VERSION ""

NS_ :

BS_:

BU_: VCU_LE CHUD_LE VKM_LE RCRM_LE VPM_LE EDI_LE V2V_LE TCP_LE CSM_LE UHP_Low_LE TouchPad_LE RSE_LE RSC_LE RSA_LE PDIM_LE OTIM_LE ICS_LE LVMPC_LE LVMNav_LE DVB_T_LE ONSTAR_LE HUD_LE IPC_LE RadioHead_LE CHM_LE Dummy_LE CGM_LE AMP_LE

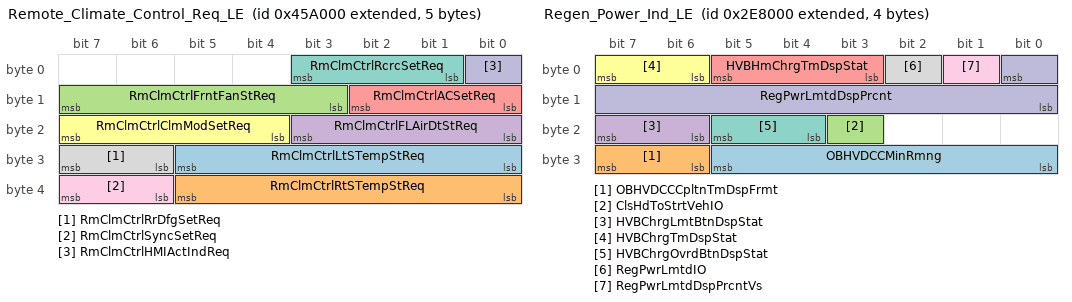
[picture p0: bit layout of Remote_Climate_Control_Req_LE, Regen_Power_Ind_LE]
BO_ 2152046592 Remote_Climate_Control_Req_LE: 5 ONSTAR_LE
 SG_ RmClmCtrlLtSTempStReq : 29|6@0+ (1,0) [0|63] ""  CGM_LE
 SG_ RmClmCtrlRtSTempStReq : 37|6@0+ (1,0) [0|63] ""  CGM_LE
 SG_ RmClmCtrlFrntFanStReq : 15|5@0+ (1,0) [0|31] ""  CGM_LE
 SG_ RmClmCtrlFLAirDtStReq : 19|4@0+ (1,0) [0|15] ""  CGM_LE
 SG_ RmClmCtrlACSetReq : 10|3@0+ (1,0) [0|7] ""  CGM_LE
 SG_ RmClmCtrlClmModSetReq : 23|4@0+ (1,0) [0|15] ""  CGM_LE
 SG_ RmClmCtrlRcrcSetReq : 3|3@0+ (1,0) [0|7] ""  CGM_LE
 SG_ RmClmCtrlRrDfgSetReq : 31|2@0+ (1,0) [0|3] ""  CGM_LE
 SG_ RmClmCtrlSyncSetReq : 39|2@0+ (1,0) [0|3] ""  CGM_LE
 SG_ RmClmCtrlHMIActIndReq : 0|1@0+ (1,0) [0|1] ""  CGM_LE

BO_ 2152030208 Tuner_Frequency_Request_LE: 8 ONSTAR_LE
 SG_ TnrFrqChnlReq : 15|56@0+ (1,0) [0|1] ""  VCU_LE,CSM_LE,RadioHead_LE
 SG_ TnrFrqBndReq : 3|4@0+ (1,0) [0|15] ""  VCU_LE,CSM_LE,RadioHead_LE

BO_ 2150531072 Regen_Power_Ind_LE: 4 CGM_LE
 SG_ OBHVDCCMinRmng : 29|6@0+ (1,0) [0|63] ""  IPC_LE,VCU_LE,RadioHead_LE
 SG_ OBHVDCCCpltnTmDspFrmt : 31|2@0+ (1,0) [0|3] ""  IPC_LE,VCU_LE,RadioHead_LE
 SG_ ClsHdToStrtVehIO : 19|1@0+ (1,0) [0|1] ""  VCU_LE,IPC_LE
 SG_ HVBChrgLmtBtnDspStat : 23|2@0+ (1,0) [0|3] ""  VCU_LE,CSM_LE,RadioHead_LE
 SG_ HVBHmChrgTmDspStat : 5|3@0+ (1,0) [0|7] ""  VCU_LE,CSM_LE,RadioHead_LE
 SG_ HVBChrgTmDspStat : 7|2@0+ (1,0) [0|3] ""  VCU_LE,CSM_LE,RadioHead_LE
 SG_ HVBChrgOvrdBtnDspStat : 21|2@0+ (1,0) [0|3] ""  VCU_LE,CSM_LE,RadioHead_LE
 SG_ RegPwrLmtdIO : 2|1@0+ (1,0) [0|1] ""  VCU_LE,IPC_LE
 SG_ RegPwrLmtdDspPrcntVs : 1|1@0+ (1,0) [0|1] ""  VCU_LE,IPC_LE
 SG_ RegPwrLmtdDspPrcnt : 0|9@0- (0.392157,0) [-100.392192|100.000035] "%"  VCU_LE,IPC_LE

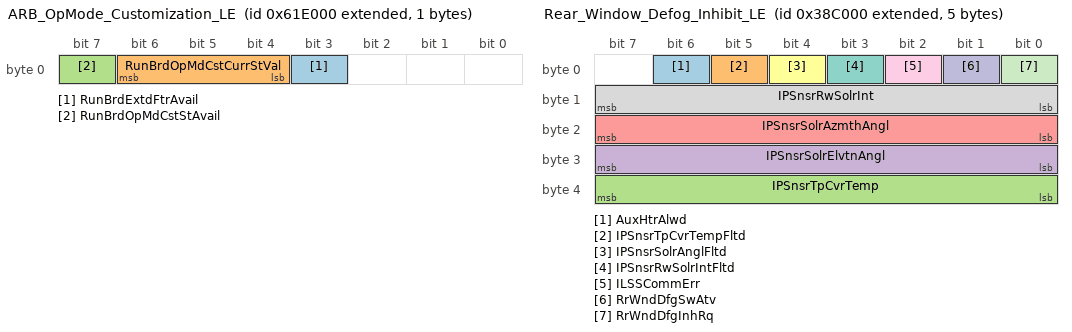
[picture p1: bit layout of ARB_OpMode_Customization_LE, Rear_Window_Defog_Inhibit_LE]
BO_ 2153897984 ARB_OpMode_Customization_LE: 1 CGM_LE
 SG_ RunBrdExtdFtrAvail : 3|1@0+ (1,0) [0|1] ""  VCU_LE,CSM_LE,RadioHead_LE
 SG_ RunBrdOpMdCstCurrStVal : 6|3@0+ (1,0) [0|7] ""  VCU_LE,CSM_LE,RadioHead_LE
 SG_ RunBrdOpMdCstStAvail : 7|1@0+ (1,0) [0|1] ""  VCU_LE,CSM_LE,RadioHead_LE

BO_ 936 Temp_Diag_CAN_Resp_LE_3A8: 8 CGM_LE
 SG_ DgnInf : 7|64@0+ (1,0) [0|1.84467440737096E+019] ""  Dummy_LE

BO_ 856 Temp_Diag_CAN_Resp_LE_358: 8 CGM_LE
 SG_ DgnInf : 7|64@0+ (1,0) [0|1.84467440737096E+019] ""  Dummy_LE

BO_ 872 Temp_Diag_CAN_Resp_LE_368: 8 CGM_LE
 SG_ DgnInf : 7|64@0+ (1,0) [0|1.84467440737096E+019] ""  Dummy_LE

BO_ 864 Temp_Diag_CAN_Resp_LE_360: 8 Dummy_LE
 SG_ DgnInf : 7|64@0+ (1,0) [0|1.84467440737096E+019] ""  CGM_LE

BO_ 921 Temp_Diag_CAN_Resp_LE_399: 8 CGM_LE
 SG_ DgnInf : 7|64@0+ (1,0) [0|1.84467440737096E+019] ""  Dummy_LE

BO_ 2151202816 Rear_Window_Defog_Inhibit_LE: 5 CGM_LE
 SG_ AuxHtrAlwd : 6|1@0+ (1,0) [0|1] ""  Dummy_LE
 SG_ IPSnsrTpCvrTempFltd : 5|1@0+ (1,0) [0|1] ""  Dummy_LE
 SG_ IPSnsrTpCvrTemp : 39|8@0+ (0.5,-40) [-40|87.5] "deg C"  Dummy_LE
 SG_ IPSnsrSolrElvtnAngl : 31|8@0+ (1,0) [0|255] "deg"  Dummy_LE
 SG_ IPSnsrSolrAzmthAngl : 23|8@0+ (2,-180) [-180|330] "deg"  Dummy_LE
 SG_ IPSnsrSolrAnglFltd : 4|1@0+ (1,0) [0|1] ""  Dummy_LE
 SG_ IPSnsrRwSolrIntFltd : 3|1@0+ (1,0) [0|1] ""  Dummy_LE
 SG_ IPSnsrRwSolrInt : 15|8@0+ (3,0) [0|765] "W/m2"  Dummy_LE
 SG_ ILSSCommErr : 2|1@0+ (1,0) [0|1] ""  Dummy_LE
 SG_ RrWndDfgSwAtv : 1|1@0+ (1,0) [0|1] ""  VCU_LE,IPC_LE
 SG_ RrWndDfgInhRq : 0|1@0+ (1,0) [0|1] ""  Dummy_LE

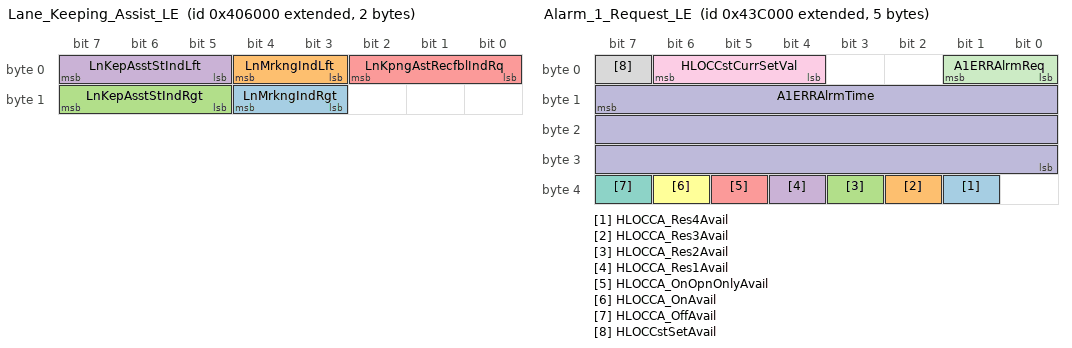
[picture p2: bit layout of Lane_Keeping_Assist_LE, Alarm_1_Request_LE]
BO_ 2151702528 Lane_Keeping_Assist_LE: 2 CGM_LE
 SG_ LnMrkngIndRgt : 12|2@0+ (1,0) [0|3] ""  VCU_LE,IPC_LE
 SG_ LnMrkngIndLft : 4|2@0+ (1,0) [0|3] ""  VCU_LE,IPC_LE
 SG_ LnKepAsstStIndRgt : 15|3@0+ (1,0) [0|7] ""  VCU_LE,IPC_LE
 SG_ LnKepAsstStIndLft : 7|3@0+ (1,0) [0|7] ""  VCU_LE,IPC_LE
 SG_ LnKpngAstRecfblIndRq : 2|3@0+ (1,0) [0|7] ""  VCU_LE,IPC_LE

BO_ 2156978176 PassPhrase_2_AMM_LE: 8 ONSTAR_LE
 SG_ WiFiPssPhrsDgts9to16_Mp : 7|64@0+ (1,0) [0|0] ""  CGM_LE

BO_ 2156969984 PassPhrase_1_AMM_LE: 8 ONSTAR_LE
 SG_ WiFiPssPhrsDgts1to8_Mp : 7|64@0+ (1,0) [0|0] ""  CGM_LE

BO_ 2156961792 SSID_AMM_3_LE: 8 ONSTAR_LE
 SG_ WiFiSSIDDgts17to24_Mp : 7|64@0+ (1,0) [0|0] ""  CGM_LE

BO_ 2151923712 Alarm_1_Request_LE: 5 CGM_LE
 SG_ HLOCCA_Res4Avail : 33|1@0+ (1,0) [0|1] ""  VCU_LE,CSM_LE,RadioHead_LE
 SG_ HLOCCA_Res3Avail : 34|1@0+ (1,0) [0|1] ""  VCU_LE,CSM_LE,RadioHead_LE
 SG_ HLOCCA_Res2Avail : 35|1@0+ (1,0) [0|1] ""  VCU_LE,CSM_LE,RadioHead_LE
 SG_ HLOCCA_Res1Avail : 36|1@0+ (1,0) [0|1] ""  VCU_LE,CSM_LE,RadioHead_LE
 SG_ HLOCCA_OnOpnOnlyAvail : 37|1@0+ (1,0) [0|1] ""  VCU_LE,CSM_LE,RadioHead_LE
 SG_ HLOCCA_OnAvail : 38|1@0+ (1,0) [0|1] ""  VCU_LE,CSM_LE,RadioHead_LE
 SG_ HLOCCA_OffAvail : 39|1@0+ (1,0) [0|1] ""  VCU_LE,CSM_LE,RadioHead_LE
 SG_ HLOCCstSetAvail : 7|1@0+ (1,0) [0|1] ""  VCU_LE,CSM_LE,RadioHead_LE
 SG_ HLOCCstCurrSetVal : 6|3@0+ (1,0) [0|7] ""  VCU_LE,CSM_LE,RadioHead_LE
 SG_ A1ERRAlrmTime : 15|24@0+ (1,0) [0|16777215] "min"  Dummy_LE
 SG_ A1ERRAlrmReq : 1|2@0+ (1,0) [0|3] ""  Dummy_LE

BO_ 2150236160 Unlock_Key_Store_Crypt_2_LE: 8 CGM_LE
 SG_ UlckKyStrCrptoDt2M : 4|1@0+ (1,0) [0|1] ""  CSM_LE
 SG_ UlckKyStrCrptoDt2 : 3|60@0+ (1,0) [0|1.15292150460685E+018] ""  CSM_LE

BO_ 2150170624 Unlock_Key_Store_Crypt_1_LE: 8 CGM_LE
 SG_ UlckKyStrCrptoDt1M : 4|1@0+ (1,0) [0|1] ""  CSM_LE
 SG_ UlckKyStrCrptoDt1 : 3|60@0+ (1,0) [0|1.15292150460685E+018] ""  CSM_LE

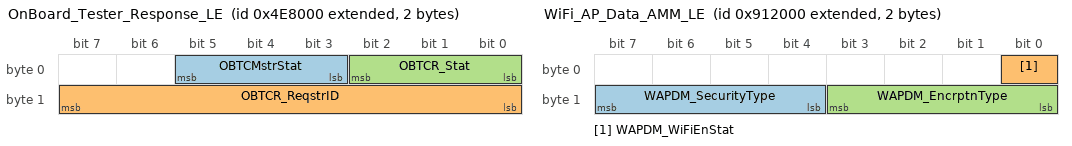
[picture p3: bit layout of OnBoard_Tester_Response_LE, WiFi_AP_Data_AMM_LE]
BO_ 2152628224 OnBoard_Tester_Response_LE: 2 TCP_LE
 SG_ OBTCMstrStat : 5|3@0+ (1,0) [0|7] ""  CSM_LE
 SG_ OBTCR_ReqstrID : 15|8@0+ (1,0) [0|255] ""  CSM_LE
 SG_ OBTCR_Stat : 2|3@0+ (1,0) [0|7] ""  CSM_LE

BO_ 2154725376 Auxiliary_Heater_LE: 1 CGM_LE
 SG_ AuxHtrAtv378 : 6|1@0+ (1,0) [0|1] ""  RSC_LE,Dummy_LE
 SG_ AuxHtrRq : 7|1@0+ (1,0) [0|1] ""  RSC_LE,Dummy_LE

BO_ 2157051904 WiFi_Station_AMM_LE: 5 CGM_LE
 SG_ WSMR_WiFiStnMpMACAddr : 15|32@0+ (1,0) [0|4294967295] ""  CSM_LE,ONSTAR_LE
 SG_ WSMR_WiFiAssnReq : 1|2@0+ (1,0) [0|3] ""  CSM_LE,ONSTAR_LE

BO_ 2156994560 WiFi_AP_Data_AMM_LE: 2 ONSTAR_LE
 SG_ WAPDM_SecurityType : 15|4@0+ (1,0) [0|15] ""  CGM_LE
 SG_ WAPDM_WiFiEnStat : 0|1@0+ (1,0) [0|1] ""  CGM_LE
 SG_ WAPDM_EncrptnType : 11|4@0+ (1,0) [0|15] ""  CGM_LE

BO_ 2156986368 PassPhrase_3_AMM_LE: 8 ONSTAR_LE
 SG_ WiFiPssPhrsDgts17to24_Mp : 7|64@0+ (1,0) [0|0] ""  CGM_LE

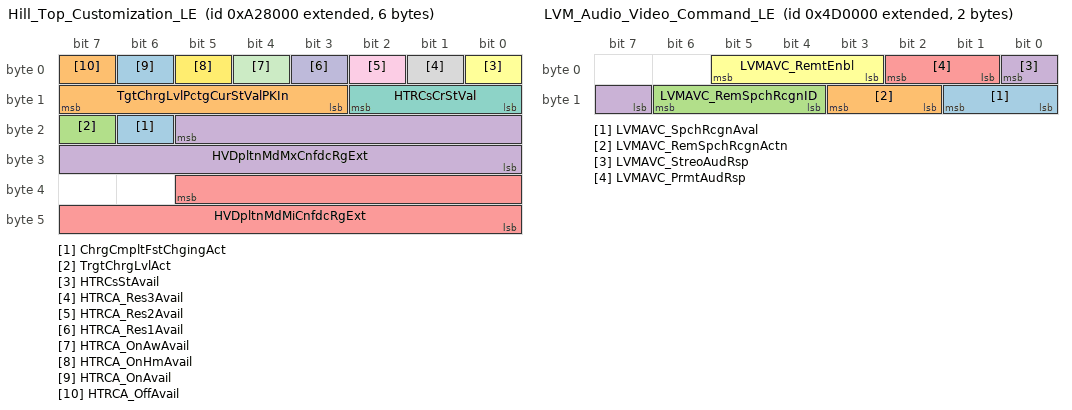
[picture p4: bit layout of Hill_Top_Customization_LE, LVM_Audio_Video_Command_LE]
BO_ 2158133248 Hill_Top_Customization_LE: 6 CGM_LE
 SG_ ChrgCmpltFstChgingAct : 22|1@0+ (1,0) [0|1] ""  CSM_LE,RadioHead_LE,VCU_LE,IPC_LE
 SG_ TgtChrgLvlPctgCurStValPKIn : 15|5@0+ (1,0) [0|20] ""  VCU_LE,IPC_LE
 SG_ TrgtChrgLvlAct : 23|1@0+ (1,0) [0|1] ""  VCU_LE,IPC_LE
 SG_ HVDpltnMdMxCnfdcRgExt : 21|14@0+ (0.1,0) [0|1638.3] "km"  TCP_LE,ONSTAR_LE,VCU_LE,IPC_LE
 SG_ HVDpltnMdMiCnfdcRgExt : 37|14@0+ (0.1,0) [0|1638.3] "km"  TCP_LE,ONSTAR_LE,VCU_LE,IPC_LE
 SG_ HTRCsStAvail : 0|1@0+ (1,0) [0|1] ""  VCU_LE,CSM_LE,RadioHead_LE
 SG_ HTRCsCrStVal : 10|3@0+ (1,0) [0|7] ""  VCU_LE,CSM_LE,RadioHead_LE
 SG_ HTRCA_Res3Avail : 1|1@0+ (1,0) [0|1] ""  VCU_LE,CSM_LE,RadioHead_LE
 SG_ HTRCA_Res2Avail : 2|1@0+ (1,0) [0|1] ""  VCU_LE,CSM_LE,RadioHead_LE
 SG_ HTRCA_Res1Avail : 3|1@0+ (1,0) [0|1] ""  VCU_LE,CSM_LE,RadioHead_LE
 SG_ HTRCA_OnAwAvail : 4|1@0+ (1,0) [0|1] ""  VCU_LE,CSM_LE,RadioHead_LE
 SG_ HTRCA_OnHmAvail : 5|1@0+ (1,0) [0|1] ""  VCU_LE,CSM_LE,RadioHead_LE
 SG_ HTRCA_OnAvail : 6|1@0+ (1,0) [0|1] ""  VCU_LE,CSM_LE,RadioHead_LE
 SG_ HTRCA_OffAvail : 7|1@0+ (1,0) [0|1] ""  VCU_LE,CSM_LE,RadioHead_LE

BO_ 2154651648 Telematics_Audio_Control_LE: 1 CSM_LE
 SG_ TAC_AudConctOutcm : 3|4@0+ (1,0) [0|15] ""  VPM_LE,TCP_LE
 SG_ TAC_AudChConctStat : 7|4@0+ (1,0) [0|15] ""  VPM_LE,TCP_LE

BO_ 2154635264 Telematics_Audio_Request_LE: 1 TCP_LE
 SG_ TAR_AudSrcStat : 3|4@0+ (1,0) [0|15] ""  VCU_LE,VPM_LE,CSM_LE
 SG_ TAR_AudConctReq : 7|4@0+ (1,0) [0|15] ""  VCU_LE,VPM_LE,CSM_LE

BO_ 2152529920 LVM_Audio_Video_Command_LE: 2 CSM_LE
 SG_ LVMAVC_SpchRcgnAval : 9|2@0+ (1,0) [0|3] ""  LVMPC_LE,LVMNav_LE
 SG_ LVMAVC_RemSpchRcgnActn : 11|2@0+ (1,0) [0|3] ""  LVMPC_LE,LVMNav_LE
 SG_ LVMAVC_RemSpchRcgnID : 14|3@0+ (1,0) [0|7] ""  LVMPC_LE,LVMNav_LE
 SG_ LVMAVC_StreoAudRsp : 0|2@0+ (1,0) [0|3] ""  LVMPC_LE,LVMNav_LE
 SG_ LVMAVC_PrmtAudRsp : 2|2@0+ (1,0) [0|3] ""  LVMPC_LE,LVMNav_LE
 SG_ LVMAVC_RemtEnbl : 5|3@0+ (1,0) [0|7] ""  LVMPC_LE,LVMNav_LE

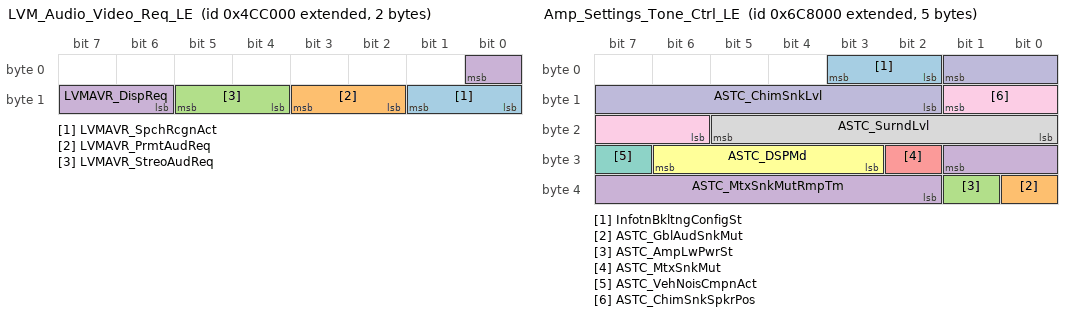
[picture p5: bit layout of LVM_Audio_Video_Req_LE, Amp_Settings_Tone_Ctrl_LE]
BO_ 2152513536 LVM_Audio_Video_Req_LE: 2 LVMNav_LE
 SG_ LVMAVR_SpchRcgnAct : 9|2@0+ (1,0) [0|3] ""  CSM_LE
 SG_ LVMAVR_PrmtAudReq : 11|2@0+ (1,0) [0|3] ""  CSM_LE
 SG_ LVMAVR_StreoAudReq : 13|2@0+ (1,0) [0|3] ""  CSM_LE
 SG_ LVMAVR_DispReq : 0|3@0+ (1,0) [0|7] ""  CSM_LE

BO_ 2154889216 Cluster_HMI_Animation_Req_LE: 1 CSM_LE
 SG_ RSIHMIAnmReq : 4|3@0+ (1,0) [0|7] ""  RSE_LE
 SG_ ClstrHMIAnmReq : 7|3@0+ (1,0) [0|7] ""  VCU_LE,IPC_LE

BO_ 2154872832 Infotainment_Activation_Req_LE: 1 TCP_LE
 SG_ RmRflshUpdtAvail : 6|1@0+ (1,0) [0|1] ""  VCU_LE,CSM_LE
 SG_ InfoActvnReq : 7|1@0+ (1,0) [0|1] ""  VCU_LE,CSM_LE

BO_ 2154569728 Infotainment_System_State_LE: 1 CSM_LE
 SG_ InfotnmntSysSt : 7|5@0+ (1,0) [0|31] ""  CHUD_LE,CGM_LE,VCU_LE,TouchPad_LE,RSE_LE,RSC_LE,ICS_LE,LVMPC_LE,LVMNav_LE,IPC_LE,AMP_LE,TCP_LE

BO_ 2154594304 Amp_Settings_Tone_Ctrl_LE: 5 CSM_LE
 SG_ InfotnBkltngConfigSt : 3|2@0+ (1,0) [0|3] ""  RSE_LE,TouchPad_LE
 SG_ ASTC_GblAudSnkMut : 32|1@0+ (1,0) [0|1] ""  AMP_LE
 SG_ ASTC_AmpLwPwrSt : 33|1@0+ (1,0) [0|1] ""  AMP_LE
 SG_ ASTC_MtxSnkMutRmpTm : 25|8@0+ (5,0) [0|1275] "ms"  AMP_LE
 SG_ ASTC_MtxSnkMut : 26|1@0+ (1,0) [0|1] ""  AMP_LE
 SG_ ASTC_DSPMd : 30|4@0+ (1,0) [0|15] ""  AMP_LE
 SG_ ASTC_VehNoisCmpnAct : 31|1@0+ (1,0) [0|1] ""  AMP_LE
 SG_ ASTC_SurndLvl : 21|6@0- (1,0) [-32|31] ""  AMP_LE
 SG_ ASTC_ChimSnkSpkrPos : 9|4@0+ (1,0) [0|15] ""  AMP_LE
 SG_ ASTC_ChimSnkLvl : 1|8@0+ (0.5,-127.5) [-127.5|0] "dB"  AMP_LE

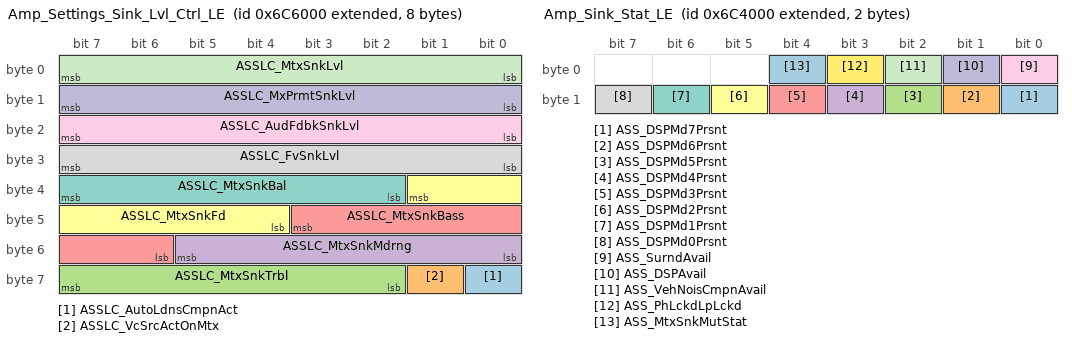
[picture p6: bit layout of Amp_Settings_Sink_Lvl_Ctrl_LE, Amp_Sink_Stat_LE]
BO_ 2154586112 Amp_Settings_Sink_Lvl_Ctrl_LE: 8 CSM_LE
 SG_ ASSLC_AutoLdnsCmpnAct : 56|1@0+ (1,0) [0|1] ""  AMP_LE
 SG_ ASSLC_VcSrcActOnMtx : 57|1@0+ (1,0) [0|1] ""  AMP_LE
 SG_ ASSLC_MtxSnkTrbl : 63|6@0- (1,0) [-32|31] ""  AMP_LE
 SG_ ASSLC_MtxSnkMdrng : 53|6@0- (1,0) [-32|31] ""  AMP_LE
 SG_ ASSLC_MtxSnkBass : 43|6@0- (1,0) [-32|31] ""  AMP_LE
 SG_ ASSLC_MtxSnkFd : 33|6@0- (1,0) [-32|31] ""  AMP_LE
 SG_ ASSLC_MtxSnkBal : 39|6@0- (1,0) [-32|31] ""  AMP_LE
 SG_ ASSLC_FvSnkLvl : 31|8@0+ (0.5,-127.5) [-127.5|0] "dB"  AMP_LE
 SG_ ASSLC_AudFdbkSnkLvl : 23|8@0+ (0.5,-127.5) [-127.5|0] "dB"  AMP_LE
 SG_ ASSLC_MxPrmtSnkLvl : 15|8@0+ (0.5,-127.5) [-127.5|0] "dB"  AMP_LE
 SG_ ASSLC_MtxSnkLvl : 7|8@0+ (0.5,-127.5) [-127.5|0] "dB"  AMP_LE

BO_ 2154577920 Amp_Sink_Stat_LE: 2 AMP_LE
 SG_ ASS_DSPMd7Prsnt : 8|1@0+ (1,0) [0|1] ""  CSM_LE
 SG_ ASS_DSPMd6Prsnt : 9|1@0+ (1,0) [0|1] ""  CSM_LE
 SG_ ASS_DSPMd5Prsnt : 10|1@0+ (1,0) [0|1] ""  CSM_LE
 SG_ ASS_DSPMd4Prsnt : 11|1@0+ (1,0) [0|1] ""  CSM_LE
 SG_ ASS_DSPMd3Prsnt : 12|1@0+ (1,0) [0|1] ""  CSM_LE
 SG_ ASS_DSPMd2Prsnt : 13|1@0+ (1,0) [0|1] ""  CSM_LE
 SG_ ASS_DSPMd1Prsnt : 14|1@0+ (1,0) [0|1] ""  CSM_LE
 SG_ ASS_DSPMd0Prsnt : 15|1@0+ (1,0) [0|1] ""  CSM_LE
 SG_ ASS_SurndAvail : 0|1@0+ (1,0) [0|1] ""  CSM_LE
 SG_ ASS_DSPAvail : 1|1@0+ (1,0) [0|1] ""  CSM_LE
 SG_ ASS_VehNoisCmpnAvail : 2|1@0+ (1,0) [0|1] ""  CSM_LE
 SG_ ASS_PhLckdLpLckd : 3|1@0+ (1,0) [0|1] ""  CSM_LE
 SG_ ASS_MtxSnkMutStat : 4|1@0+ (1,0) [0|1] ""  CSM_LE

BO_ 2151931904 Custom_Launch_Ctrl_LE: 8 CGM_LE
 SG_ FourWhlDrvIdReqExtRng : 59|4@0+ (1,0) [0|15] ""  VCU_LE,IPC_LE
 SG_ LnchCtrlTmrVal : 35|4@0+ (1,0) [0|15] ""  VCU_LE,IPC_LE
 SG_ LnchCtrlBrkPresVal : 47|4@0+ (10,0) [0|150] "%"  VCU_LE,IPC_LE
 SG_ FuelMdTrnstnIndReq : 63|4@0+ (1,0) [0|15] ""  VCU_LE,IPC_LE
 SG_ BiFuelRflGaslinIndReq : 42|3@0+ (1,0) [0|7] ""  VCU_LE,IPC_LE
 SG_ AutoShtdwnTmr : 55|8@0+ (1,0) [0|255] "min"  VCU_LE,IPC_LE
 SG_ AutoShtdwnIO : 43|1@0+ (1,0) [0|1] ""  VCU_LE,IPC_LE
 SG_ TCSTempDsblReqIO : 24|1@0+ (1,0) [0|1] ""  VCU_LE,IPC_LE
 SG_ VehStbCmptvMdCstAvl : 25|1@0+ (1,0) [0|1] ""  VCU_LE,IPC_LE
 SG_ VehStbEnmntCstAvl : 26|1@0+ (1,0) [0|1] ""  VCU_LE,IPC_LE
 SG_ TCSysCstAvl : 27|1@0+ (1,0) [0|1] ""  VCU_LE,IPC_LE
 SG_ VehStbCmptvMdCurSt : 28|1@0+ (1,0) [0|1] ""  VCU_LE,IPC_LE
 SG_ VehStbEnhmntCurSt : 36|1@0+ (1,0) [0|1] ""  VCU_LE,IPC_LE
 SG_ TCSysCurSt : 37|1@0+ (1,0) [0|1] ""  VCU_LE,IPC_LE
 SG_ TracAndStbScrnCnfg : 39|2@0+ (1,0) [0|3] ""  VCU_LE,IPC_LE
 SG_ ElctShfPriLtdPerfMdIO : 29|1@0+ (1,0) [0|1] ""  VCU_LE,IPC_LE
 SG_ LnchCtrlEngRPMStat : 15|6@0+ (1,0) [0|63] ""  VCU_LE,IPC_LE
 SG_ RegVltCtlEngyRcvryAct : 30|1@0+ (1,0) [0|1] ""  VCU_LE,IPC_LE
 SG_ VehSpdCntlSystmType : 20|3@0+ (1,0) [0|7] ""  V2V_LE,VCU_LE,IPC_LE
 SG_ ACCSysSltdMdDispIO : 31|1@0+ (1,0) [0|1] ""  V2V_LE,VCU_LE,IPC_LE
 SG_ ACCSysSltdMd : 17|2@0+ (1,0) [0|3] ""  V2V_LE,VCU_LE,IPC_LE
 SG_ PTExPrtclFltWrng3IO : 8|1@0+ (1,0) [0|1] ""  VCU_LE,IPC_LE
 SG_ PTExPartFltManRegStat : 23|3@0+ (1,0) [0|7] ""  VCU_LE,IPC_LE
 SG_ LnchCtrlWhlSlpStat : 7|5@0+ (1,0) [0|31] ""  VCU_LE,IPC_LE
 SG_ LnchCtrlMdStat : 2|3@0+ (1,0) [0|7] ""  VCU_LE,IPC_LE
 SG_ AWDRecmndIO : 9|1@0+ (1,0) [0|1] ""  VCU_LE,IPC_LE

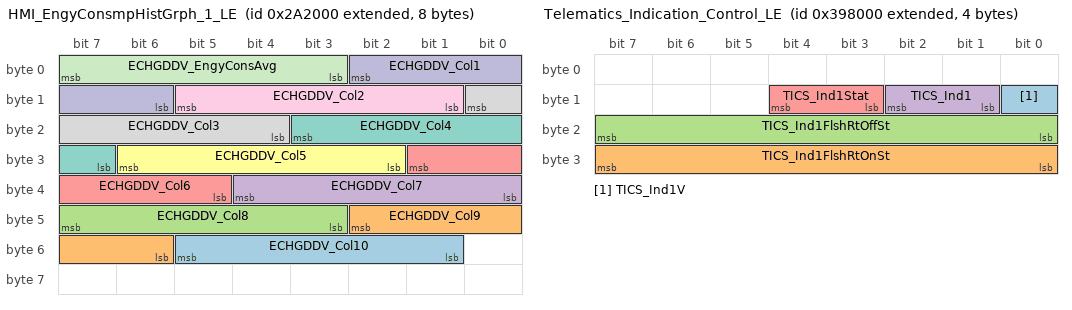
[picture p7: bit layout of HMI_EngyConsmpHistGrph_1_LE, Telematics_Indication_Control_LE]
BO_ 2150244352 HMI_EngyConsmpHistGrph_1_LE: 8 CGM_LE
 SG_ ECHGDDV_Col10 : 53|5@0+ (1,0) [0|31] ""  VCU_LE,CSM_LE,RadioHead_LE
 SG_ ECHGDDV_Col9 : 42|5@0+ (1,0) [0|31] ""  VCU_LE,CSM_LE,RadioHead_LE
 SG_ ECHGDDV_Col8 : 47|5@0+ (1,0) [0|31] ""  VCU_LE,CSM_LE,RadioHead_LE
 SG_ ECHGDDV_Col7 : 36|5@0+ (1,0) [0|31] ""  VCU_LE,CSM_LE,RadioHead_LE
 SG_ ECHGDDV_Col6 : 25|5@0+ (1,0) [0|31] ""  VCU_LE,CSM_LE,RadioHead_LE
 SG_ ECHGDDV_Col5 : 30|5@0+ (1,0) [0|31] ""  VCU_LE,CSM_LE,RadioHead_LE
 SG_ ECHGDDV_Col4 : 19|5@0+ (1,0) [0|31] ""  VCU_LE,CSM_LE,RadioHead_LE
 SG_ ECHGDDV_Col3 : 8|5@0+ (1,0) [0|31] ""  VCU_LE,CSM_LE,RadioHead_LE
 SG_ ECHGDDV_Col2 : 13|5@0+ (1,0) [0|31] ""  VCU_LE,CSM_LE,RadioHead_LE
 SG_ ECHGDDV_Col1 : 2|5@0+ (1,0) [0|31] ""  VCU_LE,CSM_LE,RadioHead_LE
 SG_ ECHGDDV_EngyConsAvg : 7|5@0+ (1,0) [0|31] ""  VCU_LE,CSM_LE,RadioHead_LE

BO_ 2156953600 SSID_AMM_2_LE: 8 ONSTAR_LE
 SG_ WiFiSSIDDgts9to16_Mp : 7|64@0+ (1,0) [0|0] ""  CGM_LE

BO_ 1363 UUDT_Resp_From_TIM_CGM_LE: 8 CGM_LE
 SG_ DgnInf_LS553 : 7|64@0+ (1,0) [0|1.84467440737096E+019] ""  CSM_LE,TCP_LE,ONSTAR_LE

BO_ 1619 USDT_Resp_From_TIM_CGM_LE: 8 CGM_LE
 SG_ DgnInf : 7|64@0+ (1,0) [0|1.84467440737096E+019] ""  CSM_LE,TCP_LE,ONSTAR_LE

BO_ 597 USDT_Req_to_VIS2_LE: 8 ONSTAR_LE
 SG_ DgnInf : 7|64@0+ (1,0) [0|1.84467440737096E+019] ""  TCP_LE,ONSTAR_LE,CGM_LE

BO_ 2020 USDT_Req_to_VICM_LE: 8 ONSTAR_LE
 SG_ DgnInf : 7|64@0+ (1,0) [0|1.84467440737096E+019] ""  TCP_LE,ONSTAR_LE,CGM_LE

BO_ 601 USDT_Req_to_UPA_APA_LE: 8 ONSTAR_LE
 SG_ DgnInf : 7|64@0+ (1,0) [0|1.84467440737096E+019] ""  TCP_LE,ONSTAR_LE,CGM_LE

BO_ 583 USDT_Req_to_SDM_LE: 8 ONSTAR_LE
 SG_ DgnInf : 7|64@0+ (1,0) [0|1.84467440737096E+019] ""  TCP_LE,ONSTAR_LE,CGM_LE

BO_ 604 USDT_Req_to_SCL_LE: 8 ONSTAR_LE
 SG_ DgnInf : 7|64@0+ (1,0) [0|1.84467440737096E+019] ""  TCP_LE,ONSTAR_LE,CGM_LE

BO_ 599 USDT_Req_to_SBZA_R_LE: 8 ONSTAR_LE
 SG_ DgnInf : 7|64@0+ (1,0) [0|1.84467440737096E+019] ""  TCP_LE,ONSTAR_LE,CGM_LE

BO_ 602 USDT_Req_to_SBZA_L_LE: 8 ONSTAR_LE
 SG_ DgnInf : 7|64@0+ (1,0) [0|1.84467440737096E+019] ""  TCP_LE,ONSTAR_LE,CGM_LE

BO_ 591 USDT_Req_to_PTM_STC_LE: 8 ONSTAR_LE
 SG_ DgnInf : 7|64@0+ (1,0) [0|1.84467440737096E+019] ""  TCP_LE,ONSTAR_LE,CGM_LE

BO_ 578 USDT_Req_to_PEPS_PBSM_LE: 8 ONSTAR_LE
 SG_ DgnInf : 7|64@0+ (1,0) [0|1.84467440737096E+019] ""  TCP_LE,ONSTAR_LE,CGM_LE

BO_ 600 USDT_Req_to_HVSM_R_LE: 8 ONSTAR_LE
 SG_ DgnInf : 7|64@0+ (1,0) [0|1.84467440737096E+019] ""  TCP_LE,ONSTAR_LE,CGM_LE

BO_ 607 USDT_Req_to_HBSM_LE: 8 ONSTAR_LE
 SG_ DgnInf : 7|64@0+ (1,0) [0|1.84467440737096E+019] ""  TCP_LE,ONSTAR_LE,RCRM_LE,CGM_LE

BO_ 587 USDT_Req_to_FCM_LE: 8 ONSTAR_LE
 SG_ DgnInf : 7|64@0+ (1,0) [0|1.84467440737096E+019] ""  TCP_LE,ONSTAR_LE,CGM_LE

BO_ 593 USDT_Req_to_ECC_HVAC_LE: 8 ONSTAR_LE
 SG_ DgnInf : 7|64@0+ (1,0) [0|1.84467440737096E+019] ""  TCP_LE,ONSTAR_LE,CGM_LE

BO_ 605 USDT_Req_to_DSM_LE: 8 ONSTAR_LE
 SG_ DgnInf : 7|64@0+ (1,0) [0|1.84467440737096E+019] ""  TCP_LE,ONSTAR_LE,CGM_LE

BO_ 577 USDT_Req_to_BCM_LE: 8 ONSTAR_LE
 SG_ DgnInf : 7|64@0+ (1,0) [0|1.84467440737096E+019] ""  TCP_LE,ONSTAR_LE,CGM_LE

BO_ 603 USDT_Req_to_ARB_LE: 8 ONSTAR_LE
 SG_ DgnInf : 7|64@0+ (1,0) [0|1.84467440737096E+019] ""  TCP_LE,ONSTAR_LE,V2V_LE,CGM_LE

BO_ 581 USDT_Req_to_AOS_LE: 8 ONSTAR_LE
 SG_ DgnInf : 7|64@0+ (1,0) [0|1.84467440737096E+019] ""  TCP_LE,ONSTAR_LE,CGM_LE

BO_ 606 USDT_Req_to_AHS_LE: 8 ONSTAR_LE
 SG_ DgnInf : 7|64@0+ (1,0) [0|1.84467440737096E+019] ""  TCP_LE,ONSTAR_LE,CGM_LE

BO_ 579 USDT_Req_to_AGC_LE: 8 ONSTAR_LE
 SG_ DgnInf : 7|64@0+ (1,0) [0|1.84467440737096E+019] ""  TCP_LE,ONSTAR_LE,CGM_LE

BO_ 1621 USDT_Resp_From_VIS2_LE: 8 CGM_LE
 SG_ DgnInf : 7|64@0+ (1,0) [0|1.84467440737096E+019] ""  CSM_LE,TCP_LE,ONSTAR_LE

BO_ 2028 USDT_Resp_From_VICM_LE: 8 CGM_LE
 SG_ DgnInf : 7|64@0+ (1,0) [0|1.84467440737096E+019] ""  CSM_LE,TCP_LE,ONSTAR_LE

BO_ 1625 USDT_Resp_From_UPA_APA_LE: 8 CGM_LE
 SG_ DgnInf : 7|64@0+ (1,0) [0|1.84467440737096E+019] ""  CSM_LE,TCP_LE,ONSTAR_LE

BO_ 1607 USDT_Resp_From_SDM_LE: 8 CGM_LE
 SG_ DgnInf : 7|64@0+ (1,0) [0|1.84467440737096E+019] ""  CSM_LE,TCP_LE,ONSTAR_LE

BO_ 1628 USDT_Resp_From_SCL_LE: 8 CGM_LE
 SG_ DgnInf : 7|64@0+ (1,0) [0|1.84467440737096E+019] ""  CSM_LE,TCP_LE,ONSTAR_LE

BO_ 1623 USDT_Resp_From_SBZA_R_LE: 8 CGM_LE
 SG_ DgnInf : 7|64@0+ (1,0) [0|1.84467440737096E+019] ""  CSM_LE,TCP_LE,ONSTAR_LE

BO_ 1626 USDT_Resp_From_SBZA_L_LE: 8 CGM_LE
 SG_ DgnInf : 7|64@0+ (1,0) [0|1.84467440737096E+019] ""  CSM_LE,TCP_LE,ONSTAR_LE

BO_ 1615 USDT_Resp_From_PTM_STC_LE: 8 CGM_LE
 SG_ DgnInf : 7|64@0+ (1,0) [0|1.84467440737096E+019] ""  CSM_LE,TCP_LE,ONSTAR_LE

BO_ 1602 USDT_Resp_From_PEPS_PBSM_LE: 8 CGM_LE
 SG_ DgnInf : 7|64@0+ (1,0) [0|1.84467440737096E+019] ""  CSM_LE,TCP_LE,ONSTAR_LE

BO_ 1624 USDT_Resp_From_HVSM_R_LE: 8 CGM_LE
 SG_ DgnInf : 7|64@0+ (1,0) [0|1.84467440737096E+019] ""  CSM_LE,TCP_LE,ONSTAR_LE

BO_ 1631 USDT_Resp_From_HBSM_LE: 8 CGM_LE
 SG_ DgnInf : 7|64@0+ (1,0) [0|1.84467440737096E+019] ""  CGM_LE,CSM_LE,TCP_LE,ONSTAR_LE

BO_ 1611 USDT_Resp_From_FCM_LE: 8 CGM_LE
 SG_ DgnInf : 7|64@0+ (1,0) [0|1.84467440737096E+019] ""  CSM_LE,TCP_LE,ONSTAR_LE

BO_ 1617 USDT_Resp_From_ECC_HVAC_LE: 8 CGM_LE
 SG_ DgnInf : 7|64@0+ (1,0) [0|1.84467440737096E+019] ""  CSM_LE,TCP_LE,ONSTAR_LE

BO_ 1629 USDT_Resp_From_DSM_LE: 8 CGM_LE
 SG_ DgnInf : 7|64@0+ (1,0) [0|1.84467440737096E+019] ""  CSM_LE,TCP_LE,ONSTAR_LE

BO_ 1601 USDT_Resp_From_BCM_LE: 8 CGM_LE
 SG_ DgnInf : 7|64@0+ (1,0) [0|1.84467440737096E+019] ""  CSM_LE,TCP_LE,ONSTAR_LE

BO_ 1627 USDT_Resp_From_ARB_LE: 8 CGM_LE
 SG_ DgnInf : 7|64@0+ (1,0) [0|1.84467440737096E+019] ""  CGM_LE,CSM_LE,TCP_LE,ONSTAR_LE

BO_ 1605 USDT_Resp_From_AOS_LE: 8 CGM_LE
 SG_ DgnInf : 7|64@0+ (1,0) [0|1.84467440737096E+019] ""  CSM_LE,TCP_LE,ONSTAR_LE

BO_ 1630 USDT_Resp_From_AHS_LE: 8 CGM_LE
 SG_ DgnInf : 7|64@0+ (1,0) [0|1.84467440737096E+019] ""  CSM_LE,TCP_LE,ONSTAR_LE

BO_ 1603 USDT_Resp_From_AGC_LE: 8 CGM_LE
 SG_ DgnInf : 7|64@0+ (1,0) [0|1.84467440737096E+019] ""  CSM_LE,TCP_LE,ONSTAR_LE

BO_ 1365 UUDT_Resp_From_VIS2_LE: 8 CGM_LE
 SG_ DgnInf_LS555 : 7|64@0+ (1,0) [0|1.84467440737096E+019] ""  CSM_LE,TCP_LE,ONSTAR_LE

BO_ 1516 UUDT_Resp_From_VICM_LE: 8 CGM_LE
 SG_ DgnInf_LS5EC : 7|64@0+ (1,0) [0|1.84467440737096E+019] ""  CSM_LE,TCP_LE,ONSTAR_LE

BO_ 1369 UUDT_Resp_From_UPA_APA_LE: 8 CGM_LE
 SG_ DgnInf_LS559 : 7|64@0+ (1,0) [0|1.84467440737096E+019] ""  CSM_LE,TCP_LE,ONSTAR_LE

BO_ 1351 UUDT_Resp_From_SDM_LE: 8 CGM_LE
 SG_ DgnInf_LS547 : 7|64@0+ (1,0) [0|1.84467440737096E+019] ""  CSM_LE,TCP_LE,ONSTAR_LE

BO_ 1372 UUDT_Resp_From_SCL_LE: 8 CGM_LE
 SG_ DgnInf_LS55C : 7|64@0+ (1,0) [0|1.84467440737096E+019] ""  CSM_LE,TCP_LE,ONSTAR_LE

BO_ 1367 UUDT_Resp_From_SBZA_R_LE: 8 CGM_LE
 SG_ DgnInf_LS557 : 7|64@0+ (1,0) [0|1.84467440737096E+019] ""  CSM_LE,TCP_LE,ONSTAR_LE

BO_ 1370 UUDT_Resp_From_SBZA_L_LE: 8 CGM_LE
 SG_ DgnInf_LS55A : 7|64@0+ (1,0) [0|1.84467440737096E+019] ""  CSM_LE,TCP_LE,ONSTAR_LE

BO_ 1359 UUDT_Resp_From_PTM_STC_LE: 8 CGM_LE
 SG_ DgnInf_LS54F : 7|64@0+ (1,0) [0|1.84467440737096E+019] ""  CSM_LE,TCP_LE,ONSTAR_LE

BO_ 1346 UUDT_Resp_From_PEPS_PBSM_LE: 8 CGM_LE
 SG_ DgnInf_LS542 : 7|64@0+ (1,0) [0|1.84467440737096E+019] ""  CSM_LE,TCP_LE,ONSTAR_LE

BO_ 1368 UUDT_Resp_From_HVSM_R_LE: 8 CGM_LE
 SG_ DgnInf_LS558 : 7|64@0+ (1,0) [0|1.84467440737096E+019] ""  CSM_LE,TCP_LE,ONSTAR_LE

BO_ 1375 UUDT_Resp_From_HBSM_LE: 8 CGM_LE
 SG_ DgnInf_LS55F : 7|64@0+ (1,0) [0|1.84467440737096E+019] ""  CGM_LE,CSM_LE,TCP_LE,ONSTAR_LE

BO_ 1355 UUDT_Resp_From_FCM_LE: 8 CGM_LE
 SG_ DgnInf_LS54B : 7|64@0+ (1,0) [0|1.84467440737096E+019] ""  CSM_LE,TCP_LE,ONSTAR_LE

BO_ 1361 UUDT_Resp_From_ECC_HVAC_LE: 8 CGM_LE
 SG_ DgnInf_LS551 : 7|64@0+ (1,0) [0|1.84467440737096E+019] ""  CSM_LE,TCP_LE,ONSTAR_LE

BO_ 1373 UUDT_Resp_From_DSM_LE: 8 CGM_LE
 SG_ DgnInf_LS55D : 7|64@0+ (1,0) [0|1.84467440737096E+019] ""  CSM_LE,TCP_LE,ONSTAR_LE

BO_ 1345 UUDT_Resp_From_BCM_LE: 8 CGM_LE
 SG_ DgnInf_LS541 : 7|64@0+ (1,0) [0|1.84467440737096E+019] ""  CSM_LE,TCP_LE,ONSTAR_LE

BO_ 1371 UUDT_Resp_From_ARB_LE: 8 CGM_LE
 SG_ DgnInf_LS55B : 7|64@0+ (1,0) [0|1.84467440737096E+019] ""  CGM_LE,CSM_LE,TCP_LE,ONSTAR_LE

BO_ 1349 UUDT_Resp_From_AOS_LE: 8 CGM_LE
 SG_ DgnInf_LS545 : 7|64@0+ (1,0) [0|1.84467440737096E+019] ""  CSM_LE,TCP_LE,ONSTAR_LE

BO_ 1374 UUDT_Resp_From_AHS_LE: 8 CGM_LE
 SG_ DgnInf_LS55E : 7|64@0+ (1,0) [0|1.84467440737096E+019] ""  CSM_LE,TCP_LE,ONSTAR_LE

BO_ 1347 UUDT_Resp_From_AGC_LE: 8 CGM_LE
 SG_ DgnInf_LS543 : 7|64@0+ (1,0) [0|1.84467440737096E+019] ""  CSM_LE,TCP_LE,ONSTAR_LE

BO_ 1599 VNMF_LE_63F_HBSM: 8 CGM_LE
 SG_ VectraSpcNWMgtD : 7|64@0+ (1,0) [0|1.84467440737096E+019] ""  CGM_LE,V2V_LE,TCP_LE,UHP_Low_LE,LVMNav_LE,ONSTAR_LE,VKM_LE,RSC_LE,RSE_LE,RSA_LE,VCU_LE,CSM_LE,RadioHead_LE,CHM_LE,PDIM_LE,OTIM_LE,CHUD_LE,LVMPC_LE,IPC_LE,ICS_LE,VPM_LE,HUD_LE,TouchPad_LE,DVB_T_LE,AMP_LE

BO_ 1598 VNMF_LE_63E_AHS: 8 CGM_LE
 SG_ VectraSpcNWMgtD : 7|64@0+ (1,0) [0|1.84467440737096E+019] ""  RCRM_LE,V2V_LE,TCP_LE,UHP_Low_LE,LVMNav_LE,ONSTAR_LE,VKM_LE,RSC_LE,RSE_LE,RSA_LE,VCU_LE,CSM_LE,RadioHead_LE,CHM_LE,PDIM_LE,OTIM_LE,CHUD_LE,LVMPC_LE,IPC_LE,ICS_LE,VPM_LE,HUD_LE,TouchPad_LE,DVB_T_LE,AMP_LE

BO_ 1597 VNMF_LE_63D_DSM_HVSM_F: 8 CGM_LE
 SG_ VectraSpcNWMgtD : 7|64@0+ (1,0) [0|1.84467440737096E+019] ""  RCRM_LE,V2V_LE,TCP_LE,UHP_Low_LE,LVMNav_LE,ONSTAR_LE,VKM_LE,RSC_LE,RSE_LE,RSA_LE,VCU_LE,CSM_LE,RadioHead_LE,CHM_LE,PDIM_LE,OTIM_LE,CHUD_LE,LVMPC_LE,IPC_LE,ICS_LE,VPM_LE,HUD_LE,TouchPad_LE,DVB_T_LE,AMP_LE

BO_ 1596 VNMF_LE_63C_SCL: 8 CGM_LE
 SG_ VectraSpcNWMgtD : 7|64@0+ (1,0) [0|1.84467440737096E+019] ""  RCRM_LE,V2V_LE,TCP_LE,UHP_Low_LE,LVMNav_LE,ONSTAR_LE,VKM_LE,RSC_LE,RSE_LE,RSA_LE,VCU_LE,CSM_LE,RadioHead_LE,CHM_LE,PDIM_LE,OTIM_LE,CHUD_LE,LVMPC_LE,IPC_LE,ICS_LE,VPM_LE,HUD_LE,TouchPad_LE,DVB_T_LE,AMP_LE

BO_ 1595 VNMF_LE_ARB: 8 CGM_LE
 SG_ VectraSpcNWMgtD : 7|64@0+ (1,0) [0|1.84467440737096E+019] ""  RCRM_LE,CGM_LE,TCP_LE,UHP_Low_LE,LVMNav_LE,ONSTAR_LE,VKM_LE,RSC_LE,RSE_LE,RSA_LE,VCU_LE,CSM_LE,RadioHead_LE,CHM_LE,PDIM_LE,OTIM_LE,CHUD_LE,LVMPC_LE,IPC_LE,ICS_LE,VPM_LE,HUD_LE,TouchPad_LE,DVB_T_LE,AMP_LE

BO_ 1594 VNMF_LE_63A_SBZA_L: 8 CGM_LE
 SG_ VectraSpcNWMgtD : 7|64@0+ (1,0) [0|1.84467440737096E+019] ""  RCRM_LE,V2V_LE,TCP_LE,UHP_Low_LE,LVMNav_LE,ONSTAR_LE,VKM_LE,RSC_LE,RSE_LE,RSA_LE,VCU_LE,CSM_LE,RadioHead_LE,CHM_LE,PDIM_LE,OTIM_LE,CHUD_LE,LVMPC_LE,IPC_LE,ICS_LE,VPM_LE,HUD_LE,TouchPad_LE,DVB_T_LE,AMP_LE

BO_ 1593 VNMF_LE_639_APA_UPA: 8 CGM_LE
 SG_ VectraSpcNWMgtD : 7|64@0+ (1,0) [0|1.84467440737096E+019] ""  RCRM_LE,V2V_LE,TCP_LE,UHP_Low_LE,LVMNav_LE,ONSTAR_LE,VKM_LE,RSC_LE,RSE_LE,RSA_LE,VCU_LE,CSM_LE,RadioHead_LE,CHM_LE,PDIM_LE,OTIM_LE,CHUD_LE,LVMPC_LE,IPC_LE,ICS_LE,VPM_LE,HUD_LE,TouchPad_LE,DVB_T_LE,AMP_LE

BO_ 1592 VNMF_LE_638_HVSM_R: 8 CGM_LE
 SG_ VectraSpcNWMgtD : 7|64@0+ (1,0) [0|1.84467440737096E+019] ""  RCRM_LE,V2V_LE,TCP_LE,UHP_Low_LE,LVMNav_LE,ONSTAR_LE,VKM_LE,RSC_LE,RSE_LE,RSA_LE,VCU_LE,CSM_LE,RadioHead_LE,CHM_LE,PDIM_LE,OTIM_LE,CHUD_LE,LVMPC_LE,IPC_LE,ICS_LE,VPM_LE,HUD_LE,TouchPad_LE,DVB_T_LE,AMP_LE

BO_ 1591 VNMF_LE_637_SBZA_R: 8 CGM_LE
 SG_ VectraSpcNWMgtD : 7|64@0+ (1,0) [0|1.84467440737096E+019] ""  RCRM_LE,V2V_LE,TCP_LE,UHP_Low_LE,LVMNav_LE,ONSTAR_LE,VKM_LE,RSC_LE,RSE_LE,RSA_LE,VCU_LE,CSM_LE,RadioHead_LE,CHM_LE,PDIM_LE,OTIM_LE,CHUD_LE,LVMPC_LE,IPC_LE,ICS_LE,VPM_LE,HUD_LE,TouchPad_LE,DVB_T_LE,AMP_LE

BO_ 1589 VNMF_LE_635_VIS2: 8 CGM_LE
 SG_ VectraSpcNWMgtD : 7|64@0+ (1,0) [0|1.84467440737096E+019] ""  RCRM_LE,V2V_LE,TCP_LE,UHP_Low_LE,LVMNav_LE,ONSTAR_LE,VKM_LE,RSC_LE,RSE_LE,RSA_LE,VCU_LE,CSM_LE,RadioHead_LE,CHM_LE,PDIM_LE,OTIM_LE,CHUD_LE,LVMPC_LE,IPC_LE,ICS_LE,VPM_LE,HUD_LE,TouchPad_LE,DVB_T_LE,AMP_LE

BO_ 1587 VNMF_LE_633_TIM: 8 CGM_LE
 SG_ VectraSpcNWMgtD : 7|64@0+ (1,0) [0|1.84467440737096E+019] ""  RCRM_LE,V2V_LE,TCP_LE,UHP_Low_LE,LVMNav_LE,ONSTAR_LE,VKM_LE,RSC_LE,RSE_LE,RSA_LE,VCU_LE,CSM_LE,RadioHead_LE,CHM_LE,PDIM_LE,OTIM_LE,CHUD_LE,LVMPC_LE,IPC_LE,ICS_LE,VPM_LE,HUD_LE,TouchPad_LE,DVB_T_LE,AMP_LE

BO_ 1585 VNMF_LE_631_ECC_HVAC: 8 CGM_LE
 SG_ VectraSpcNWMgtD : 7|64@0+ (1,0) [0|1.84467440737096E+019] ""  RCRM_LE,V2V_LE,TCP_LE,UHP_Low_LE,LVMNav_LE,ONSTAR_LE,VKM_LE,RSC_LE,RSE_LE,RSA_LE,VCU_LE,CSM_LE,RadioHead_LE,CHM_LE,PDIM_LE,OTIM_LE,CHUD_LE,LVMPC_LE,IPC_LE,ICS_LE,VPM_LE,HUD_LE,TouchPad_LE,DVB_T_LE,AMP_LE

BO_ 1583 VNMF_LE_62F_PTM_STC: 8 CGM_LE
 SG_ VectraSpcNWMgtD : 7|64@0+ (1,0) [0|1.84467440737096E+019] ""  RCRM_LE,V2V_LE,TCP_LE,UHP_Low_LE,LVMNav_LE,ONSTAR_LE,VKM_LE,RSC_LE,RSE_LE,RSA_LE,VCU_LE,CSM_LE,RadioHead_LE,CHM_LE,PDIM_LE,OTIM_LE,CHUD_LE,LVMPC_LE,IPC_LE,ICS_LE,VPM_LE,HUD_LE,TouchPad_LE,DVB_T_LE,AMP_LE

BO_ 1579 VNMF_LE_62B_FCM: 8 CGM_LE
 SG_ VectraSpcNWMgtD : 7|64@0+ (1,0) [0|1.84467440737096E+019] ""  RCRM_LE,V2V_LE,TCP_LE,UHP_Low_LE,LVMNav_LE,ONSTAR_LE,VKM_LE,RSC_LE,RSE_LE,RSA_LE,VCU_LE,CSM_LE,RadioHead_LE,CHM_LE,PDIM_LE,OTIM_LE,CHUD_LE,LVMPC_LE,IPC_LE,ICS_LE,VPM_LE,HUD_LE,TouchPad_LE,DVB_T_LE,AMP_LE

BO_ 1575 VNMF_LE_627_SDM: 8 CGM_LE
 SG_ VectraSpcNWMgtD : 7|64@0+ (1,0) [0|1.84467440737096E+019] ""  RCRM_LE,V2V_LE,TCP_LE,UHP_Low_LE,LVMNav_LE,ONSTAR_LE,VKM_LE,RSC_LE,RSE_LE,RSA_LE,VCU_LE,CSM_LE,RadioHead_LE,CHM_LE,PDIM_LE,OTIM_LE,CHUD_LE,LVMPC_LE,IPC_LE,ICS_LE,VPM_LE,HUD_LE,TouchPad_LE,DVB_T_LE,AMP_LE

BO_ 1573 VNMF_LE_625_AOS: 8 CGM_LE
 SG_ VectraSpcNWMgtD : 7|64@0+ (1,0) [0|1.84467440737096E+019] ""  RCRM_LE,V2V_LE,TCP_LE,UHP_Low_LE,LVMNav_LE,ONSTAR_LE,VKM_LE,RSC_LE,RSE_LE,RSA_LE,VCU_LE,CSM_LE,RadioHead_LE,CHM_LE,PDIM_LE,OTIM_LE,CHUD_LE,LVMPC_LE,IPC_LE,ICS_LE,VPM_LE,HUD_LE,TouchPad_LE,DVB_T_LE,AMP_LE

BO_ 1571 VNMF_LE_623_AGC: 8 CGM_LE
 SG_ VectraSpcNWMgtD : 7|64@0+ (1,0) [0|1.84467440737096E+019] ""  RCRM_LE,V2V_LE,TCP_LE,UHP_Low_LE,LVMNav_LE,ONSTAR_LE,VKM_LE,RSC_LE,RSE_LE,RSA_LE,VCU_LE,CSM_LE,RadioHead_LE,CHM_LE,PDIM_LE,OTIM_LE,CHUD_LE,LVMPC_LE,IPC_LE,ICS_LE,VPM_LE,HUD_LE,TouchPad_LE,DVB_T_LE,AMP_LE

BO_ 1570 VNMF_LE_622_PEPS_PBSM: 8 CGM_LE
 SG_ VectraSpcNWMgtD : 7|64@0+ (1,0) [0|1.84467440737096E+019] ""  RCRM_LE,V2V_LE,TCP_LE,UHP_Low_LE,LVMNav_LE,ONSTAR_LE,VKM_LE,RSC_LE,RSE_LE,RSA_LE,VCU_LE,CSM_LE,RadioHead_LE,CHM_LE,PDIM_LE,OTIM_LE,CHUD_LE,LVMPC_LE,IPC_LE,ICS_LE,VPM_LE,HUD_LE,TouchPad_LE,DVB_T_LE,AMP_LE

BO_ 1569 VNMF_LE_621_BCM: 8 CGM_LE
 SG_ VectraSpcNWMgtD : 7|64@0+ (1,0) [0|1.84467440737096E+019] ""  RCRM_LE,V2V_LE,TCP_LE,UHP_Low_LE,LVMNav_LE,ONSTAR_LE,VKM_LE,RSC_LE,RSE_LE,RSA_LE,VCU_LE,CSM_LE,RadioHead_LE,CHM_LE,PDIM_LE,OTIM_LE,CHUD_LE,LVMPC_LE,IPC_LE,ICS_LE,VPM_LE,HUD_LE,TouchPad_LE,DVB_T_LE,AMP_LE

BO_ 1568 VNMF_LE_620_VICM: 8 CGM_LE
 SG_ VectraSpcNWMgtD : 7|64@0+ (1,0) [0|1.84467440737096E+019] ""  RCRM_LE,V2V_LE,TCP_LE,UHP_Low_LE,LVMNav_LE,ONSTAR_LE,VKM_LE,RSC_LE,RSE_LE,RSA_LE,VCU_LE,CSM_LE,RadioHead_LE,CHM_LE,PDIM_LE,OTIM_LE,CHUD_LE,LVMPC_LE,IPC_LE,ICS_LE,VPM_LE,HUD_LE,TouchPad_LE,DVB_T_LE,AMP_LE

BO_ 2151251968 Telematics_Indication_Control_LE: 4 CGM_LE
 SG_ TICS_Ind1V : 8|1@0+ (1,0) [0|1] ""  TCP_LE,ONSTAR_LE
 SG_ TICS_Ind1FlshRtOnSt : 31|8@0+ (10,0) [0|2550] "ms"  TCP_LE,ONSTAR_LE
 SG_ TICS_Ind1FlshRtOffSt : 23|8@0+ (10,0) [0|2550] "ms"  TCP_LE,ONSTAR_LE
 SG_ TICS_Ind1 : 10|2@0+ (1,0) [0|3] ""  TCP_LE,ONSTAR_LE
 SG_ TICS_Ind1Stat : 12|2@0+ (1,0) [0|3] ""  TCP_LE,ONSTAR_LE

BO_ 2153857024 Teen_Driver_Event_Report_2_LE: 8 CGM_LE
 SG_ TnDrvTrCtrlEvntsRpt : 49|10@0+ (1,0) [0|1023] "counts"  VCU_LE,CSM_LE,RadioHead_LE
 SG_ TnDrvDrowDrvAlrtsRpt : 43|10@0+ (1,0) [0|1023] "counts"  VCU_LE,CSM_LE,RadioHead_LE
 SG_ TDRCADD_WOTEvnts : 11|1@0+ (1,0) [0|1] ""  VCU_LE,CSM_LE,RadioHead_LE
 SG_ TDRCADD_LDWEvnts : 10|1@0+ (1,0) [0|1] ""  VCU_LE,CSM_LE,RadioHead_LE
 SG_ TDRCADD_FCMBrEvts : 13|1@0+ (1,0) [0|1] ""  VCU_LE,CSM_LE,RadioHead_LE
 SG_ TDRCADD_DrwDrvAlrt : 12|1@0+ (1,0) [0|1] ""  VCU_LE,CSM_LE,RadioHead_LE
 SG_ TDRCADD_RCMBrEvts : 14|1@0+ (1,0) [0|1] ""  VCU_LE,CSM_LE,RadioHead_LE
 SG_ TDRCADD_FCImntAlrts : 15|1@0+ (1,0) [0|1] ""  VCU_LE,CSM_LE,RadioHead_LE
 SG_ TDRCADD_FCHdwyAlrt : 0|1@0+ (1,0) [0|1] ""  VCU_LE,CSM_LE,RadioHead_LE
 SG_ TDRCADD_StCtrlEvnts : 2|1@0+ (1,0) [0|1] ""  VCU_LE,CSM_LE,RadioHead_LE
 SG_ TDRCADD_ABSAtvEvt : 1|1@0+ (1,0) [0|1] ""  VCU_LE,CSM_LE,RadioHead_LE
 SG_ TDRCADD_TrCtrlEvnts : 3|1@0+ (1,0) [0|1] ""  VCU_LE,CSM_LE,RadioHead_LE
 SG_ TDRCADD_OvSpdEvnt : 4|1@0+ (1,0) [0|1] ""  VCU_LE,CSM_LE,RadioHead_LE
 SG_ TDRCADD_DistDrvn : 5|1@0+ (1,0) [0|1] ""  VCU_LE,CSM_LE,RadioHead_LE
 SG_ TDRCADD_MaxSpd : 6|1@0+ (1,0) [0|1] ""  VCU_LE,CSM_LE,RadioHead_LE
 SG_ TnDrvStblCtrlEvntsRpt : 37|10@0+ (1,0) [0|1023] "counts"  VCU_LE,CSM_LE,RadioHead_LE
 SG_ TnDrvABSAtvEvntsRpt : 31|10@0+ (1,0) [0|1023] "counts"  VCU_LE,CSM_LE,RadioHead_LE
 SG_ TeenDrvWOTEvntsRpt : 9|10@0+ (1,0) [0|1023] "counts"  VCU_LE,CSM_LE,RadioHead_LE

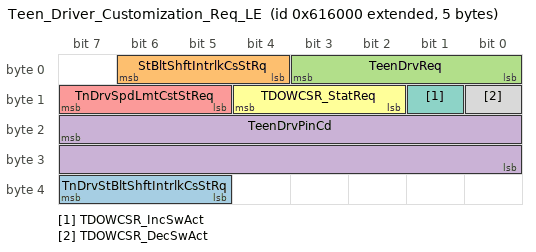
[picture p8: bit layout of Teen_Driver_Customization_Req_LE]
BO_ 2153865216 Teen_Driver_Customization_Req_LE: 5 RadioHead_LE
 SG_ TnDrvStBltShftIntrlkCsStRq : 39|3@0+ (1,0) [0|7] ""  CGM_LE
 SG_ StBltShftIntrlkCsStRq : 6|3@0+ (1,0) [0|7] ""  CGM_LE
 SG_ TeenDrvReq : 3|4@0+ (1,0) [0|15] ""  CGM_LE
 SG_ TeenDrvPinCd : 23|16@0+ (1,0) [0|39321] ""  CGM_LE
 SG_ TnDrvSpdLmtCstStReq : 15|3@0+ (1,0) [0|7] ""  CGM_LE
 SG_ TDOWCSR_StatReq : 12|3@0+ (1,0) [0|7] ""  CGM_LE
 SG_ TDOWCSR_IncSwAct : 9|1@0+ (1,0) [0|1] ""  CGM_LE
 SG_ TDOWCSR_DecSwAct : 8|1@0+ (1,0) [0|1] ""  CGM_LE

BO_TX_BU_ 2152046592 : TCP_LE,ONSTAR_LE;
BO_TX_BU_ 2152030208 : TCP_LE,ONSTAR_LE;
BO_TX_BU_ 2156978176 : CSM_LE,ONSTAR_LE;
BO_TX_BU_ 2156969984 : CSM_LE,ONSTAR_LE;
BO_TX_BU_ 2156961792 : CSM_LE,ONSTAR_LE;
BO_TX_BU_ 2156994560 : CSM_LE,ONSTAR_LE;
BO_TX_BU_ 2156986368 : CSM_LE,ONSTAR_LE;
BO_TX_BU_ 2154651648 : VCU_LE,CSM_LE;
BO_TX_BU_ 2152513536 : LVMPC_LE,LVMNav_LE;
BO_TX_BU_ 2154569728 : VCU_LE,RadioHead_LE,CSM_LE;
BO_TX_BU_ 2156953600 : CSM_LE,ONSTAR_LE;
BO_TX_BU_ 597 : CGM_LE,CSM_LE,TCP_LE,ONSTAR_LE;
BO_TX_BU_ 2020 : CGM_LE,CSM_LE,TCP_LE,ONSTAR_LE;
BO_TX_BU_ 601 : CGM_LE,CSM_LE,TCP_LE,ONSTAR_LE;
BO_TX_BU_ 583 : CGM_LE,CSM_LE,TCP_LE,ONSTAR_LE;
BO_TX_BU_ 604 : CGM_LE,CSM_LE,TCP_LE,ONSTAR_LE;
BO_TX_BU_ 599 : CGM_LE,CSM_LE,TCP_LE,ONSTAR_LE;
BO_TX_BU_ 602 : CGM_LE,CSM_LE,TCP_LE,ONSTAR_LE;
BO_TX_BU_ 591 : CGM_LE,CSM_LE,TCP_LE,ONSTAR_LE;
BO_TX_BU_ 578 : CGM_LE,CSM_LE,TCP_LE,ONSTAR_LE;
BO_TX_BU_ 600 : CGM_LE,CSM_LE,TCP_LE,ONSTAR_LE;
BO_TX_BU_ 607 : CGM_LE,CSM_LE,TCP_LE,ONSTAR_LE;
BO_TX_BU_ 587 : CGM_LE,CSM_LE,TCP_LE,ONSTAR_LE;
BO_TX_BU_ 593 : CGM_LE,CSM_LE,TCP_LE,ONSTAR_LE;
BO_TX_BU_ 605 : CGM_LE,CSM_LE,TCP_LE,ONSTAR_LE;
BO_TX_BU_ 577 : CGM_LE,CSM_LE,TCP_LE,ONSTAR_LE;
BO_TX_BU_ 603 : CGM_LE,CSM_LE,TCP_LE,ONSTAR_LE;
BO_TX_BU_ 581 : CGM_LE,CSM_LE,TCP_LE,ONSTAR_LE;
BO_TX_BU_ 606 : CGM_LE,CSM_LE,TCP_LE,ONSTAR_LE;
BO_TX_BU_ 579 : CGM_LE,CSM_LE,TCP_LE,ONSTAR_LE;
BO_TX_BU_ 1631 : RCRM_LE,CGM_LE;
BO_TX_BU_ 1627 : V2V_LE,CGM_LE;
BO_TX_BU_ 1375 : RCRM_LE,CGM_LE;
BO_TX_BU_ 1371 : V2V_LE,CGM_LE;
BO_TX_BU_ 1599 : RCRM_LE,CGM_LE;
BO_TX_BU_ 1595 : V2V_LE,CGM_LE;
BO_TX_BU_ 2153865216 : VCU_LE,CSM_LE,RadioHead_LE;
CM_ SG_ 2154725376 AuxHtrAtv378 "Auxiliary Heater shall be used to denote a heater function that uses some kind of power, electrical or mechanical,  that was generated by the engine.";
CM_ SG_ 2154725376 AuxHtrRq "Auxiliary Heater shall be used to denote a heater function that uses some kind of power, electrical or mechanical,  that was generated by the engine.";
CM_ BO_ 1568 "LAP: Tester VNMF?";
BA_DEF_ SG_  "VNSigPrimaryTriggering" ENUM  "No","Yes","DLCLS","DLCHS","DLCCE","DLCFO";
BA_DEF_ SG_  "VNSigRemoteDiagnostics" ENUM  "No","Yes","DLCLS","DLCHS","DLCCE","DLCFO";
BA_DEF_ SG_  "VNSigInfotainment" ENUM  "No","Yes","DLCLS","DLCHS","DLCCE","DLCFO";
BA_DEF_ SG_  "VNSigParkedVehicle" ENUM  "No","Yes","DLCLS","DLCHS","DLCCE","DLCFO";
BA_DEF_ SG_  "VNSigIntermediate" ENUM  "No","Yes","DLCLS","DLCHS","DLCCE","DLCFO";
BA_DEF_ SG_  "VNSigUnused_4" ENUM  "No","Yes","DLCLS","DLCHS","DLCCE","DLCFO";
BA_DEF_ SG_  "SignalType" STRING ;
BA_DEF_ SG_  "PacketOrder" INT 0 65535;
BA_DEF_ SG_  "SignalLongName" STRING ;
BA_DEF_ SG_  "GenSigStartValue" INT 0 65535;
BA_DEF_ SG_  "VNSigDiagnostic" ENUM  "No","Yes","DLCLS","DLCHS","DLCCE","DLCFO";
BA_DEF_ SG_  "VNSigAllNodes" ENUM  "No","Yes","DLCLS","DLCHS","DLCCE","DLCFO";
BA_DEF_ SG_  "GenSigDeltaValue" INT 0 0;
BA_DEF_ SG_  "GenSigSendType" ENUM  "not used","not used","not used","not used","not used","not used","not used","NoSigSendType","not used","not used","OnAnyChange","OnChangeIfActive","OnDelta","DLCLS","DLCHS","DLCCE","DLCFO";
BA_DEF_ SG_  "GenSigSendOnInit" ENUM  "Not Initialized","Application","Handler","DLCLS","DLCHS","DLCCE","DLCFO";
BA_DEF_ BO_  "AppGenMsgCycleTime" INT 0 0;
BA_DEF_ BO_  "TpTxIndex" INT 0 99;
BA_DEF_ BO_  "GenMsgILSupport" ENUM  "No","Yes","DLCLS","DLCHS","DLCCE","DLCFO";
BA_DEF_ BO_  "TpApplType" STRING ;
BA_DEF_ BO_  "Prio" INT 0 7;
BA_DEF_ BO_  "MessageSubnet" ENUM  "LS","MS","HS","CE","PE","HV","FO","S1","HE","LE","HE2","DLCLS","DLCHS","DLCCE","DLCFO";
BA_DEF_ BO_  "GenMsgMandatoryToSupervision" ENUM  "No","Yes","DLCLS","DLCHS","DLCCE","DLCFO";
BA_DEF_ BO_  "DiagState" ENUM  "No","Yes","DLCLS","DLCHS","DLCCE","DLCFO";
BA_DEF_ BO_  "GenMsgStartDelayTime" INT 0 100000;
BA_DEF_ BO_  "GenMsgDelayTime" INT 0 100000;
BA_DEF_ BO_  "GenMsgCycleTime" INT 0 100000;
BA_DEF_ BO_  "GenMsgSendType" ENUM  "cyclicX","spontanX","cyclicIfActiveX","spontanWithDelay","cyclicAndSpontanX","cyclicAndSpontanWithDelay","spontanWithRepitition","cyclicIfActiveAndSpontanWD","DLCLS","DLCHS","DLCCE","DLCFO";
BA_DEF_ BO_  "DiagResponse" ENUM  "No","Yes","DLCLS","DLCHS","DLCCE","DLCFO";
BA_DEF_ BO_  "DiagRequest" ENUM  "No","Yes","DLCLS","DLCHS","DLCCE","DLCFO";
BA_DEF_ BO_  "NmMessage" ENUM  "No","Yes","DLCLS","DLCHS","DLCCE","DLCFO";
BA_DEF_REL_ BU_SG_REL_  "GenSigSuprvRespComment" STRING ;
BA_DEF_REL_ BU_SG_REL_  "GenSigVBitResp" ENUM  "No","Yes","DLCLS","DLCHS","DLCCE","DLCFO";
BA_DEF_REL_ BU_SG_REL_  "GenSigVBitRespComment" STRING ;
BA_DEF_REL_ BU_SG_REL_  "GenSigVDAFailComment" STRING ;
BA_DEF_REL_ BU_SG_REL_  "GenSigVDAFailResp" ENUM  "No","Yes","DLCLS","DLCHS","DLCCE","DLCFO";
BA_DEF_REL_ BU_SG_REL_  "GenSigRxStartValue" STRING ;
BA_DEF_REL_ BU_SG_REL_  "GenSigSuprvRespSubValue" INT 0 65535;
BA_DEF_REL_ BU_SG_REL_  "GenSigSuprvResp" ENUM  "None","Notify App","Substitute Default","DLCLS","DLCHS","DLCCE","DLCFO";
BA_DEF_REL_ BU_SG_REL_  "GenSigTimeoutMsg" HEX -2147483648 268435455;
BA_DEF_DEF_  "VNSigPrimaryTriggering" "No";
BA_DEF_DEF_  "VNSigRemoteDiagnostics" "No";
BA_DEF_DEF_  "VNSigInfotainment" "No";
BA_DEF_DEF_  "VNSigParkedVehicle" "No";
BA_DEF_DEF_  "VNSigIntermediate" "No";
BA_DEF_DEF_  "VNSigUnused_4" "No";
BA_DEF_DEF_  "SignalType" "";
BA_DEF_DEF_  "PacketOrder" 0;
BA_DEF_DEF_  "SignalLongName" "";
BA_DEF_DEF_  "GenSigStartValue" 0;
BA_DEF_DEF_  "VNSigDiagnostic" "No";
BA_DEF_DEF_  "VNSigAllNodes" "No";
BA_DEF_DEF_  "GenSigDeltaValue" 0;
BA_DEF_DEF_  "GenSigSendType" "NoSigSendType";
BA_DEF_DEF_  "GenSigSendOnInit" "Not Initialized";
BA_DEF_DEF_  "AppGenMsgCycleTime" 0;
BA_DEF_DEF_  "TpTxIndex" 0;
BA_DEF_DEF_  "GenMsgILSupport" "Yes";
BA_DEF_DEF_  "TpApplType" "";
BA_DEF_DEF_  "Prio" 4;
BA_DEF_DEF_  "MessageSubnet" "FO";
BA_DEF_DEF_  "GenMsgMandatoryToSupervision" "No";
BA_DEF_DEF_  "DiagState" "No";
BA_DEF_DEF_  "GenMsgStartDelayTime" 0;
BA_DEF_DEF_  "GenMsgDelayTime" 0;
BA_DEF_DEF_  "GenMsgCycleTime" 0;
BA_DEF_DEF_  "GenMsgSendType" "spontanX";
BA_DEF_DEF_  "DiagResponse" "No";
BA_DEF_DEF_  "DiagRequest" "No";
BA_DEF_DEF_  "NmMessage" "No";
BA_DEF_DEF_REL_ "GenSigSuprvRespComment" "";
BA_DEF_DEF_REL_ "GenSigVBitResp" "No";
BA_DEF_DEF_REL_ "GenSigVBitRespComment" "";
BA_DEF_DEF_REL_ "GenSigVDAFailComment" "";
BA_DEF_DEF_REL_ "GenSigVDAFailResp" "No";
BA_DEF_DEF_REL_ "GenSigRxStartValue" "";
BA_DEF_DEF_REL_ "GenSigSuprvRespSubValue" 0;
BA_DEF_DEF_REL_ "GenSigSuprvResp" "None";
BA_DEF_DEF_REL_ "GenSigTimeoutMsg" 0;
BA_ "MessageSubnet" BO_ 2152046592 9;
BA_ "GenMsgDelayTime" BO_ 2152046592 20;
BA_ "MessageSubnet" BO_ 2152030208 9;
BA_ "GenMsgDelayTime" BO_ 2152030208 100;
BA_ "MessageSubnet" BO_ 2150531072 9;
BA_ "GenMsgDelayTime" BO_ 2150531072 100;
BA_ "MessageSubnet" BO_ 2153897984 9;
BA_ "GenMsgDelayTime" BO_ 2153897984 100;
BA_ "Prio" BO_ 936 0;
BA_ "MessageSubnet" BO_ 936 9;
BA_ "DiagResponse" BO_ 936 1;
BA_ "Prio" BO_ 856 0;
BA_ "MessageSubnet" BO_ 856 9;
BA_ "DiagResponse" BO_ 856 1;
BA_ "Prio" BO_ 872 0;
BA_ "MessageSubnet" BO_ 872 9;
BA_ "DiagResponse" BO_ 872 1;
BA_ "Prio" BO_ 864 0;
BA_ "MessageSubnet" BO_ 864 9;
BA_ "DiagResponse" BO_ 864 1;
BA_ "Prio" BO_ 921 0;
BA_ "MessageSubnet" BO_ 921 9;
BA_ "DiagResponse" BO_ 921 1;
BA_ "MessageSubnet" BO_ 2151202816 9;
BA_ "GenMsgDelayTime" BO_ 2151202816 100;
BA_ "MessageSubnet" BO_ 2151702528 9;
BA_ "GenMsgDelayTime" BO_ 2151702528 100;
BA_ "MessageSubnet" BO_ 2156978176 9;
BA_ "GenMsgDelayTime" BO_ 2156978176 100;
BA_ "MessageSubnet" BO_ 2156969984 9;
BA_ "GenMsgDelayTime" BO_ 2156969984 100;
BA_ "MessageSubnet" BO_ 2156961792 9;
BA_ "GenMsgDelayTime" BO_ 2156961792 100;
BA_ "MessageSubnet" BO_ 2151923712 9;
BA_ "GenMsgDelayTime" BO_ 2151923712 100;
BA_ "MessageSubnet" BO_ 2150236160 9;
BA_ "GenMsgDelayTime" BO_ 2150236160 100;
BA_ "GenMsgCycleTime" BO_ 2150236160 1000;
BA_ "GenMsgSendType" BO_ 2150236160 0;
BA_ "MessageSubnet" BO_ 2150170624 9;
BA_ "GenMsgDelayTime" BO_ 2150170624 100;
BA_ "GenMsgCycleTime" BO_ 2150170624 1000;
BA_ "GenMsgSendType" BO_ 2150170624 0;
BA_ "MessageSubnet" BO_ 2152628224 9;
BA_ "GenMsgDelayTime" BO_ 2152628224 100;
BA_ "GenMsgCycleTime" BO_ 2152628224 3000;
BA_ "GenMsgSendType" BO_ 2152628224 0;
BA_ "MessageSubnet" BO_ 2154725376 9;
BA_ "GenMsgDelayTime" BO_ 2154725376 100;
BA_ "MessageSubnet" BO_ 2157051904 9;
BA_ "GenMsgDelayTime" BO_ 2157051904 100;
BA_ "MessageSubnet" BO_ 2156994560 9;
BA_ "GenMsgDelayTime" BO_ 2156994560 100;
BA_ "MessageSubnet" BO_ 2156986368 9;
BA_ "GenMsgDelayTime" BO_ 2156986368 100;
BA_ "MessageSubnet" BO_ 2158133248 9;
BA_ "GenMsgDelayTime" BO_ 2158133248 100;
BA_ "MessageSubnet" BO_ 2154651648 9;
BA_ "GenMsgDelayTime" BO_ 2154651648 50;
BA_ "MessageSubnet" BO_ 2154635264 9;
BA_ "GenMsgDelayTime" BO_ 2154635264 50;
BA_ "MessageSubnet" BO_ 2152529920 9;
BA_ "GenMsgDelayTime" BO_ 2152529920 100;
BA_ "MessageSubnet" BO_ 2152513536 9;
BA_ "GenMsgDelayTime" BO_ 2152513536 100;
BA_ "MessageSubnet" BO_ 2154889216 9;
BA_ "GenMsgDelayTime" BO_ 2154889216 100;
BA_ "MessageSubnet" BO_ 2154872832 9;
BA_ "GenMsgDelayTime" BO_ 2154872832 100;
BA_ "GenMsgCycleTime" BO_ 2154872832 2000;
BA_ "GenMsgSendType" BO_ 2154872832 0;
BA_ "MessageSubnet" BO_ 2154569728 9;
BA_ "GenMsgDelayTime" BO_ 2154569728 100;
BA_ "GenMsgCycleTime" BO_ 2154569728 2000;
BA_ "GenMsgSendType" BO_ 2154569728 0;
BA_ "MessageSubnet" BO_ 2154594304 9;
BA_ "GenMsgDelayTime" BO_ 2154594304 10;
BA_ "MessageSubnet" BO_ 2154586112 9;
BA_ "GenMsgDelayTime" BO_ 2154586112 10;
BA_ "MessageSubnet" BO_ 2154577920 9;
BA_ "GenMsgDelayTime" BO_ 2154577920 10;
BA_ "MessageSubnet" BO_ 2151931904 9;
BA_ "GenMsgDelayTime" BO_ 2151931904 100;
BA_ "MessageSubnet" BO_ 2150244352 9;
BA_ "GenMsgDelayTime" BO_ 2150244352 100;
BA_ "MessageSubnet" BO_ 2156953600 9;
BA_ "GenMsgDelayTime" BO_ 2156953600 100;
BA_ "GenMsgILSupport" BO_ 1363 0;
BA_ "TpApplType" BO_ 1363 "DiagUUDTResponse";
BA_ "Prio" BO_ 1363 0;
BA_ "MessageSubnet" BO_ 1363 9;
BA_ "Prio" BO_ 1619 0;
BA_ "MessageSubnet" BO_ 1619 9;
BA_ "DiagResponse" BO_ 1619 1;
BA_ "Prio" BO_ 597 0;
BA_ "MessageSubnet" BO_ 597 9;
BA_ "DiagRequest" BO_ 597 1;
BA_ "Prio" BO_ 2020 0;
BA_ "MessageSubnet" BO_ 2020 9;
BA_ "DiagRequest" BO_ 2020 1;
BA_ "Prio" BO_ 601 0;
BA_ "MessageSubnet" BO_ 601 9;
BA_ "DiagRequest" BO_ 601 1;
BA_ "Prio" BO_ 583 0;
BA_ "MessageSubnet" BO_ 583 9;
BA_ "DiagRequest" BO_ 583 1;
BA_ "Prio" BO_ 604 0;
BA_ "MessageSubnet" BO_ 604 9;
BA_ "DiagRequest" BO_ 604 1;
BA_ "Prio" BO_ 599 0;
BA_ "MessageSubnet" BO_ 599 9;
BA_ "DiagRequest" BO_ 599 1;
BA_ "Prio" BO_ 602 0;
BA_ "MessageSubnet" BO_ 602 9;
BA_ "DiagRequest" BO_ 602 1;
BA_ "Prio" BO_ 591 0;
BA_ "MessageSubnet" BO_ 591 9;
BA_ "DiagRequest" BO_ 591 1;
BA_ "Prio" BO_ 578 0;
BA_ "MessageSubnet" BO_ 578 9;
BA_ "DiagRequest" BO_ 578 1;
BA_ "Prio" BO_ 600 0;
BA_ "MessageSubnet" BO_ 600 9;
BA_ "DiagRequest" BO_ 600 1;
BA_ "Prio" BO_ 607 0;
BA_ "MessageSubnet" BO_ 607 9;
BA_ "DiagRequest" BO_ 607 1;
BA_ "GenMsgILSupport" BO_ 587 0;
BA_ "Prio" BO_ 587 0;
BA_ "MessageSubnet" BO_ 587 9;
BA_ "DiagRequest" BO_ 587 1;
BA_ "Prio" BO_ 593 0;
BA_ "MessageSubnet" BO_ 593 9;
BA_ "DiagRequest" BO_ 593 1;
BA_ "Prio" BO_ 605 0;
BA_ "MessageSubnet" BO_ 605 9;
BA_ "DiagRequest" BO_ 605 1;
BA_ "Prio" BO_ 577 0;
BA_ "MessageSubnet" BO_ 577 9;
BA_ "DiagRequest" BO_ 577 1;
BA_ "Prio" BO_ 603 0;
BA_ "MessageSubnet" BO_ 603 9;
BA_ "DiagRequest" BO_ 603 1;
BA_ "Prio" BO_ 581 0;
BA_ "MessageSubnet" BO_ 581 9;
BA_ "DiagRequest" BO_ 581 1;
BA_ "Prio" BO_ 606 0;
BA_ "MessageSubnet" BO_ 606 9;
BA_ "DiagRequest" BO_ 606 1;
BA_ "Prio" BO_ 579 0;
BA_ "MessageSubnet" BO_ 579 9;
BA_ "DiagRequest" BO_ 579 1;
BA_ "Prio" BO_ 1621 0;
BA_ "MessageSubnet" BO_ 1621 9;
BA_ "DiagResponse" BO_ 1621 1;
BA_ "Prio" BO_ 2028 0;
BA_ "MessageSubnet" BO_ 2028 9;
BA_ "DiagResponse" BO_ 2028 1;
BA_ "Prio" BO_ 1625 0;
BA_ "MessageSubnet" BO_ 1625 9;
BA_ "DiagResponse" BO_ 1625 1;
BA_ "Prio" BO_ 1607 0;
BA_ "MessageSubnet" BO_ 1607 9;
BA_ "DiagResponse" BO_ 1607 1;
BA_ "Prio" BO_ 1628 0;
BA_ "MessageSubnet" BO_ 1628 9;
BA_ "DiagResponse" BO_ 1628 1;
BA_ "Prio" BO_ 1623 0;
BA_ "MessageSubnet" BO_ 1623 9;
BA_ "DiagResponse" BO_ 1623 1;
BA_ "Prio" BO_ 1626 0;
BA_ "MessageSubnet" BO_ 1626 9;
BA_ "DiagResponse" BO_ 1626 1;
BA_ "Prio" BO_ 1615 0;
BA_ "MessageSubnet" BO_ 1615 9;
BA_ "DiagResponse" BO_ 1615 1;
BA_ "Prio" BO_ 1602 0;
BA_ "MessageSubnet" BO_ 1602 9;
BA_ "DiagResponse" BO_ 1602 1;
BA_ "Prio" BO_ 1624 0;
BA_ "MessageSubnet" BO_ 1624 9;
BA_ "DiagResponse" BO_ 1624 1;
BA_ "Prio" BO_ 1631 0;
BA_ "MessageSubnet" BO_ 1631 9;
BA_ "DiagResponse" BO_ 1631 1;
BA_ "GenMsgILSupport" BO_ 1611 0;
BA_ "Prio" BO_ 1611 0;
BA_ "MessageSubnet" BO_ 1611 9;
BA_ "DiagResponse" BO_ 1611 1;
BA_ "Prio" BO_ 1617 0;
BA_ "MessageSubnet" BO_ 1617 9;
BA_ "DiagResponse" BO_ 1617 1;
BA_ "Prio" BO_ 1629 0;
BA_ "MessageSubnet" BO_ 1629 9;
BA_ "DiagResponse" BO_ 1629 1;
BA_ "Prio" BO_ 1601 0;
BA_ "MessageSubnet" BO_ 1601 9;
BA_ "DiagResponse" BO_ 1601 1;
BA_ "Prio" BO_ 1627 0;
BA_ "MessageSubnet" BO_ 1627 9;
BA_ "DiagResponse" BO_ 1627 1;
BA_ "Prio" BO_ 1605 0;
BA_ "MessageSubnet" BO_ 1605 9;
BA_ "DiagResponse" BO_ 1605 1;
BA_ "Prio" BO_ 1630 0;
BA_ "MessageSubnet" BO_ 1630 9;
BA_ "DiagResponse" BO_ 1630 1;
BA_ "Prio" BO_ 1603 0;
BA_ "MessageSubnet" BO_ 1603 9;
BA_ "DiagResponse" BO_ 1603 1;
BA_ "GenMsgILSupport" BO_ 1365 0;
BA_ "TpApplType" BO_ 1365 "DiagUUDTResponse";
BA_ "Prio" BO_ 1365 0;
BA_ "MessageSubnet" BO_ 1365 9;
BA_ "GenMsgILSupport" BO_ 1516 0;
BA_ "TpApplType" BO_ 1516 "DiagUUDTResponse";
BA_ "Prio" BO_ 1516 0;
BA_ "MessageSubnet" BO_ 1516 9;
BA_ "GenMsgILSupport" BO_ 1369 0;
BA_ "TpApplType" BO_ 1369 "DiagUUDTResponse";
BA_ "Prio" BO_ 1369 0;
BA_ "MessageSubnet" BO_ 1369 9;
BA_ "GenMsgILSupport" BO_ 1351 0;
BA_ "TpApplType" BO_ 1351 "DiagUUDTResponse";
BA_ "Prio" BO_ 1351 0;
BA_ "MessageSubnet" BO_ 1351 9;
BA_ "GenMsgILSupport" BO_ 1372 0;
BA_ "TpApplType" BO_ 1372 "DiagUUDTResponse";
BA_ "Prio" BO_ 1372 0;
BA_ "MessageSubnet" BO_ 1372 9;
BA_ "GenMsgILSupport" BO_ 1367 0;
BA_ "TpApplType" BO_ 1367 "DiagUUDTResponse";
BA_ "Prio" BO_ 1367 0;
BA_ "MessageSubnet" BO_ 1367 9;
BA_ "GenMsgILSupport" BO_ 1370 0;
BA_ "TpApplType" BO_ 1370 "DiagUUDTResponse";
BA_ "Prio" BO_ 1370 0;
BA_ "MessageSubnet" BO_ 1370 9;
BA_ "GenMsgILSupport" BO_ 1359 0;
BA_ "TpApplType" BO_ 1359 "DiagUUDTResponse";
BA_ "Prio" BO_ 1359 0;
BA_ "MessageSubnet" BO_ 1359 9;
BA_ "GenMsgILSupport" BO_ 1346 0;
BA_ "TpApplType" BO_ 1346 "DiagUUDTResponse";
BA_ "Prio" BO_ 1346 0;
BA_ "MessageSubnet" BO_ 1346 9;
BA_ "GenMsgILSupport" BO_ 1368 0;
BA_ "TpApplType" BO_ 1368 "DiagUUDTResponse";
BA_ "Prio" BO_ 1368 0;
BA_ "MessageSubnet" BO_ 1368 9;
BA_ "GenMsgILSupport" BO_ 1375 0;
BA_ "TpApplType" BO_ 1375 "DiagUUDTResponse";
BA_ "Prio" BO_ 1375 0;
BA_ "MessageSubnet" BO_ 1375 9;
BA_ "GenMsgILSupport" BO_ 1355 0;
BA_ "TpApplType" BO_ 1355 "DiagUUDTResponse";
BA_ "Prio" BO_ 1355 0;
BA_ "MessageSubnet" BO_ 1355 9;
BA_ "GenMsgILSupport" BO_ 1361 0;
BA_ "TpApplType" BO_ 1361 "DiagUUDTResponse";
BA_ "Prio" BO_ 1361 0;
BA_ "MessageSubnet" BO_ 1361 9;
BA_ "GenMsgILSupport" BO_ 1373 0;
BA_ "TpApplType" BO_ 1373 "DiagUUDTResponse";
BA_ "Prio" BO_ 1373 0;
BA_ "MessageSubnet" BO_ 1373 9;
BA_ "GenMsgILSupport" BO_ 1345 0;
BA_ "TpApplType" BO_ 1345 "DiagUUDTResponse";
BA_ "Prio" BO_ 1345 0;
BA_ "MessageSubnet" BO_ 1345 9;
BA_ "GenMsgILSupport" BO_ 1371 0;
BA_ "TpApplType" BO_ 1371 "DiagUUDTResponse";
BA_ "Prio" BO_ 1371 0;
BA_ "MessageSubnet" BO_ 1371 9;
BA_ "GenMsgILSupport" BO_ 1349 0;
BA_ "TpApplType" BO_ 1349 "DiagUUDTResponse";
BA_ "Prio" BO_ 1349 0;
BA_ "MessageSubnet" BO_ 1349 9;
BA_ "TpApplType" BO_ 1374 "DiagUUDTResponse";
BA_ "Prio" BO_ 1374 0;
BA_ "MessageSubnet" BO_ 1374 9;
BA_ "GenMsgILSupport" BO_ 1347 0;
BA_ "TpApplType" BO_ 1347 "DiagUUDTResponse";
BA_ "Prio" BO_ 1347 0;
BA_ "MessageSubnet" BO_ 1347 9;
BA_ "Prio" BO_ 1599 0;
BA_ "MessageSubnet" BO_ 1599 9;
BA_ "GenMsgCycleTime" BO_ 1599 3000;
BA_ "GenMsgSendType" BO_ 1599 0;
BA_ "NmMessage" BO_ 1599 1;
BA_ "Prio" BO_ 1598 0;
BA_ "MessageSubnet" BO_ 1598 9;
BA_ "GenMsgCycleTime" BO_ 1598 3000;
BA_ "GenMsgSendType" BO_ 1598 0;
BA_ "NmMessage" BO_ 1598 1;
BA_ "Prio" BO_ 1597 0;
BA_ "MessageSubnet" BO_ 1597 9;
BA_ "GenMsgCycleTime" BO_ 1597 3000;
BA_ "GenMsgSendType" BO_ 1597 0;
BA_ "NmMessage" BO_ 1597 1;
BA_ "Prio" BO_ 1596 0;
BA_ "MessageSubnet" BO_ 1596 9;
BA_ "GenMsgCycleTime" BO_ 1596 3000;
BA_ "GenMsgSendType" BO_ 1596 0;
BA_ "NmMessage" BO_ 1596 1;
BA_ "Prio" BO_ 1595 0;
BA_ "MessageSubnet" BO_ 1595 9;
BA_ "GenMsgCycleTime" BO_ 1595 3000;
BA_ "GenMsgSendType" BO_ 1595 0;
BA_ "NmMessage" BO_ 1595 1;
BA_ "Prio" BO_ 1594 0;
BA_ "MessageSubnet" BO_ 1594 9;
BA_ "GenMsgCycleTime" BO_ 1594 3000;
BA_ "GenMsgSendType" BO_ 1594 0;
BA_ "NmMessage" BO_ 1594 1;
BA_ "Prio" BO_ 1593 0;
BA_ "MessageSubnet" BO_ 1593 9;
BA_ "GenMsgCycleTime" BO_ 1593 3000;
BA_ "GenMsgSendType" BO_ 1593 0;
BA_ "NmMessage" BO_ 1593 1;
BA_ "Prio" BO_ 1592 0;
BA_ "MessageSubnet" BO_ 1592 9;
BA_ "GenMsgCycleTime" BO_ 1592 3000;
BA_ "GenMsgSendType" BO_ 1592 0;
BA_ "NmMessage" BO_ 1592 1;
BA_ "Prio" BO_ 1591 0;
BA_ "MessageSubnet" BO_ 1591 9;
BA_ "GenMsgCycleTime" BO_ 1591 3000;
BA_ "GenMsgSendType" BO_ 1591 0;
BA_ "NmMessage" BO_ 1591 1;
BA_ "Prio" BO_ 1589 0;
BA_ "MessageSubnet" BO_ 1589 9;
BA_ "GenMsgCycleTime" BO_ 1589 3000;
BA_ "GenMsgSendType" BO_ 1589 0;
BA_ "NmMessage" BO_ 1589 1;
BA_ "Prio" BO_ 1587 0;
BA_ "MessageSubnet" BO_ 1587 9;
BA_ "GenMsgCycleTime" BO_ 1587 3000;
BA_ "GenMsgSendType" BO_ 1587 0;
BA_ "NmMessage" BO_ 1587 1;
BA_ "Prio" BO_ 1585 0;
BA_ "MessageSubnet" BO_ 1585 9;
BA_ "GenMsgCycleTime" BO_ 1585 3000;
BA_ "GenMsgSendType" BO_ 1585 0;
BA_ "NmMessage" BO_ 1585 1;
BA_ "Prio" BO_ 1583 0;
BA_ "MessageSubnet" BO_ 1583 9;
BA_ "GenMsgCycleTime" BO_ 1583 3000;
BA_ "GenMsgSendType" BO_ 1583 0;
BA_ "NmMessage" BO_ 1583 1;
BA_ "Prio" BO_ 1579 0;
BA_ "MessageSubnet" BO_ 1579 9;
BA_ "GenMsgCycleTime" BO_ 1579 3000;
BA_ "GenMsgSendType" BO_ 1579 0;
BA_ "NmMessage" BO_ 1579 1;
BA_ "Prio" BO_ 1575 0;
BA_ "MessageSubnet" BO_ 1575 9;
BA_ "GenMsgCycleTime" BO_ 1575 3000;
BA_ "GenMsgSendType" BO_ 1575 0;
BA_ "NmMessage" BO_ 1575 1;
BA_ "Prio" BO_ 1573 0;
BA_ "MessageSubnet" BO_ 1573 9;
BA_ "GenMsgCycleTime" BO_ 1573 3000;
BA_ "GenMsgSendType" BO_ 1573 0;
BA_ "NmMessage" BO_ 1573 1;
BA_ "Prio" BO_ 1571 0;
BA_ "MessageSubnet" BO_ 1571 9;
BA_ "GenMsgCycleTime" BO_ 1571 3000;
BA_ "GenMsgSendType" BO_ 1571 0;
BA_ "NmMessage" BO_ 1571 1;
BA_ "Prio" BO_ 1570 0;
BA_ "MessageSubnet" BO_ 1570 9;
BA_ "GenMsgCycleTime" BO_ 1570 3000;
BA_ "GenMsgSendType" BO_ 1570 0;
BA_ "NmMessage" BO_ 1570 1;
BA_ "Prio" BO_ 1569 0;
BA_ "MessageSubnet" BO_ 1569 9;
BA_ "GenMsgCycleTime" BO_ 1569 1000;
BA_ "GenMsgSendType" BO_ 1569 0;
BA_ "NmMessage" BO_ 1569 1;
BA_ "Prio" BO_ 1568 0;
BA_ "MessageSubnet" BO_ 1568 9;
BA_ "GenMsgCycleTime" BO_ 1568 3000;
BA_ "GenMsgSendType" BO_ 1568 0;
BA_ "NmMessage" BO_ 1568 1;
BA_ "MessageSubnet" BO_ 2151251968 9;
BA_ "GenMsgDelayTime" BO_ 2151251968 250;
BA_ "GenMsgCycleTime" BO_ 2151251968 1000;
BA_ "GenMsgSendType" BO_ 2151251968 0;
BA_ "MessageSubnet" BO_ 2153857024 9;
BA_ "GenMsgDelayTime" BO_ 2153857024 100;
BA_ "MessageSubnet" BO_ 2153865216 9;
BA_ "GenMsgDelayTime" BO_ 2153865216 100;
BA_ "GenSigSendType" SG_ 2152046592 RmClmCtrlLtSTempStReq 10;
BA_ "VNSigIntermediate" SG_ 2152046592 RmClmCtrlLtSTempStReq 1;
BA_ "SignalType" SG_ 2152046592 RmClmCtrlLtSTempStReq "ENM";
BA_ "SignalLongName" SG_ 2152046592 RmClmCtrlLtSTempStReq "Remote Climate Control Left Set Temperature Setting Request";
BA_ "GenSigSendType" SG_ 2152046592 RmClmCtrlRtSTempStReq 10;
BA_ "VNSigIntermediate" SG_ 2152046592 RmClmCtrlRtSTempStReq 1;
BA_ "SignalType" SG_ 2152046592 RmClmCtrlRtSTempStReq "ENM";
BA_ "SignalLongName" SG_ 2152046592 RmClmCtrlRtSTempStReq "Remote Climate Control Right Set Temperature Setting Request";
BA_ "GenSigSendType" SG_ 2152046592 RmClmCtrlFrntFanStReq 10;
BA_ "VNSigIntermediate" SG_ 2152046592 RmClmCtrlFrntFanStReq 1;
BA_ "SignalType" SG_ 2152046592 RmClmCtrlFrntFanStReq "ENM";
BA_ "SignalLongName" SG_ 2152046592 RmClmCtrlFrntFanStReq "Remote Climate Control Front Fan Setting Request";
BA_ "GenSigSendType" SG_ 2152046592 RmClmCtrlFLAirDtStReq 10;
BA_ "VNSigIntermediate" SG_ 2152046592 RmClmCtrlFLAirDtStReq 1;
BA_ "SignalType" SG_ 2152046592 RmClmCtrlFLAirDtStReq "ENM";
BA_ "SignalLongName" SG_ 2152046592 RmClmCtrlFLAirDtStReq "Remote Climate Control Front Left Air Distribution Setting Request";
BA_ "GenSigSendType" SG_ 2152046592 RmClmCtrlACSetReq 10;
BA_ "VNSigIntermediate" SG_ 2152046592 RmClmCtrlACSetReq 1;
BA_ "SignalType" SG_ 2152046592 RmClmCtrlACSetReq "ENM";
BA_ "SignalLongName" SG_ 2152046592 RmClmCtrlACSetReq "Remote Climate Control Air Conditioning Setting Request";
BA_ "GenSigSendType" SG_ 2152046592 RmClmCtrlClmModSetReq 10;
BA_ "VNSigIntermediate" SG_ 2152046592 RmClmCtrlClmModSetReq 1;
BA_ "SignalType" SG_ 2152046592 RmClmCtrlClmModSetReq "ENM";
BA_ "SignalLongName" SG_ 2152046592 RmClmCtrlClmModSetReq "Remote Climate Control Climate Mode Setting Request";
BA_ "GenSigSendType" SG_ 2152046592 RmClmCtrlRcrcSetReq 10;
BA_ "VNSigIntermediate" SG_ 2152046592 RmClmCtrlRcrcSetReq 1;
BA_ "SignalType" SG_ 2152046592 RmClmCtrlRcrcSetReq "ENM";
BA_ "SignalLongName" SG_ 2152046592 RmClmCtrlRcrcSetReq "Remote Climate Control Recirculation Setting Request";
BA_ "GenSigSendType" SG_ 2152046592 RmClmCtrlRrDfgSetReq 10;
BA_ "VNSigIntermediate" SG_ 2152046592 RmClmCtrlRrDfgSetReq 1;
BA_ "SignalType" SG_ 2152046592 RmClmCtrlRrDfgSetReq "ENM";
BA_ "SignalLongName" SG_ 2152046592 RmClmCtrlRrDfgSetReq "Remote Climate Control Rear Defog Setting Request";
BA_ "GenSigSendType" SG_ 2152046592 RmClmCtrlSyncSetReq 10;
BA_ "VNSigIntermediate" SG_ 2152046592 RmClmCtrlSyncSetReq 1;
BA_ "SignalType" SG_ 2152046592 RmClmCtrlSyncSetReq "ENM";
BA_ "SignalLongName" SG_ 2152046592 RmClmCtrlSyncSetReq "Remote Climate Control Sync Setting Request";
BA_ "GenSigSendType" SG_ 2152046592 RmClmCtrlHMIActIndReq 10;
BA_ "VNSigIntermediate" SG_ 2152046592 RmClmCtrlHMIActIndReq 1;
BA_ "SignalType" SG_ 2152046592 RmClmCtrlHMIActIndReq "ENM";
BA_ "SignalLongName" SG_ 2152046592 RmClmCtrlHMIActIndReq "Remote Climate Control HMI Active Indication Request";
BA_ "GenSigSendType" SG_ 2152030208 TnrFrqChnlReq 10;
BA_ "VNSigIntermediate" SG_ 2152030208 TnrFrqChnlReq 1;
BA_ "SignalType" SG_ 2152030208 TnrFrqChnlReq "ASC";
BA_ "SignalLongName" SG_ 2152030208 TnrFrqChnlReq "Tuner Frequency/Channel Request";
BA_ "GenSigSendType" SG_ 2152030208 TnrFrqBndReq 10;
BA_ "VNSigIntermediate" SG_ 2152030208 TnrFrqBndReq 1;
BA_ "SignalType" SG_ 2152030208 TnrFrqBndReq "ENM";
BA_ "SignalLongName" SG_ 2152030208 TnrFrqBndReq "Tuner Frequency Band Request";
BA_ "GenSigDeltaValue" SG_ 2150531072 OBHVDCCMinRmng 1;
BA_ "GenSigSendType" SG_ 2150531072 OBHVDCCMinRmng 12;
BA_ "VNSigInfotainment" SG_ 2150531072 OBHVDCCMinRmng 1;
BA_ "SignalType" SG_ 2150531072 OBHVDCCMinRmng "UNM";
BA_ "SignalLongName" SG_ 2150531072 OBHVDCCMinRmng "Off Board High Voltage DC Charging Minutes Remaining";
BA_ "VNSigAllNodes" SG_ 2150531072 OBHVDCCMinRmng 1;
BA_ "GenSigSendType" SG_ 2150531072 OBHVDCCCpltnTmDspFrmt 10;
BA_ "VNSigInfotainment" SG_ 2150531072 OBHVDCCCpltnTmDspFrmt 1;
BA_ "SignalType" SG_ 2150531072 OBHVDCCCpltnTmDspFrmt "ENM";
BA_ "SignalLongName" SG_ 2150531072 OBHVDCCCpltnTmDspFrmt "Off Board High Voltage DC Charging Completion Time Display Format";
BA_ "VNSigAllNodes" SG_ 2150531072 OBHVDCCCpltnTmDspFrmt 1;
BA_ "GenSigSendType" SG_ 2150531072 ClsHdToStrtVehIO 10;
BA_ "SignalType" SG_ 2150531072 ClsHdToStrtVehIO "BLN";
BA_ "SignalLongName" SG_ 2150531072 ClsHdToStrtVehIO "Close Hood To Start Vehicle Indication On";
BA_ "VNSigAllNodes" SG_ 2150531072 ClsHdToStrtVehIO 1;
BA_ "GenSigSendType" SG_ 2150531072 HVBChrgLmtBtnDspStat 10;
BA_ "VNSigInfotainment" SG_ 2150531072 HVBChrgLmtBtnDspStat 1;
BA_ "SignalType" SG_ 2150531072 HVBChrgLmtBtnDspStat "ENM";
BA_ "SignalLongName" SG_ 2150531072 HVBChrgLmtBtnDspStat "High Voltage Battery Charge Limit Button Display Status";
BA_ "VNSigAllNodes" SG_ 2150531072 HVBChrgLmtBtnDspStat 1;
BA_ "GenSigSendType" SG_ 2150531072 HVBHmChrgTmDspStat 10;
BA_ "VNSigInfotainment" SG_ 2150531072 HVBHmChrgTmDspStat 1;
BA_ "SignalType" SG_ 2150531072 HVBHmChrgTmDspStat "ENM";
BA_ "SignalLongName" SG_ 2150531072 HVBHmChrgTmDspStat "High Voltage Battery Home Charge Time Display Status";
BA_ "VNSigAllNodes" SG_ 2150531072 HVBHmChrgTmDspStat 1;
BA_ "GenSigSendType" SG_ 2150531072 HVBChrgTmDspStat 10;
BA_ "VNSigInfotainment" SG_ 2150531072 HVBChrgTmDspStat 1;
BA_ "SignalType" SG_ 2150531072 HVBChrgTmDspStat "ENM";
BA_ "SignalLongName" SG_ 2150531072 HVBChrgTmDspStat "High Voltage Battery Charge Time Display Status";
BA_ "VNSigAllNodes" SG_ 2150531072 HVBChrgTmDspStat 1;
BA_ "GenSigSendType" SG_ 2150531072 HVBChrgOvrdBtnDspStat 10;
BA_ "VNSigInfotainment" SG_ 2150531072 HVBChrgOvrdBtnDspStat 1;
BA_ "SignalType" SG_ 2150531072 HVBChrgOvrdBtnDspStat "ENM";
BA_ "SignalLongName" SG_ 2150531072 HVBChrgOvrdBtnDspStat "High Voltage Battery Charge Override Button Display Status";
BA_ "VNSigAllNodes" SG_ 2150531072 HVBChrgOvrdBtnDspStat 1;
BA_ "GenSigSendType" SG_ 2150531072 RegPwrLmtdIO 10;
BA_ "SignalType" SG_ 2150531072 RegPwrLmtdIO "BLN";
BA_ "SignalLongName" SG_ 2150531072 RegPwrLmtdIO "Regenerative Power Limited Indication On";
BA_ "VNSigAllNodes" SG_ 2150531072 RegPwrLmtdIO 1;
BA_ "GenSigSendType" SG_ 2150531072 RegPwrLmtdDspPrcntVs 10;
BA_ "SignalType" SG_ 2150531072 RegPwrLmtdDspPrcntVs "BLN";
BA_ "SignalLongName" SG_ 2150531072 RegPwrLmtdDspPrcntVs "Regenerative Power Limited Display Percent Visible";
BA_ "VNSigAllNodes" SG_ 2150531072 RegPwrLmtdDspPrcntVs 1;
BA_ "GenSigDeltaValue" SG_ 2150531072 RegPwrLmtdDspPrcnt 1;
BA_ "GenSigSendType" SG_ 2150531072 RegPwrLmtdDspPrcnt 12;
BA_ "SignalType" SG_ 2150531072 RegPwrLmtdDspPrcnt "SNM";
BA_ "SignalLongName" SG_ 2150531072 RegPwrLmtdDspPrcnt "Regenerative Power Limited Display Percent";
BA_ "VNSigAllNodes" SG_ 2150531072 RegPwrLmtdDspPrcnt 1;
BA_ "GenSigSendType" SG_ 2153897984 RunBrdExtdFtrAvail 10;
BA_ "SignalType" SG_ 2153897984 RunBrdExtdFtrAvail "BLN";
BA_ "SignalLongName" SG_ 2153897984 RunBrdExtdFtrAvail "Running Boards Extended Feature Available";
BA_ "VNSigAllNodes" SG_ 2153897984 RunBrdExtdFtrAvail 1;
BA_ "GenSigSendType" SG_ 2153897984 RunBrdOpMdCstCurrStVal 10;
BA_ "SignalType" SG_ 2153897984 RunBrdOpMdCstCurrStVal "ENM";
BA_ "SignalLongName" SG_ 2153897984 RunBrdOpMdCstCurrStVal "Running Boards Operating Mode Customization Current Setting Value";
BA_ "VNSigAllNodes" SG_ 2153897984 RunBrdOpMdCstCurrStVal 1;
BA_ "GenSigSendType" SG_ 2153897984 RunBrdOpMdCstStAvail 10;
BA_ "SignalType" SG_ 2153897984 RunBrdOpMdCstStAvail "BLN";
BA_ "SignalLongName" SG_ 2153897984 RunBrdOpMdCstStAvail "Running Boards Operating Mode Customization Setting Available";
BA_ "VNSigAllNodes" SG_ 2153897984 RunBrdOpMdCstStAvail 1;
BA_ "SignalType" SG_ 936 DgnInf "UNM";
BA_ "SignalLongName" SG_ 936 DgnInf "Diagnostic Information";
BA_ "VNSigDiagnostic" SG_ 936 DgnInf 1;
BA_ "VNSigAllNodes" SG_ 936 DgnInf 1;
BA_ "SignalType" SG_ 856 DgnInf "UNM";
BA_ "SignalLongName" SG_ 856 DgnInf "Diagnostic Information";
BA_ "VNSigDiagnostic" SG_ 856 DgnInf 1;
BA_ "VNSigAllNodes" SG_ 856 DgnInf 1;
BA_ "SignalType" SG_ 872 DgnInf "UNM";
BA_ "SignalLongName" SG_ 872 DgnInf "Diagnostic Information";
BA_ "VNSigDiagnostic" SG_ 872 DgnInf 1;
BA_ "VNSigAllNodes" SG_ 872 DgnInf 1;
BA_ "SignalType" SG_ 864 DgnInf "UNM";
BA_ "SignalLongName" SG_ 864 DgnInf "Diagnostic Information";
BA_ "VNSigDiagnostic" SG_ 864 DgnInf 1;
BA_ "VNSigAllNodes" SG_ 864 DgnInf 1;
BA_ "SignalType" SG_ 921 DgnInf "UNM";
BA_ "SignalLongName" SG_ 921 DgnInf "Diagnostic Information";
BA_ "VNSigDiagnostic" SG_ 921 DgnInf 1;
BA_ "VNSigAllNodes" SG_ 921 DgnInf 1;
BA_ "GenSigSendType" SG_ 2151202816 AuxHtrAlwd 10;
BA_ "SignalType" SG_ 2151202816 AuxHtrAlwd "BLN";
BA_ "SignalLongName" SG_ 2151202816 AuxHtrAlwd "Auxiliary Heater Allowed";
BA_ "VNSigAllNodes" SG_ 2151202816 AuxHtrAlwd 1;
BA_ "GenSigSendType" SG_ 2151202816 IPSnsrTpCvrTempFltd 10;
BA_ "SignalType" SG_ 2151202816 IPSnsrTpCvrTempFltd "BLN";
BA_ "SignalLongName" SG_ 2151202816 IPSnsrTpCvrTempFltd "Instrument Panel Sensor Top Cover Temperature faulted";
BA_ "VNSigAllNodes" SG_ 2151202816 IPSnsrTpCvrTempFltd 1;
BA_ "GenSigDeltaValue" SG_ 2151202816 IPSnsrTpCvrTemp 1;
BA_ "GenSigSendType" SG_ 2151202816 IPSnsrTpCvrTemp 12;
BA_ "SignalType" SG_ 2151202816 IPSnsrTpCvrTemp "UNM";
BA_ "SignalLongName" SG_ 2151202816 IPSnsrTpCvrTemp "Instrument Panel Sensor Top Cover Temperature";
BA_ "VNSigAllNodes" SG_ 2151202816 IPSnsrTpCvrTemp 1;
BA_ "GenSigDeltaValue" SG_ 2151202816 IPSnsrSolrElvtnAngl 1;
BA_ "GenSigSendType" SG_ 2151202816 IPSnsrSolrElvtnAngl 12;
BA_ "SignalType" SG_ 2151202816 IPSnsrSolrElvtnAngl "UNM";
BA_ "SignalLongName" SG_ 2151202816 IPSnsrSolrElvtnAngl "Instrument Panel Sensor Solar Elevation Angle";
BA_ "VNSigAllNodes" SG_ 2151202816 IPSnsrSolrElvtnAngl 1;
BA_ "GenSigDeltaValue" SG_ 2151202816 IPSnsrSolrAzmthAngl 1;
BA_ "GenSigSendType" SG_ 2151202816 IPSnsrSolrAzmthAngl 12;
BA_ "SignalType" SG_ 2151202816 IPSnsrSolrAzmthAngl "UNM";
BA_ "SignalLongName" SG_ 2151202816 IPSnsrSolrAzmthAngl "Instrument Panel Sensor Solar Azimuth Angle";
BA_ "VNSigAllNodes" SG_ 2151202816 IPSnsrSolrAzmthAngl 1;
BA_ "GenSigSendType" SG_ 2151202816 IPSnsrSolrAnglFltd 10;
BA_ "SignalType" SG_ 2151202816 IPSnsrSolrAnglFltd "BLN";
BA_ "SignalLongName" SG_ 2151202816 IPSnsrSolrAnglFltd "Instrument Panel Sensor Solar Angle Faulted";
BA_ "VNSigAllNodes" SG_ 2151202816 IPSnsrSolrAnglFltd 1;
BA_ "GenSigSendType" SG_ 2151202816 IPSnsrRwSolrIntFltd 10;
BA_ "SignalType" SG_ 2151202816 IPSnsrRwSolrIntFltd "BLN";
BA_ "SignalLongName" SG_ 2151202816 IPSnsrRwSolrIntFltd "Instrument Panel Sensor Raw Solar Intensity Faulted";
BA_ "VNSigAllNodes" SG_ 2151202816 IPSnsrRwSolrIntFltd 1;
BA_ "GenSigDeltaValue" SG_ 2151202816 IPSnsrRwSolrInt 1;
BA_ "GenSigSendType" SG_ 2151202816 IPSnsrRwSolrInt 12;
BA_ "SignalType" SG_ 2151202816 IPSnsrRwSolrInt "UNM";
BA_ "SignalLongName" SG_ 2151202816 IPSnsrRwSolrInt "Instrument Panel Sensor Raw Solar Intensity";
BA_ "VNSigAllNodes" SG_ 2151202816 IPSnsrRwSolrInt 1;
BA_ "GenSigSendType" SG_ 2151202816 ILSSCommErr 10;
BA_ "SignalType" SG_ 2151202816 ILSSCommErr "ENM";
BA_ "SignalLongName" SG_ 2151202816 ILSSCommErr "ILSS Communication Error";
BA_ "VNSigAllNodes" SG_ 2151202816 ILSSCommErr 1;
BA_ "GenSigSendType" SG_ 2151202816 RrWndDfgSwAtv 10;
BA_ "SignalType" SG_ 2151202816 RrWndDfgSwAtv "BLN";
BA_ "SignalLongName" SG_ 2151202816 RrWndDfgSwAtv "Rear Window Defog Switch Active";
BA_ "VNSigAllNodes" SG_ 2151202816 RrWndDfgSwAtv 1;
BA_ "GenSigSendType" SG_ 2151202816 RrWndDfgInhRq 10;
BA_ "SignalType" SG_ 2151202816 RrWndDfgInhRq "ENM";
BA_ "SignalLongName" SG_ 2151202816 RrWndDfgInhRq "Rear Window Defog Inhibit Request";
BA_ "VNSigAllNodes" SG_ 2151202816 RrWndDfgInhRq 1;
BA_ "GenSigSendType" SG_ 2151702528 LnMrkngIndRgt 10;
BA_ "SignalType" SG_ 2151702528 LnMrkngIndRgt "ENM";
BA_ "SignalLongName" SG_ 2151702528 LnMrkngIndRgt "Lane Marking Indication Right";
BA_ "VNSigAllNodes" SG_ 2151702528 LnMrkngIndRgt 1;
BA_ "GenSigSendType" SG_ 2151702528 LnMrkngIndLft 10;
BA_ "SignalType" SG_ 2151702528 LnMrkngIndLft "ENM";
BA_ "SignalLongName" SG_ 2151702528 LnMrkngIndLft "Lane Marking Indication Left";
BA_ "VNSigAllNodes" SG_ 2151702528 LnMrkngIndLft 1;
BA_ "GenSigSendType" SG_ 2151702528 LnKepAsstStIndRgt 10;
BA_ "SignalType" SG_ 2151702528 LnKepAsstStIndRgt "ENM";
BA_ "SignalLongName" SG_ 2151702528 LnKepAsstStIndRgt "Lane Keeping Assist State Indication Right";
BA_ "VNSigAllNodes" SG_ 2151702528 LnKepAsstStIndRgt 1;
BA_ "GenSigSendType" SG_ 2151702528 LnKepAsstStIndLft 10;
BA_ "SignalType" SG_ 2151702528 LnKepAsstStIndLft "ENM";
BA_ "SignalLongName" SG_ 2151702528 LnKepAsstStIndLft "Lane Keeping Assist State Indication Left";
BA_ "VNSigAllNodes" SG_ 2151702528 LnKepAsstStIndLft 1;
BA_ "GenSigSendType" SG_ 2151702528 LnKpngAstRecfblIndRq 10;
BA_ "SignalType" SG_ 2151702528 LnKpngAstRecfblIndRq "ENM";
BA_ "SignalLongName" SG_ 2151702528 LnKpngAstRecfblIndRq "Lane Keeping Assist Reconfigurable Icon Indication Request";
BA_ "VNSigAllNodes" SG_ 2151702528 LnKpngAstRecfblIndRq 1;
BA_ "GenSigSendType" SG_ 2156978176 WiFiPssPhrsDgts9to16_Mp 10;
BA_ "GenSigSendOnInit" SG_ 2156978176 WiFiPssPhrsDgts9to16_Mp 2;
BA_ "SignalType" SG_ 2156978176 WiFiPssPhrsDgts9to16_Mp "ASC";
BA_ "SignalLongName" SG_ 2156978176 WiFiPssPhrsDgts9to16_Mp "WiFi Pass Phrase Digits 9 to 16 Map";
BA_ "VNSigAllNodes" SG_ 2156978176 WiFiPssPhrsDgts9to16_Mp 1;
BA_ "GenSigSendType" SG_ 2156969984 WiFiPssPhrsDgts1to8_Mp 10;
BA_ "GenSigSendOnInit" SG_ 2156969984 WiFiPssPhrsDgts1to8_Mp 2;
BA_ "SignalType" SG_ 2156969984 WiFiPssPhrsDgts1to8_Mp "ASC";
BA_ "SignalLongName" SG_ 2156969984 WiFiPssPhrsDgts1to8_Mp "WiFi Pass Phrase Digits 1 to 8 Map";
BA_ "VNSigAllNodes" SG_ 2156969984 WiFiPssPhrsDgts1to8_Mp 1;
BA_ "GenSigSendType" SG_ 2156961792 WiFiSSIDDgts17to24_Mp 10;
BA_ "GenSigSendOnInit" SG_ 2156961792 WiFiSSIDDgts17to24_Mp 2;
BA_ "SignalType" SG_ 2156961792 WiFiSSIDDgts17to24_Mp "ASC";
BA_ "SignalLongName" SG_ 2156961792 WiFiSSIDDgts17to24_Mp "WiFi Service Set Identifier Digits 17 to 24 Map";
BA_ "VNSigAllNodes" SG_ 2156961792 WiFiSSIDDgts17to24_Mp 1;
BA_ "GenSigSendType" SG_ 2151923712 HLOCCA_Res4Avail 10;
BA_ "SignalType" SG_ 2151923712 HLOCCA_Res4Avail "BLN";
BA_ "PacketOrder" SG_ 2151923712 HLOCCA_Res4Avail 7;
BA_ "SignalLongName" SG_ 2151923712 HLOCCA_Res4Avail "Handsfree Liftgate Open Close Customization Available : Reserved 4 Available";
BA_ "VNSigAllNodes" SG_ 2151923712 HLOCCA_Res4Avail 1;
BA_ "GenSigSendType" SG_ 2151923712 HLOCCA_Res3Avail 10;
BA_ "SignalType" SG_ 2151923712 HLOCCA_Res3Avail "BLN";
BA_ "PacketOrder" SG_ 2151923712 HLOCCA_Res3Avail 6;
BA_ "SignalLongName" SG_ 2151923712 HLOCCA_Res3Avail "Handsfree Liftgate Open Close Customization Available : Reserved 3 Available";
BA_ "VNSigAllNodes" SG_ 2151923712 HLOCCA_Res3Avail 1;
BA_ "GenSigSendType" SG_ 2151923712 HLOCCA_Res2Avail 10;
BA_ "SignalType" SG_ 2151923712 HLOCCA_Res2Avail "BLN";
BA_ "PacketOrder" SG_ 2151923712 HLOCCA_Res2Avail 5;
BA_ "SignalLongName" SG_ 2151923712 HLOCCA_Res2Avail "Handsfree Liftgate Open Close Customization Available : Reserved 2 Available";
BA_ "VNSigAllNodes" SG_ 2151923712 HLOCCA_Res2Avail 1;
BA_ "GenSigSendType" SG_ 2151923712 HLOCCA_Res1Avail 10;
BA_ "SignalType" SG_ 2151923712 HLOCCA_Res1Avail "BLN";
BA_ "PacketOrder" SG_ 2151923712 HLOCCA_Res1Avail 4;
BA_ "SignalLongName" SG_ 2151923712 HLOCCA_Res1Avail "Handsfree Liftgate Open Close Customization Available : Reserved 1 Available";
BA_ "VNSigAllNodes" SG_ 2151923712 HLOCCA_Res1Avail 1;
BA_ "GenSigSendType" SG_ 2151923712 HLOCCA_OnOpnOnlyAvail 10;
BA_ "SignalType" SG_ 2151923712 HLOCCA_OnOpnOnlyAvail "BLN";
BA_ "PacketOrder" SG_ 2151923712 HLOCCA_OnOpnOnlyAvail 3;
BA_ "SignalLongName" SG_ 2151923712 HLOCCA_OnOpnOnlyAvail "Handsfree Liftgate Open Close Customization Available : On Open Only Available";
BA_ "VNSigAllNodes" SG_ 2151923712 HLOCCA_OnOpnOnlyAvail 1;
BA_ "GenSigSendType" SG_ 2151923712 HLOCCA_OnAvail 10;
BA_ "SignalType" SG_ 2151923712 HLOCCA_OnAvail "BLN";
BA_ "PacketOrder" SG_ 2151923712 HLOCCA_OnAvail 2;
BA_ "SignalLongName" SG_ 2151923712 HLOCCA_OnAvail "Handsfree Liftgate Open Close Customization Available : On Available";
BA_ "VNSigAllNodes" SG_ 2151923712 HLOCCA_OnAvail 1;
BA_ "GenSigSendType" SG_ 2151923712 HLOCCA_OffAvail 10;
BA_ "SignalType" SG_ 2151923712 HLOCCA_OffAvail "BLN";
BA_ "PacketOrder" SG_ 2151923712 HLOCCA_OffAvail 1;
BA_ "SignalLongName" SG_ 2151923712 HLOCCA_OffAvail "Handsfree Liftgate Open Close Customization Available : Off Available";
BA_ "VNSigAllNodes" SG_ 2151923712 HLOCCA_OffAvail 1;
BA_ "GenSigSendType" SG_ 2151923712 HLOCCstSetAvail 10;
BA_ "SignalType" SG_ 2151923712 HLOCCstSetAvail "BLN";
BA_ "SignalLongName" SG_ 2151923712 HLOCCstSetAvail "Handsfree Liftgate Open Close Customization Setting Available";
BA_ "VNSigAllNodes" SG_ 2151923712 HLOCCstSetAvail 1;
BA_ "GenSigSendType" SG_ 2151923712 HLOCCstCurrSetVal 10;
BA_ "SignalType" SG_ 2151923712 HLOCCstCurrSetVal "ENM";
BA_ "SignalLongName" SG_ 2151923712 HLOCCstCurrSetVal "Handfree Liftgate Open Close Customization Current Setting Value";
BA_ "VNSigAllNodes" SG_ 2151923712 HLOCCstCurrSetVal 1;
BA_ "GenSigDeltaValue" SG_ 2151923712 A1ERRAlrmTime 1;
BA_ "GenSigSendType" SG_ 2151923712 A1ERRAlrmTime 12;
BA_ "SignalType" SG_ 2151923712 A1ERRAlrmTime "UNM";
BA_ "PacketOrder" SG_ 2151923712 A1ERRAlrmTime 2;
BA_ "SignalLongName" SG_ 2151923712 A1ERRAlrmTime "Alarm 1 Extended Range Request : Alarm Time";
BA_ "VNSigAllNodes" SG_ 2151923712 A1ERRAlrmTime 1;
BA_ "GenSigSendType" SG_ 2151923712 A1ERRAlrmReq 10;
BA_ "SignalType" SG_ 2151923712 A1ERRAlrmReq "ENM";
BA_ "PacketOrder" SG_ 2151923712 A1ERRAlrmReq 1;
BA_ "SignalLongName" SG_ 2151923712 A1ERRAlrmReq "Alarm 1 Extended Range Request : Alarm Request";
BA_ "VNSigAllNodes" SG_ 2151923712 A1ERRAlrmReq 1;
BA_ "GenSigSendType" SG_ 2150236160 UlckKyStrCrptoDt2M 10;
BA_ "VNSigInfotainment" SG_ 2150236160 UlckKyStrCrptoDt2M 1;
BA_ "SignalType" SG_ 2150236160 UlckKyStrCrptoDt2M "ENM";
BA_ "SignalLongName" SG_ 2150236160 UlckKyStrCrptoDt2M "Unlock Key Store Cryptographic Data 2 Mask";
BA_ "VNSigAllNodes" SG_ 2150236160 UlckKyStrCrptoDt2M 1;
BA_ "GenSigDeltaValue" SG_ 2150236160 UlckKyStrCrptoDt2 1;
BA_ "GenSigSendType" SG_ 2150236160 UlckKyStrCrptoDt2 12;
BA_ "VNSigInfotainment" SG_ 2150236160 UlckKyStrCrptoDt2 1;
BA_ "SignalType" SG_ 2150236160 UlckKyStrCrptoDt2 "UNM";
BA_ "SignalLongName" SG_ 2150236160 UlckKyStrCrptoDt2 "Unlock Key Store Cryptographic Data 2";
BA_ "VNSigAllNodes" SG_ 2150236160 UlckKyStrCrptoDt2 1;
BA_ "GenSigSendType" SG_ 2150170624 UlckKyStrCrptoDt1M 10;
BA_ "VNSigInfotainment" SG_ 2150170624 UlckKyStrCrptoDt1M 1;
BA_ "SignalType" SG_ 2150170624 UlckKyStrCrptoDt1M "ENM";
BA_ "SignalLongName" SG_ 2150170624 UlckKyStrCrptoDt1M "Unlock Key Store Cryptographic Data 1 Mask";
BA_ "VNSigAllNodes" SG_ 2150170624 UlckKyStrCrptoDt1M 1;
BA_ "GenSigDeltaValue" SG_ 2150170624 UlckKyStrCrptoDt1 1;
BA_ "GenSigSendType" SG_ 2150170624 UlckKyStrCrptoDt1 12;
BA_ "VNSigInfotainment" SG_ 2150170624 UlckKyStrCrptoDt1 1;
BA_ "SignalType" SG_ 2150170624 UlckKyStrCrptoDt1 "UNM";
BA_ "SignalLongName" SG_ 2150170624 UlckKyStrCrptoDt1 "Unlock Key Store Cryptographic Data 1";
BA_ "VNSigAllNodes" SG_ 2150170624 UlckKyStrCrptoDt1 1;
BA_ "GenSigSendType" SG_ 2152628224 OBTCMstrStat 10;
BA_ "GenSigSendOnInit" SG_ 2152628224 OBTCMstrStat 1;
BA_ "VNSigInfotainment" SG_ 2152628224 OBTCMstrStat 1;
BA_ "SignalType" SG_ 2152628224 OBTCMstrStat "ENM";
BA_ "SignalLongName" SG_ 2152628224 OBTCMstrStat "On Board Tester Coordination Master Status";
BA_ "VNSigAllNodes" SG_ 2152628224 OBTCMstrStat 1;
BA_ "GenSigDeltaValue" SG_ 2152628224 OBTCR_ReqstrID 1;
BA_ "GenSigSendType" SG_ 2152628224 OBTCR_ReqstrID 12;
BA_ "VNSigInfotainment" SG_ 2152628224 OBTCR_ReqstrID 1;
BA_ "SignalType" SG_ 2152628224 OBTCR_ReqstrID "UNM";
BA_ "PacketOrder" SG_ 2152628224 OBTCR_ReqstrID 2;
BA_ "SignalLongName" SG_ 2152628224 OBTCR_ReqstrID "On Board Tester Coordination Response : Requester ID";
BA_ "VNSigAllNodes" SG_ 2152628224 OBTCR_ReqstrID 1;
BA_ "GenSigSendType" SG_ 2152628224 OBTCR_Stat 10;
BA_ "VNSigInfotainment" SG_ 2152628224 OBTCR_Stat 1;
BA_ "SignalType" SG_ 2152628224 OBTCR_Stat "ENM";
BA_ "PacketOrder" SG_ 2152628224 OBTCR_Stat 1;
BA_ "SignalLongName" SG_ 2152628224 OBTCR_Stat "On Board Tester Coordination Response : Status";
BA_ "VNSigAllNodes" SG_ 2152628224 OBTCR_Stat 1;
BA_ "GenSigSendType" SG_ 2154725376 AuxHtrAtv378 10;
BA_ "SignalType" SG_ 2154725376 AuxHtrAtv378 "BLN";
BA_ "SignalLongName" SG_ 2154725376 AuxHtrAtv378 "Auxiliary Heater Active";
BA_ "VNSigAllNodes" SG_ 2154725376 AuxHtrAtv378 1;
BA_ "GenSigSendType" SG_ 2154725376 AuxHtrRq 10;
BA_ "SignalType" SG_ 2154725376 AuxHtrRq "ENM";
BA_ "SignalLongName" SG_ 2154725376 AuxHtrRq "Auxiliary Heater Request";
BA_ "VNSigAllNodes" SG_ 2154725376 AuxHtrRq 1;
BA_ "GenSigDeltaValue" SG_ 2157051904 WSMR_WiFiStnMpMACAddr 1;
BA_ "GenSigSendType" SG_ 2157051904 WSMR_WiFiStnMpMACAddr 12;
BA_ "SignalType" SG_ 2157051904 WSMR_WiFiStnMpMACAddr "UNM";
BA_ "PacketOrder" SG_ 2157051904 WSMR_WiFiStnMpMACAddr 2;
BA_ "SignalLongName" SG_ 2157051904 WSMR_WiFiStnMpMACAddr "WiFI Station Map Request : WiFi Station Map Media Access Control Address";
BA_ "VNSigAllNodes" SG_ 2157051904 WSMR_WiFiStnMpMACAddr 1;
BA_ "GenSigSendType" SG_ 2157051904 WSMR_WiFiAssnReq 10;
BA_ "SignalType" SG_ 2157051904 WSMR_WiFiAssnReq "ENM";
BA_ "PacketOrder" SG_ 2157051904 WSMR_WiFiAssnReq 1;
BA_ "SignalLongName" SG_ 2157051904 WSMR_WiFiAssnReq "WiFI Station Map Request : WiFi Association Request";
BA_ "VNSigAllNodes" SG_ 2157051904 WSMR_WiFiAssnReq 1;
BA_ "GenSigSendType" SG_ 2156994560 WAPDM_SecurityType 10;
BA_ "GenSigSendOnInit" SG_ 2156994560 WAPDM_SecurityType 2;
BA_ "SignalType" SG_ 2156994560 WAPDM_SecurityType "ENM";
BA_ "PacketOrder" SG_ 2156994560 WAPDM_SecurityType 2;
BA_ "SignalLongName" SG_ 2156994560 WAPDM_SecurityType "WiFi Access Point Data Map : Security Type";
BA_ "VNSigAllNodes" SG_ 2156994560 WAPDM_SecurityType 1;
BA_ "GenSigSendType" SG_ 2156994560 WAPDM_WiFiEnStat 10;
BA_ "GenSigSendOnInit" SG_ 2156994560 WAPDM_WiFiEnStat 2;
BA_ "SignalType" SG_ 2156994560 WAPDM_WiFiEnStat "ENM";
BA_ "PacketOrder" SG_ 2156994560 WAPDM_WiFiEnStat 1;
BA_ "SignalLongName" SG_ 2156994560 WAPDM_WiFiEnStat "WiFi Access Point Data Map : WiFi Enabled Status";
BA_ "VNSigAllNodes" SG_ 2156994560 WAPDM_WiFiEnStat 1;
BA_ "GenSigSendType" SG_ 2156994560 WAPDM_EncrptnType 10;
BA_ "GenSigSendOnInit" SG_ 2156994560 WAPDM_EncrptnType 2;
BA_ "SignalType" SG_ 2156994560 WAPDM_EncrptnType "ENM";
BA_ "PacketOrder" SG_ 2156994560 WAPDM_EncrptnType 3;
BA_ "SignalLongName" SG_ 2156994560 WAPDM_EncrptnType "WiFi Access Point Data Map : Encryption Type";
BA_ "VNSigAllNodes" SG_ 2156994560 WAPDM_EncrptnType 1;
BA_ "GenSigSendType" SG_ 2156986368 WiFiPssPhrsDgts17to24_Mp 10;
BA_ "GenSigSendOnInit" SG_ 2156986368 WiFiPssPhrsDgts17to24_Mp 2;
BA_ "SignalType" SG_ 2156986368 WiFiPssPhrsDgts17to24_Mp "ASC";
BA_ "SignalLongName" SG_ 2156986368 WiFiPssPhrsDgts17to24_Mp "WiFi Pass Phrase Digits 17 to 24 Map";
BA_ "VNSigAllNodes" SG_ 2156986368 WiFiPssPhrsDgts17to24_Mp 1;
BA_ "GenSigSendType" SG_ 2158133248 ChrgCmpltFstChgingAct 10;
BA_ "VNSigInfotainment" SG_ 2158133248 ChrgCmpltFstChgingAct 1;
BA_ "SignalType" SG_ 2158133248 ChrgCmpltFstChgingAct "BLN";
BA_ "SignalLongName" SG_ 2158133248 ChrgCmpltFstChgingAct "Charge Complete Fast Charging Active";
BA_ "VNSigAllNodes" SG_ 2158133248 ChrgCmpltFstChgingAct 1;
BA_ "GenSigDeltaValue" SG_ 2158133248 TgtChrgLvlPctgCurStValPKIn 1;
BA_ "GenSigSendType" SG_ 2158133248 TgtChrgLvlPctgCurStValPKIn 12;
BA_ "SignalType" SG_ 2158133248 TgtChrgLvlPctgCurStValPKIn "UNM";
BA_ "SignalLongName" SG_ 2158133248 TgtChrgLvlPctgCurStValPKIn "Target Charge Level Percentage Current Setting Value for Peek In";
BA_ "VNSigAllNodes" SG_ 2158133248 TgtChrgLvlPctgCurStValPKIn 1;
BA_ "GenSigSendType" SG_ 2158133248 TrgtChrgLvlAct 10;
BA_ "SignalType" SG_ 2158133248 TrgtChrgLvlAct "BLN";
BA_ "SignalLongName" SG_ 2158133248 TrgtChrgLvlAct "Target Charge Level Active";
BA_ "VNSigAllNodes" SG_ 2158133248 TrgtChrgLvlAct 1;
BA_ "GenSigDeltaValue" SG_ 2158133248 HVDpltnMdMxCnfdcRgExt 1;
BA_ "GenSigSendType" SG_ 2158133248 HVDpltnMdMxCnfdcRgExt 12;
BA_ "SignalType" SG_ 2158133248 HVDpltnMdMxCnfdcRgExt "UNM";
BA_ "SignalLongName" SG_ 2158133248 HVDpltnMdMxCnfdcRgExt "High Voltage Depletion Mode Maximum Confidence Range Extended";
BA_ "VNSigAllNodes" SG_ 2158133248 HVDpltnMdMxCnfdcRgExt 1;
BA_ "GenSigDeltaValue" SG_ 2158133248 HVDpltnMdMiCnfdcRgExt 1;
BA_ "GenSigSendType" SG_ 2158133248 HVDpltnMdMiCnfdcRgExt 12;
BA_ "SignalType" SG_ 2158133248 HVDpltnMdMiCnfdcRgExt "UNM";
BA_ "SignalLongName" SG_ 2158133248 HVDpltnMdMiCnfdcRgExt "High Voltage Depletion Mode Minimum Confidence Range Extended";
BA_ "VNSigAllNodes" SG_ 2158133248 HVDpltnMdMiCnfdcRgExt 1;
BA_ "GenSigSendType" SG_ 2158133248 HTRCsStAvail 10;
BA_ "GenSigSendOnInit" SG_ 2158133248 HTRCsStAvail 1;
BA_ "VNSigInfotainment" SG_ 2158133248 HTRCsStAvail 1;
BA_ "SignalType" SG_ 2158133248 HTRCsStAvail "BLN";
BA_ "SignalLongName" SG_ 2158133248 HTRCsStAvail "Hill Top Reserve Customization Setting Available";
BA_ "VNSigAllNodes" SG_ 2158133248 HTRCsStAvail 1;
BA_ "GenSigSendType" SG_ 2158133248 HTRCsCrStVal 10;
BA_ "GenSigSendOnInit" SG_ 2158133248 HTRCsCrStVal 1;
BA_ "VNSigInfotainment" SG_ 2158133248 HTRCsCrStVal 1;
BA_ "SignalType" SG_ 2158133248 HTRCsCrStVal "ENM";
BA_ "SignalLongName" SG_ 2158133248 HTRCsCrStVal "Hill Top Reserve Customization Current Setting Value";
BA_ "VNSigAllNodes" SG_ 2158133248 HTRCsCrStVal 1;
BA_ "GenSigSendType" SG_ 2158133248 HTRCA_Res3Avail 10;
BA_ "GenSigSendOnInit" SG_ 2158133248 HTRCA_Res3Avail 1;
BA_ "VNSigInfotainment" SG_ 2158133248 HTRCA_Res3Avail 1;
BA_ "SignalType" SG_ 2158133248 HTRCA_Res3Avail "BLN";
BA_ "PacketOrder" SG_ 2158133248 HTRCA_Res3Avail 7;
BA_ "SignalLongName" SG_ 2158133248 HTRCA_Res3Avail "Hill Top Reserve Customization Available : Reserved3 Available";
BA_ "VNSigAllNodes" SG_ 2158133248 HTRCA_Res3Avail 1;
BA_ "GenSigSendType" SG_ 2158133248 HTRCA_Res2Avail 10;
BA_ "GenSigSendOnInit" SG_ 2158133248 HTRCA_Res2Avail 1;
BA_ "VNSigInfotainment" SG_ 2158133248 HTRCA_Res2Avail 1;
BA_ "SignalType" SG_ 2158133248 HTRCA_Res2Avail "BLN";
BA_ "PacketOrder" SG_ 2158133248 HTRCA_Res2Avail 6;
BA_ "SignalLongName" SG_ 2158133248 HTRCA_Res2Avail "Hill Top Reserve Customization Available : Reserved2 Available";
BA_ "VNSigAllNodes" SG_ 2158133248 HTRCA_Res2Avail 1;
BA_ "GenSigSendType" SG_ 2158133248 HTRCA_Res1Avail 10;
BA_ "GenSigSendOnInit" SG_ 2158133248 HTRCA_Res1Avail 1;
BA_ "VNSigInfotainment" SG_ 2158133248 HTRCA_Res1Avail 1;
BA_ "SignalType" SG_ 2158133248 HTRCA_Res1Avail "BLN";
BA_ "PacketOrder" SG_ 2158133248 HTRCA_Res1Avail 5;
BA_ "SignalLongName" SG_ 2158133248 HTRCA_Res1Avail "Hill Top Reserve Customization Available : Reserved1 Available";
BA_ "VNSigAllNodes" SG_ 2158133248 HTRCA_Res1Avail 1;
BA_ "GenSigSendType" SG_ 2158133248 HTRCA_OnAwAvail 10;
BA_ "GenSigSendOnInit" SG_ 2158133248 HTRCA_OnAwAvail 1;
BA_ "VNSigInfotainment" SG_ 2158133248 HTRCA_OnAwAvail 1;
BA_ "SignalType" SG_ 2158133248 HTRCA_OnAwAvail "BLN";
BA_ "PacketOrder" SG_ 2158133248 HTRCA_OnAwAvail 4;
BA_ "SignalLongName" SG_ 2158133248 HTRCA_OnAwAvail "Hill Top Reserve Customization Available : On Away Available";
BA_ "VNSigAllNodes" SG_ 2158133248 HTRCA_OnAwAvail 1;
BA_ "GenSigSendType" SG_ 2158133248 HTRCA_OnHmAvail 10;
BA_ "GenSigSendOnInit" SG_ 2158133248 HTRCA_OnHmAvail 1;
BA_ "VNSigInfotainment" SG_ 2158133248 HTRCA_OnHmAvail 1;
BA_ "SignalType" SG_ 2158133248 HTRCA_OnHmAvail "BLN";
BA_ "PacketOrder" SG_ 2158133248 HTRCA_OnHmAvail 3;
BA_ "SignalLongName" SG_ 2158133248 HTRCA_OnHmAvail "Hill Top Reserve Customization Available : On Home Available";
BA_ "VNSigAllNodes" SG_ 2158133248 HTRCA_OnHmAvail 1;
BA_ "GenSigSendType" SG_ 2158133248 HTRCA_OnAvail 10;
BA_ "GenSigSendOnInit" SG_ 2158133248 HTRCA_OnAvail 1;
BA_ "VNSigInfotainment" SG_ 2158133248 HTRCA_OnAvail 1;
BA_ "SignalType" SG_ 2158133248 HTRCA_OnAvail "BLN";
BA_ "PacketOrder" SG_ 2158133248 HTRCA_OnAvail 2;
BA_ "SignalLongName" SG_ 2158133248 HTRCA_OnAvail "Hill Top Reserve Customization Available : On Available";
BA_ "VNSigAllNodes" SG_ 2158133248 HTRCA_OnAvail 1;
BA_ "GenSigSendType" SG_ 2158133248 HTRCA_OffAvail 10;
BA_ "GenSigSendOnInit" SG_ 2158133248 HTRCA_OffAvail 1;
BA_ "VNSigInfotainment" SG_ 2158133248 HTRCA_OffAvail 1;
BA_ "SignalType" SG_ 2158133248 HTRCA_OffAvail "BLN";
BA_ "PacketOrder" SG_ 2158133248 HTRCA_OffAvail 1;
BA_ "SignalLongName" SG_ 2158133248 HTRCA_OffAvail "Hill Top Reserve Customization Available : Off Available";
BA_ "VNSigAllNodes" SG_ 2158133248 HTRCA_OffAvail 1;
BA_ "GenSigSendType" SG_ 2154651648 TAC_AudConctOutcm 10;
BA_ "GenSigSendOnInit" SG_ 2154651648 TAC_AudConctOutcm 1;
BA_ "PacketOrder" SG_ 2154651648 TAC_AudConctOutcm 2;
BA_ "VNSigInfotainment" SG_ 2154651648 TAC_AudConctOutcm 1;
BA_ "SignalType" SG_ 2154651648 TAC_AudConctOutcm "ENM";
BA_ "SignalLongName" SG_ 2154651648 TAC_AudConctOutcm "Telematics Audio Control : Audio Connection Outcome";
BA_ "VNSigAllNodes" SG_ 2154651648 TAC_AudConctOutcm 1;
BA_ "GenSigSendType" SG_ 2154651648 TAC_AudChConctStat 10;
BA_ "GenSigSendOnInit" SG_ 2154651648 TAC_AudChConctStat 1;
BA_ "PacketOrder" SG_ 2154651648 TAC_AudChConctStat 1;
BA_ "VNSigInfotainment" SG_ 2154651648 TAC_AudChConctStat 1;
BA_ "SignalType" SG_ 2154651648 TAC_AudChConctStat "ENM";
BA_ "SignalLongName" SG_ 2154651648 TAC_AudChConctStat "Telematics Audio Control : Audio Channel Connection Status";
BA_ "VNSigAllNodes" SG_ 2154651648 TAC_AudChConctStat 1;
BA_ "GenSigSendType" SG_ 2154635264 TAR_AudSrcStat 10;
BA_ "GenSigSendOnInit" SG_ 2154635264 TAR_AudSrcStat 1;
BA_ "PacketOrder" SG_ 2154635264 TAR_AudSrcStat 2;
BA_ "VNSigInfotainment" SG_ 2154635264 TAR_AudSrcStat 1;
BA_ "SignalType" SG_ 2154635264 TAR_AudSrcStat "ENM";
BA_ "SignalLongName" SG_ 2154635264 TAR_AudSrcStat "Telematics Audio Request : Audio Source Status";
BA_ "VNSigAllNodes" SG_ 2154635264 TAR_AudSrcStat 1;
BA_ "GenSigSendType" SG_ 2154635264 TAR_AudConctReq 10;
BA_ "GenSigSendOnInit" SG_ 2154635264 TAR_AudConctReq 1;
BA_ "PacketOrder" SG_ 2154635264 TAR_AudConctReq 1;
BA_ "VNSigInfotainment" SG_ 2154635264 TAR_AudConctReq 1;
BA_ "SignalType" SG_ 2154635264 TAR_AudConctReq "ENM";
BA_ "SignalLongName" SG_ 2154635264 TAR_AudConctReq "Telematics Audio Request : Audio Connection Request";
BA_ "VNSigAllNodes" SG_ 2154635264 TAR_AudConctReq 1;
BA_ "GenSigSendType" SG_ 2152529920 LVMAVC_SpchRcgnAval 10;
BA_ "GenSigSendOnInit" SG_ 2152529920 LVMAVC_SpchRcgnAval 1;
BA_ "PacketOrder" SG_ 2152529920 LVMAVC_SpchRcgnAval 6;
BA_ "VNSigInfotainment" SG_ 2152529920 LVMAVC_SpchRcgnAval 1;
BA_ "SignalType" SG_ 2152529920 LVMAVC_SpchRcgnAval "ENM";
BA_ "SignalLongName" SG_ 2152529920 LVMAVC_SpchRcgnAval "Low Volume Module Audio Video Command : Speech Recognition Available";
BA_ "VNSigAllNodes" SG_ 2152529920 LVMAVC_SpchRcgnAval 1;
BA_ "GenSigSendType" SG_ 2152529920 LVMAVC_RemSpchRcgnActn 10;
BA_ "GenSigSendOnInit" SG_ 2152529920 LVMAVC_RemSpchRcgnActn 1;
BA_ "PacketOrder" SG_ 2152529920 LVMAVC_RemSpchRcgnActn 5;
BA_ "VNSigInfotainment" SG_ 2152529920 LVMAVC_RemSpchRcgnActn 1;
BA_ "SignalType" SG_ 2152529920 LVMAVC_RemSpchRcgnActn "ENM";
BA_ "SignalLongName" SG_ 2152529920 LVMAVC_RemSpchRcgnActn "Low Volume Module Audio Video Command : Remote Speech Recognition Action";
BA_ "VNSigAllNodes" SG_ 2152529920 LVMAVC_RemSpchRcgnActn 1;
BA_ "GenSigSendType" SG_ 2152529920 LVMAVC_RemSpchRcgnID 10;
BA_ "GenSigSendOnInit" SG_ 2152529920 LVMAVC_RemSpchRcgnID 1;
BA_ "PacketOrder" SG_ 2152529920 LVMAVC_RemSpchRcgnID 4;
BA_ "VNSigInfotainment" SG_ 2152529920 LVMAVC_RemSpchRcgnID 1;
BA_ "SignalType" SG_ 2152529920 LVMAVC_RemSpchRcgnID "ENM";
BA_ "SignalLongName" SG_ 2152529920 LVMAVC_RemSpchRcgnID "Low Volume Module Audio Video Command : Remote Speech Recognition ID";
BA_ "VNSigAllNodes" SG_ 2152529920 LVMAVC_RemSpchRcgnID 1;
BA_ "GenSigSendType" SG_ 2152529920 LVMAVC_StreoAudRsp 10;
BA_ "GenSigSendOnInit" SG_ 2152529920 LVMAVC_StreoAudRsp 1;
BA_ "PacketOrder" SG_ 2152529920 LVMAVC_StreoAudRsp 3;
BA_ "VNSigInfotainment" SG_ 2152529920 LVMAVC_StreoAudRsp 1;
BA_ "SignalType" SG_ 2152529920 LVMAVC_StreoAudRsp "ENM";
BA_ "SignalLongName" SG_ 2152529920 LVMAVC_StreoAudRsp "Low Volume Module Audio Video Command : Stereo Audio Response";
BA_ "VNSigAllNodes" SG_ 2152529920 LVMAVC_StreoAudRsp 1;
BA_ "GenSigSendType" SG_ 2152529920 LVMAVC_PrmtAudRsp 10;
BA_ "GenSigSendOnInit" SG_ 2152529920 LVMAVC_PrmtAudRsp 1;
BA_ "PacketOrder" SG_ 2152529920 LVMAVC_PrmtAudRsp 2;
BA_ "VNSigInfotainment" SG_ 2152529920 LVMAVC_PrmtAudRsp 1;
BA_ "SignalType" SG_ 2152529920 LVMAVC_PrmtAudRsp "ENM";
BA_ "SignalLongName" SG_ 2152529920 LVMAVC_PrmtAudRsp "Low Volume Module Audio Video Command : Prompt Audio Response";
BA_ "VNSigAllNodes" SG_ 2152529920 LVMAVC_PrmtAudRsp 1;
BA_ "GenSigSendType" SG_ 2152529920 LVMAVC_RemtEnbl 10;
BA_ "GenSigSendOnInit" SG_ 2152529920 LVMAVC_RemtEnbl 1;
BA_ "PacketOrder" SG_ 2152529920 LVMAVC_RemtEnbl 1;
BA_ "VNSigInfotainment" SG_ 2152529920 LVMAVC_RemtEnbl 1;
BA_ "SignalType" SG_ 2152529920 LVMAVC_RemtEnbl "ENM";
BA_ "SignalLongName" SG_ 2152529920 LVMAVC_RemtEnbl "Low Volume Module Audio Video Command : Remote Enable";
BA_ "VNSigAllNodes" SG_ 2152529920 LVMAVC_RemtEnbl 1;
BA_ "GenSigSendType" SG_ 2152513536 LVMAVR_SpchRcgnAct 10;
BA_ "GenSigSendOnInit" SG_ 2152513536 LVMAVR_SpchRcgnAct 1;
BA_ "PacketOrder" SG_ 2152513536 LVMAVR_SpchRcgnAct 4;
BA_ "VNSigInfotainment" SG_ 2152513536 LVMAVR_SpchRcgnAct 1;
BA_ "SignalType" SG_ 2152513536 LVMAVR_SpchRcgnAct "ENM";
BA_ "SignalLongName" SG_ 2152513536 LVMAVR_SpchRcgnAct "Low Volume Module Audio Video Request : Speech Recognition Active";
BA_ "VNSigAllNodes" SG_ 2152513536 LVMAVR_SpchRcgnAct 1;
BA_ "GenSigSendType" SG_ 2152513536 LVMAVR_PrmtAudReq 10;
BA_ "GenSigSendOnInit" SG_ 2152513536 LVMAVR_PrmtAudReq 1;
BA_ "PacketOrder" SG_ 2152513536 LVMAVR_PrmtAudReq 3;
BA_ "VNSigInfotainment" SG_ 2152513536 LVMAVR_PrmtAudReq 1;
BA_ "SignalType" SG_ 2152513536 LVMAVR_PrmtAudReq "ENM";
BA_ "SignalLongName" SG_ 2152513536 LVMAVR_PrmtAudReq "Low Volume Module Audio Video Request : Prompt Audio Request";
BA_ "VNSigAllNodes" SG_ 2152513536 LVMAVR_PrmtAudReq 1;
BA_ "GenSigSendType" SG_ 2152513536 LVMAVR_StreoAudReq 10;
BA_ "GenSigSendOnInit" SG_ 2152513536 LVMAVR_StreoAudReq 1;
BA_ "PacketOrder" SG_ 2152513536 LVMAVR_StreoAudReq 2;
BA_ "VNSigInfotainment" SG_ 2152513536 LVMAVR_StreoAudReq 1;
BA_ "SignalType" SG_ 2152513536 LVMAVR_StreoAudReq "ENM";
BA_ "SignalLongName" SG_ 2152513536 LVMAVR_StreoAudReq "Low Volume Module Audio Video Request : Stereo Audio Request";
BA_ "VNSigAllNodes" SG_ 2152513536 LVMAVR_StreoAudReq 1;
BA_ "GenSigSendType" SG_ 2152513536 LVMAVR_DispReq 10;
BA_ "GenSigSendOnInit" SG_ 2152513536 LVMAVR_DispReq 1;
BA_ "PacketOrder" SG_ 2152513536 LVMAVR_DispReq 1;
BA_ "VNSigInfotainment" SG_ 2152513536 LVMAVR_DispReq 1;
BA_ "SignalType" SG_ 2152513536 LVMAVR_DispReq "ENM";
BA_ "SignalLongName" SG_ 2152513536 LVMAVR_DispReq "Low Volume Module Audio Video Request : Display Request";
BA_ "VNSigAllNodes" SG_ 2152513536 LVMAVR_DispReq 1;
BA_ "GenSigSendType" SG_ 2154889216 RSIHMIAnmReq 10;
BA_ "GenSigSendOnInit" SG_ 2154889216 RSIHMIAnmReq 1;
BA_ "VNSigInfotainment" SG_ 2154889216 RSIHMIAnmReq 1;
BA_ "SignalType" SG_ 2154889216 RSIHMIAnmReq "ENM";
BA_ "SignalLongName" SG_ 2154889216 RSIHMIAnmReq "Rear Seat Infotainment Human Machine Interface Animation Request";
BA_ "VNSigAllNodes" SG_ 2154889216 RSIHMIAnmReq 1;
BA_ "GenSigSendType" SG_ 2154889216 ClstrHMIAnmReq 10;
BA_ "VNSigInfotainment" SG_ 2154889216 ClstrHMIAnmReq 1;
BA_ "SignalType" SG_ 2154889216 ClstrHMIAnmReq "ENM";
BA_ "SignalLongName" SG_ 2154889216 ClstrHMIAnmReq "Cluster HMI Animation Request";
BA_ "VNSigAllNodes" SG_ 2154889216 ClstrHMIAnmReq 1;
BA_ "GenSigSendType" SG_ 2154872832 RmRflshUpdtAvail 10;
BA_ "VNSigInfotainment" SG_ 2154872832 RmRflshUpdtAvail 1;
BA_ "SignalType" SG_ 2154872832 RmRflshUpdtAvail "BLN";
BA_ "SignalLongName" SG_ 2154872832 RmRflshUpdtAvail "Remote Reflash Update Available";
BA_ "VNSigAllNodes" SG_ 2154872832 RmRflshUpdtAvail 1;
BA_ "GenSigSendType" SG_ 2154872832 InfoActvnReq 10;
BA_ "VNSigInfotainment" SG_ 2154872832 InfoActvnReq 1;
BA_ "SignalType" SG_ 2154872832 InfoActvnReq "BLN";
BA_ "SignalLongName" SG_ 2154872832 InfoActvnReq "Infotainment Activation Request";
BA_ "VNSigAllNodes" SG_ 2154872832 InfoActvnReq 1;
BA_ "GenSigSendType" SG_ 2154569728 InfotnmntSysSt 10;
BA_ "GenSigSendOnInit" SG_ 2154569728 InfotnmntSysSt 1;
BA_ "VNSigInfotainment" SG_ 2154569728 InfotnmntSysSt 1;
BA_ "SignalType" SG_ 2154569728 InfotnmntSysSt "ENM";
BA_ "SignalLongName" SG_ 2154569728 InfotnmntSysSt "Infotainment System State";
BA_ "VNSigAllNodes" SG_ 2154569728 InfotnmntSysSt 1;
BA_ "GenSigSendType" SG_ 2154594304 InfotnBkltngConfigSt 10;
BA_ "GenSigSendOnInit" SG_ 2154594304 InfotnBkltngConfigSt 1;
BA_ "VNSigInfotainment" SG_ 2154594304 InfotnBkltngConfigSt 1;
BA_ "SignalType" SG_ 2154594304 InfotnBkltngConfigSt "ENM";
BA_ "SignalLongName" SG_ 2154594304 InfotnBkltngConfigSt "Infotainment Backlighting Configuration State";
BA_ "VNSigAllNodes" SG_ 2154594304 InfotnBkltngConfigSt 1;
BA_ "GenSigSendType" SG_ 2154594304 ASTC_GblAudSnkMut 10;
BA_ "GenSigSendOnInit" SG_ 2154594304 ASTC_GblAudSnkMut 1;
BA_ "PacketOrder" SG_ 2154594304 ASTC_GblAudSnkMut 9;
BA_ "VNSigInfotainment" SG_ 2154594304 ASTC_GblAudSnkMut 1;
BA_ "SignalType" SG_ 2154594304 ASTC_GblAudSnkMut "BLN";
BA_ "SignalLongName" SG_ 2154594304 ASTC_GblAudSnkMut "Amplifier Settings Tone Control : Global Audio Sink Mute";
BA_ "VNSigAllNodes" SG_ 2154594304 ASTC_GblAudSnkMut 1;
BA_ "GenSigSendType" SG_ 2154594304 ASTC_AmpLwPwrSt 10;
BA_ "GenSigSendOnInit" SG_ 2154594304 ASTC_AmpLwPwrSt 1;
BA_ "PacketOrder" SG_ 2154594304 ASTC_AmpLwPwrSt 8;
BA_ "VNSigInfotainment" SG_ 2154594304 ASTC_AmpLwPwrSt 1;
BA_ "SignalType" SG_ 2154594304 ASTC_AmpLwPwrSt "BLN";
BA_ "SignalLongName" SG_ 2154594304 ASTC_AmpLwPwrSt "Amplifier Settings Tone Control : Amplfier Low Power State";
BA_ "VNSigAllNodes" SG_ 2154594304 ASTC_AmpLwPwrSt 1;
BA_ "GenSigDeltaValue" SG_ 2154594304 ASTC_MtxSnkMutRmpTm 1;
BA_ "GenSigSendType" SG_ 2154594304 ASTC_MtxSnkMutRmpTm 12;
BA_ "GenSigSendOnInit" SG_ 2154594304 ASTC_MtxSnkMutRmpTm 1;
BA_ "PacketOrder" SG_ 2154594304 ASTC_MtxSnkMutRmpTm 7;
BA_ "VNSigInfotainment" SG_ 2154594304 ASTC_MtxSnkMutRmpTm 1;
BA_ "SignalType" SG_ 2154594304 ASTC_MtxSnkMutRmpTm "UNM";
BA_ "SignalLongName" SG_ 2154594304 ASTC_MtxSnkMutRmpTm "Amplifier Settings Tone Control : Mutex Sink Mute Ramp Time";
BA_ "VNSigAllNodes" SG_ 2154594304 ASTC_MtxSnkMutRmpTm 1;
BA_ "GenSigSendType" SG_ 2154594304 ASTC_MtxSnkMut 10;
BA_ "GenSigSendOnInit" SG_ 2154594304 ASTC_MtxSnkMut 1;
BA_ "PacketOrder" SG_ 2154594304 ASTC_MtxSnkMut 6;
BA_ "VNSigInfotainment" SG_ 2154594304 ASTC_MtxSnkMut 1;
BA_ "SignalType" SG_ 2154594304 ASTC_MtxSnkMut "BLN";
BA_ "SignalLongName" SG_ 2154594304 ASTC_MtxSnkMut "Amplifier Settings Tone Control : Mutex Sink Mute";
BA_ "VNSigAllNodes" SG_ 2154594304 ASTC_MtxSnkMut 1;
BA_ "GenSigSendType" SG_ 2154594304 ASTC_DSPMd 10;
BA_ "GenSigSendOnInit" SG_ 2154594304 ASTC_DSPMd 1;
BA_ "PacketOrder" SG_ 2154594304 ASTC_DSPMd 5;
BA_ "VNSigInfotainment" SG_ 2154594304 ASTC_DSPMd 1;
BA_ "SignalType" SG_ 2154594304 ASTC_DSPMd "ENM";
BA_ "SignalLongName" SG_ 2154594304 ASTC_DSPMd "Amplifier Settings Tone Control : DSP Mode";
BA_ "VNSigAllNodes" SG_ 2154594304 ASTC_DSPMd 1;
BA_ "GenSigSendType" SG_ 2154594304 ASTC_VehNoisCmpnAct 10;
BA_ "GenSigSendOnInit" SG_ 2154594304 ASTC_VehNoisCmpnAct 1;
BA_ "PacketOrder" SG_ 2154594304 ASTC_VehNoisCmpnAct 4;
BA_ "VNSigInfotainment" SG_ 2154594304 ASTC_VehNoisCmpnAct 1;
BA_ "SignalType" SG_ 2154594304 ASTC_VehNoisCmpnAct "BLN";
BA_ "SignalLongName" SG_ 2154594304 ASTC_VehNoisCmpnAct "Amplifier Settings Tone Control : Vehicle Noise Compensation Active";
BA_ "VNSigAllNodes" SG_ 2154594304 ASTC_VehNoisCmpnAct 1;
BA_ "GenSigDeltaValue" SG_ 2154594304 ASTC_SurndLvl 1;
BA_ "GenSigSendType" SG_ 2154594304 ASTC_SurndLvl 12;
BA_ "GenSigSendOnInit" SG_ 2154594304 ASTC_SurndLvl 1;
BA_ "PacketOrder" SG_ 2154594304 ASTC_SurndLvl 3;
BA_ "VNSigInfotainment" SG_ 2154594304 ASTC_SurndLvl 1;
BA_ "SignalType" SG_ 2154594304 ASTC_SurndLvl "SNM";
BA_ "SignalLongName" SG_ 2154594304 ASTC_SurndLvl "Amplifier Settings Tone Control : Surround Level";
BA_ "VNSigAllNodes" SG_ 2154594304 ASTC_SurndLvl 1;
BA_ "GenSigSendType" SG_ 2154594304 ASTC_ChimSnkSpkrPos 10;
BA_ "GenSigSendOnInit" SG_ 2154594304 ASTC_ChimSnkSpkrPos 1;
BA_ "PacketOrder" SG_ 2154594304 ASTC_ChimSnkSpkrPos 2;
BA_ "VNSigInfotainment" SG_ 2154594304 ASTC_ChimSnkSpkrPos 1;
BA_ "SignalType" SG_ 2154594304 ASTC_ChimSnkSpkrPos "ENM";
BA_ "SignalLongName" SG_ 2154594304 ASTC_ChimSnkSpkrPos "Amplifier Settings Tone Control : Chime Sink Speaker Position";
BA_ "VNSigAllNodes" SG_ 2154594304 ASTC_ChimSnkSpkrPos 1;
BA_ "GenSigDeltaValue" SG_ 2154594304 ASTC_ChimSnkLvl 1;
BA_ "GenSigSendType" SG_ 2154594304 ASTC_ChimSnkLvl 12;
BA_ "GenSigSendOnInit" SG_ 2154594304 ASTC_ChimSnkLvl 1;
BA_ "PacketOrder" SG_ 2154594304 ASTC_ChimSnkLvl 1;
BA_ "VNSigInfotainment" SG_ 2154594304 ASTC_ChimSnkLvl 1;
BA_ "SignalType" SG_ 2154594304 ASTC_ChimSnkLvl "UNM";
BA_ "SignalLongName" SG_ 2154594304 ASTC_ChimSnkLvl "Amplifier Settings Tone Control : Chime Sink Level";
BA_ "VNSigAllNodes" SG_ 2154594304 ASTC_ChimSnkLvl 1;
BA_ "GenSigSendType" SG_ 2154586112 ASSLC_AutoLdnsCmpnAct 10;
BA_ "GenSigSendOnInit" SG_ 2154586112 ASSLC_AutoLdnsCmpnAct 1;
BA_ "PacketOrder" SG_ 2154586112 ASSLC_AutoLdnsCmpnAct 11;
BA_ "VNSigInfotainment" SG_ 2154586112 ASSLC_AutoLdnsCmpnAct 1;
BA_ "SignalType" SG_ 2154586112 ASSLC_AutoLdnsCmpnAct "BLN";
BA_ "SignalLongName" SG_ 2154586112 ASSLC_AutoLdnsCmpnAct "Amplifier Settings Sink Level Control : Automatic Loudness Compensation Active";
BA_ "VNSigAllNodes" SG_ 2154586112 ASSLC_AutoLdnsCmpnAct 1;
BA_ "GenSigSendType" SG_ 2154586112 ASSLC_VcSrcActOnMtx 10;
BA_ "GenSigSendOnInit" SG_ 2154586112 ASSLC_VcSrcActOnMtx 1;
BA_ "PacketOrder" SG_ 2154586112 ASSLC_VcSrcActOnMtx 10;
BA_ "VNSigInfotainment" SG_ 2154586112 ASSLC_VcSrcActOnMtx 1;
BA_ "SignalType" SG_ 2154586112 ASSLC_VcSrcActOnMtx "BLN";
BA_ "SignalLongName" SG_ 2154586112 ASSLC_VcSrcActOnMtx "Amplifier Settings Sink Level Control : Voice Source Active On Mutex";
BA_ "VNSigAllNodes" SG_ 2154586112 ASSLC_VcSrcActOnMtx 1;
BA_ "GenSigDeltaValue" SG_ 2154586112 ASSLC_MtxSnkTrbl 1;
BA_ "GenSigSendType" SG_ 2154586112 ASSLC_MtxSnkTrbl 12;
BA_ "GenSigSendOnInit" SG_ 2154586112 ASSLC_MtxSnkTrbl 1;
BA_ "PacketOrder" SG_ 2154586112 ASSLC_MtxSnkTrbl 9;
BA_ "VNSigInfotainment" SG_ 2154586112 ASSLC_MtxSnkTrbl 1;
BA_ "SignalType" SG_ 2154586112 ASSLC_MtxSnkTrbl "SNM";
BA_ "SignalLongName" SG_ 2154586112 ASSLC_MtxSnkTrbl "Amplifier Settings Sink Level Control : Mutex Sink Treble";
BA_ "VNSigAllNodes" SG_ 2154586112 ASSLC_MtxSnkTrbl 1;
BA_ "GenSigDeltaValue" SG_ 2154586112 ASSLC_MtxSnkMdrng 1;
BA_ "GenSigSendType" SG_ 2154586112 ASSLC_MtxSnkMdrng 12;
BA_ "GenSigSendOnInit" SG_ 2154586112 ASSLC_MtxSnkMdrng 1;
BA_ "PacketOrder" SG_ 2154586112 ASSLC_MtxSnkMdrng 8;
BA_ "VNSigInfotainment" SG_ 2154586112 ASSLC_MtxSnkMdrng 1;
BA_ "SignalType" SG_ 2154586112 ASSLC_MtxSnkMdrng "SNM";
BA_ "SignalLongName" SG_ 2154586112 ASSLC_MtxSnkMdrng "Amplifier Settings Sink Level Control : Mutex Sink Midrange";
BA_ "VNSigAllNodes" SG_ 2154586112 ASSLC_MtxSnkMdrng 1;
BA_ "GenSigDeltaValue" SG_ 2154586112 ASSLC_MtxSnkBass 1;
BA_ "GenSigSendType" SG_ 2154586112 ASSLC_MtxSnkBass 12;
BA_ "GenSigSendOnInit" SG_ 2154586112 ASSLC_MtxSnkBass 1;
BA_ "PacketOrder" SG_ 2154586112 ASSLC_MtxSnkBass 7;
BA_ "VNSigInfotainment" SG_ 2154586112 ASSLC_MtxSnkBass 1;
BA_ "SignalType" SG_ 2154586112 ASSLC_MtxSnkBass "SNM";
BA_ "SignalLongName" SG_ 2154586112 ASSLC_MtxSnkBass "Amplifier Settings Sink Level Control : Mutex Sink Bass";
BA_ "VNSigAllNodes" SG_ 2154586112 ASSLC_MtxSnkBass 1;
BA_ "GenSigDeltaValue" SG_ 2154586112 ASSLC_MtxSnkFd 1;
BA_ "GenSigSendType" SG_ 2154586112 ASSLC_MtxSnkFd 12;
BA_ "GenSigSendOnInit" SG_ 2154586112 ASSLC_MtxSnkFd 1;
BA_ "PacketOrder" SG_ 2154586112 ASSLC_MtxSnkFd 6;
BA_ "VNSigInfotainment" SG_ 2154586112 ASSLC_MtxSnkFd 1;
BA_ "SignalType" SG_ 2154586112 ASSLC_MtxSnkFd "SNM";
BA_ "SignalLongName" SG_ 2154586112 ASSLC_MtxSnkFd "Amplifier Settings Sink Level Control : Mutex Sink Fade";
BA_ "VNSigAllNodes" SG_ 2154586112 ASSLC_MtxSnkFd 1;
BA_ "GenSigDeltaValue" SG_ 2154586112 ASSLC_MtxSnkBal 1;
BA_ "GenSigSendType" SG_ 2154586112 ASSLC_MtxSnkBal 12;
BA_ "GenSigSendOnInit" SG_ 2154586112 ASSLC_MtxSnkBal 1;
BA_ "PacketOrder" SG_ 2154586112 ASSLC_MtxSnkBal 5;
BA_ "VNSigInfotainment" SG_ 2154586112 ASSLC_MtxSnkBal 1;
BA_ "SignalType" SG_ 2154586112 ASSLC_MtxSnkBal "SNM";
BA_ "SignalLongName" SG_ 2154586112 ASSLC_MtxSnkBal "Amplifier Settings Sink Level Control : Mutex Sink Balance";
BA_ "VNSigAllNodes" SG_ 2154586112 ASSLC_MtxSnkBal 1;
BA_ "GenSigDeltaValue" SG_ 2154586112 ASSLC_FvSnkLvl 1;
BA_ "GenSigSendType" SG_ 2154586112 ASSLC_FvSnkLvl 12;
BA_ "GenSigSendOnInit" SG_ 2154586112 ASSLC_FvSnkLvl 1;
BA_ "PacketOrder" SG_ 2154586112 ASSLC_FvSnkLvl 4;
BA_ "VNSigInfotainment" SG_ 2154586112 ASSLC_FvSnkLvl 1;
BA_ "SignalType" SG_ 2154586112 ASSLC_FvSnkLvl "UNM";
BA_ "SignalLongName" SG_ 2154586112 ASSLC_FvSnkLvl "Amplifier Settings Sink Level Control : Five Sink Level";
BA_ "VNSigAllNodes" SG_ 2154586112 ASSLC_FvSnkLvl 1;
BA_ "GenSigDeltaValue" SG_ 2154586112 ASSLC_AudFdbkSnkLvl 1;
BA_ "GenSigSendType" SG_ 2154586112 ASSLC_AudFdbkSnkLvl 12;
BA_ "GenSigSendOnInit" SG_ 2154586112 ASSLC_AudFdbkSnkLvl 1;
BA_ "PacketOrder" SG_ 2154586112 ASSLC_AudFdbkSnkLvl 3;
BA_ "VNSigInfotainment" SG_ 2154586112 ASSLC_AudFdbkSnkLvl 1;
BA_ "SignalType" SG_ 2154586112 ASSLC_AudFdbkSnkLvl "UNM";
BA_ "SignalLongName" SG_ 2154586112 ASSLC_AudFdbkSnkLvl "Amplifier Settings Sink Level Control : Audible Feedback Sink Level";
BA_ "VNSigAllNodes" SG_ 2154586112 ASSLC_AudFdbkSnkLvl 1;
BA_ "GenSigDeltaValue" SG_ 2154586112 ASSLC_MxPrmtSnkLvl 1;
BA_ "GenSigSendType" SG_ 2154586112 ASSLC_MxPrmtSnkLvl 12;
BA_ "GenSigSendOnInit" SG_ 2154586112 ASSLC_MxPrmtSnkLvl 1;
BA_ "PacketOrder" SG_ 2154586112 ASSLC_MxPrmtSnkLvl 2;
BA_ "VNSigInfotainment" SG_ 2154586112 ASSLC_MxPrmtSnkLvl 1;
BA_ "SignalType" SG_ 2154586112 ASSLC_MxPrmtSnkLvl "UNM";
BA_ "SignalLongName" SG_ 2154586112 ASSLC_MxPrmtSnkLvl "Amplifier Settings Sink Level Control : Mix Prompt Sink Level";
BA_ "VNSigAllNodes" SG_ 2154586112 ASSLC_MxPrmtSnkLvl 1;
BA_ "GenSigDeltaValue" SG_ 2154586112 ASSLC_MtxSnkLvl 1;
BA_ "GenSigSendType" SG_ 2154586112 ASSLC_MtxSnkLvl 12;
BA_ "GenSigSendOnInit" SG_ 2154586112 ASSLC_MtxSnkLvl 1;
BA_ "PacketOrder" SG_ 2154586112 ASSLC_MtxSnkLvl 1;
BA_ "VNSigInfotainment" SG_ 2154586112 ASSLC_MtxSnkLvl 1;
BA_ "SignalType" SG_ 2154586112 ASSLC_MtxSnkLvl "UNM";
BA_ "SignalLongName" SG_ 2154586112 ASSLC_MtxSnkLvl "Amplifier Settings Sink Level Control : Mutex Sink Level";
BA_ "VNSigAllNodes" SG_ 2154586112 ASSLC_MtxSnkLvl 1;
BA_ "GenSigSendType" SG_ 2154577920 ASS_DSPMd7Prsnt 10;
BA_ "GenSigSendOnInit" SG_ 2154577920 ASS_DSPMd7Prsnt 1;
BA_ "VNSigInfotainment" SG_ 2154577920 ASS_DSPMd7Prsnt 1;
BA_ "SignalType" SG_ 2154577920 ASS_DSPMd7Prsnt "BLN";
BA_ "PacketOrder" SG_ 2154577920 ASS_DSPMd7Prsnt 13;
BA_ "SignalLongName" SG_ 2154577920 ASS_DSPMd7Prsnt "Amplifier Sink Status : DSP Mode 7 Present";
BA_ "VNSigAllNodes" SG_ 2154577920 ASS_DSPMd7Prsnt 1;
BA_ "GenSigSendType" SG_ 2154577920 ASS_DSPMd6Prsnt 10;
BA_ "GenSigSendOnInit" SG_ 2154577920 ASS_DSPMd6Prsnt 1;
BA_ "VNSigInfotainment" SG_ 2154577920 ASS_DSPMd6Prsnt 1;
BA_ "SignalType" SG_ 2154577920 ASS_DSPMd6Prsnt "BLN";
BA_ "PacketOrder" SG_ 2154577920 ASS_DSPMd6Prsnt 12;
BA_ "SignalLongName" SG_ 2154577920 ASS_DSPMd6Prsnt "Amplifier Sink Status : DSP Mode 6 Present";
BA_ "VNSigAllNodes" SG_ 2154577920 ASS_DSPMd6Prsnt 1;
BA_ "GenSigSendType" SG_ 2154577920 ASS_DSPMd5Prsnt 10;
BA_ "GenSigSendOnInit" SG_ 2154577920 ASS_DSPMd5Prsnt 1;
BA_ "VNSigInfotainment" SG_ 2154577920 ASS_DSPMd5Prsnt 1;
BA_ "SignalType" SG_ 2154577920 ASS_DSPMd5Prsnt "BLN";
BA_ "PacketOrder" SG_ 2154577920 ASS_DSPMd5Prsnt 11;
BA_ "SignalLongName" SG_ 2154577920 ASS_DSPMd5Prsnt "Amplifier Sink Status : DSP Mode 5 Present";
BA_ "VNSigAllNodes" SG_ 2154577920 ASS_DSPMd5Prsnt 1;
BA_ "GenSigSendType" SG_ 2154577920 ASS_DSPMd4Prsnt 10;
BA_ "GenSigSendOnInit" SG_ 2154577920 ASS_DSPMd4Prsnt 1;
BA_ "VNSigInfotainment" SG_ 2154577920 ASS_DSPMd4Prsnt 1;
BA_ "SignalType" SG_ 2154577920 ASS_DSPMd4Prsnt "BLN";
BA_ "PacketOrder" SG_ 2154577920 ASS_DSPMd4Prsnt 10;
BA_ "SignalLongName" SG_ 2154577920 ASS_DSPMd4Prsnt "Amplifier Sink Status : DSP Mode 4 Present";
BA_ "VNSigAllNodes" SG_ 2154577920 ASS_DSPMd4Prsnt 1;
BA_ "GenSigSendType" SG_ 2154577920 ASS_DSPMd3Prsnt 10;
BA_ "GenSigSendOnInit" SG_ 2154577920 ASS_DSPMd3Prsnt 1;
BA_ "VNSigInfotainment" SG_ 2154577920 ASS_DSPMd3Prsnt 1;
BA_ "SignalType" SG_ 2154577920 ASS_DSPMd3Prsnt "BLN";
BA_ "PacketOrder" SG_ 2154577920 ASS_DSPMd3Prsnt 9;
BA_ "SignalLongName" SG_ 2154577920 ASS_DSPMd3Prsnt "Amplifier Sink Status : DSP Mode 3 Present";
BA_ "VNSigAllNodes" SG_ 2154577920 ASS_DSPMd3Prsnt 1;
BA_ "GenSigSendType" SG_ 2154577920 ASS_DSPMd2Prsnt 10;
BA_ "GenSigSendOnInit" SG_ 2154577920 ASS_DSPMd2Prsnt 1;
BA_ "VNSigInfotainment" SG_ 2154577920 ASS_DSPMd2Prsnt 1;
BA_ "SignalType" SG_ 2154577920 ASS_DSPMd2Prsnt "BLN";
BA_ "PacketOrder" SG_ 2154577920 ASS_DSPMd2Prsnt 8;
BA_ "SignalLongName" SG_ 2154577920 ASS_DSPMd2Prsnt "Amplifier Sink Status : DSP Mode 2 Present";
BA_ "VNSigAllNodes" SG_ 2154577920 ASS_DSPMd2Prsnt 1;
BA_ "GenSigSendType" SG_ 2154577920 ASS_DSPMd1Prsnt 10;
BA_ "GenSigSendOnInit" SG_ 2154577920 ASS_DSPMd1Prsnt 1;
BA_ "VNSigInfotainment" SG_ 2154577920 ASS_DSPMd1Prsnt 1;
BA_ "SignalType" SG_ 2154577920 ASS_DSPMd1Prsnt "BLN";
BA_ "PacketOrder" SG_ 2154577920 ASS_DSPMd1Prsnt 7;
BA_ "SignalLongName" SG_ 2154577920 ASS_DSPMd1Prsnt "Amplifier Sink Status : DSP Mode 1 Present";
BA_ "VNSigAllNodes" SG_ 2154577920 ASS_DSPMd1Prsnt 1;
BA_ "GenSigSendType" SG_ 2154577920 ASS_DSPMd0Prsnt 10;
BA_ "GenSigSendOnInit" SG_ 2154577920 ASS_DSPMd0Prsnt 1;
BA_ "VNSigInfotainment" SG_ 2154577920 ASS_DSPMd0Prsnt 1;
BA_ "SignalType" SG_ 2154577920 ASS_DSPMd0Prsnt "BLN";
BA_ "PacketOrder" SG_ 2154577920 ASS_DSPMd0Prsnt 6;
BA_ "SignalLongName" SG_ 2154577920 ASS_DSPMd0Prsnt "Amplifier Sink Status : DSP Mode 0 Present";
BA_ "VNSigAllNodes" SG_ 2154577920 ASS_DSPMd0Prsnt 1;
BA_ "GenSigSendType" SG_ 2154577920 ASS_SurndAvail 10;
BA_ "GenSigSendOnInit" SG_ 2154577920 ASS_SurndAvail 1;
BA_ "PacketOrder" SG_ 2154577920 ASS_SurndAvail 5;
BA_ "VNSigInfotainment" SG_ 2154577920 ASS_SurndAvail 1;
BA_ "SignalType" SG_ 2154577920 ASS_SurndAvail "BLN";
BA_ "SignalLongName" SG_ 2154577920 ASS_SurndAvail "Amplifier Sink Status : Suround Available";
BA_ "VNSigAllNodes" SG_ 2154577920 ASS_SurndAvail 1;
BA_ "GenSigSendType" SG_ 2154577920 ASS_DSPAvail 10;
BA_ "GenSigSendOnInit" SG_ 2154577920 ASS_DSPAvail 1;
BA_ "PacketOrder" SG_ 2154577920 ASS_DSPAvail 4;
BA_ "VNSigInfotainment" SG_ 2154577920 ASS_DSPAvail 1;
BA_ "SignalType" SG_ 2154577920 ASS_DSPAvail "BLN";
BA_ "SignalLongName" SG_ 2154577920 ASS_DSPAvail "Amplifier Sink Status : DSP Available";
BA_ "VNSigAllNodes" SG_ 2154577920 ASS_DSPAvail 1;
BA_ "GenSigSendType" SG_ 2154577920 ASS_VehNoisCmpnAvail 10;
BA_ "GenSigSendOnInit" SG_ 2154577920 ASS_VehNoisCmpnAvail 1;
BA_ "PacketOrder" SG_ 2154577920 ASS_VehNoisCmpnAvail 3;
BA_ "VNSigInfotainment" SG_ 2154577920 ASS_VehNoisCmpnAvail 1;
BA_ "SignalType" SG_ 2154577920 ASS_VehNoisCmpnAvail "BLN";
BA_ "SignalLongName" SG_ 2154577920 ASS_VehNoisCmpnAvail "Amplifier Sink Status : Vehicle Noise Compensation Available";
BA_ "VNSigAllNodes" SG_ 2154577920 ASS_VehNoisCmpnAvail 1;
BA_ "GenSigSendType" SG_ 2154577920 ASS_PhLckdLpLckd 10;
BA_ "GenSigSendOnInit" SG_ 2154577920 ASS_PhLckdLpLckd 1;
BA_ "PacketOrder" SG_ 2154577920 ASS_PhLckdLpLckd 2;
BA_ "VNSigInfotainment" SG_ 2154577920 ASS_PhLckdLpLckd 1;
BA_ "SignalType" SG_ 2154577920 ASS_PhLckdLpLckd "BLN";
BA_ "SignalLongName" SG_ 2154577920 ASS_PhLckdLpLckd "Amplifier Sink Status : Phase Locked Loop Locked";
BA_ "VNSigAllNodes" SG_ 2154577920 ASS_PhLckdLpLckd 1;
BA_ "GenSigSendType" SG_ 2154577920 ASS_MtxSnkMutStat 10;
BA_ "GenSigSendOnInit" SG_ 2154577920 ASS_MtxSnkMutStat 1;
BA_ "PacketOrder" SG_ 2154577920 ASS_MtxSnkMutStat 1;
BA_ "VNSigInfotainment" SG_ 2154577920 ASS_MtxSnkMutStat 1;
BA_ "SignalType" SG_ 2154577920 ASS_MtxSnkMutStat "BLN";
BA_ "SignalLongName" SG_ 2154577920 ASS_MtxSnkMutStat "Amplifier Sink Status : Mutex Sink Mute Status";
BA_ "VNSigAllNodes" SG_ 2154577920 ASS_MtxSnkMutStat 1;
BA_ "GenSigSendType" SG_ 2151931904 FourWhlDrvIdReqExtRng 10;
BA_ "SignalType" SG_ 2151931904 FourWhlDrvIdReqExtRng "ENM";
BA_ "SignalLongName" SG_ 2151931904 FourWhlDrvIdReqExtRng "Four Wheel Drive Indication Request Extended Range";
BA_ "VNSigAllNodes" SG_ 2151931904 FourWhlDrvIdReqExtRng 1;
BA_ "GenSigDeltaValue" SG_ 2151931904 LnchCtrlTmrVal 1;
BA_ "GenSigSendType" SG_ 2151931904 LnchCtrlTmrVal 12;
BA_ "SignalType" SG_ 2151931904 LnchCtrlTmrVal "UNM";
BA_ "SignalLongName" SG_ 2151931904 LnchCtrlTmrVal "Launch Control Timer Value";
BA_ "VNSigAllNodes" SG_ 2151931904 LnchCtrlTmrVal 1;
BA_ "GenSigDeltaValue" SG_ 2151931904 LnchCtrlBrkPresVal 1;
BA_ "GenSigSendType" SG_ 2151931904 LnchCtrlBrkPresVal 12;
BA_ "SignalType" SG_ 2151931904 LnchCtrlBrkPresVal "UNM";
BA_ "SignalLongName" SG_ 2151931904 LnchCtrlBrkPresVal "Launch Control Brake Pressure Value";
BA_ "VNSigAllNodes" SG_ 2151931904 LnchCtrlBrkPresVal 1;
BA_ "GenSigSendType" SG_ 2151931904 FuelMdTrnstnIndReq 10;
BA_ "SignalType" SG_ 2151931904 FuelMdTrnstnIndReq "ENM";
BA_ "SignalLongName" SG_ 2151931904 FuelMdTrnstnIndReq "Fuel Mode Transition Indication Request";
BA_ "VNSigAllNodes" SG_ 2151931904 FuelMdTrnstnIndReq 1;
BA_ "GenSigSendType" SG_ 2151931904 BiFuelRflGaslinIndReq 10;
BA_ "SignalType" SG_ 2151931904 BiFuelRflGaslinIndReq "ENM";
BA_ "SignalLongName" SG_ 2151931904 BiFuelRflGaslinIndReq "Bi Fuel Refill Gasoline Indication Request";
BA_ "VNSigAllNodes" SG_ 2151931904 BiFuelRflGaslinIndReq 1;
BA_ "GenSigDeltaValue" SG_ 2151931904 AutoShtdwnTmr 1;
BA_ "GenSigSendType" SG_ 2151931904 AutoShtdwnTmr 12;
BA_ "SignalType" SG_ 2151931904 AutoShtdwnTmr "UNM";
BA_ "SignalLongName" SG_ 2151931904 AutoShtdwnTmr "Automatic Shutdown Timer";
BA_ "VNSigAllNodes" SG_ 2151931904 AutoShtdwnTmr 1;
BA_ "GenSigSendType" SG_ 2151931904 AutoShtdwnIO 10;
BA_ "SignalType" SG_ 2151931904 AutoShtdwnIO "BLN";
BA_ "SignalLongName" SG_ 2151931904 AutoShtdwnIO "Automatic Shutdown Indication On";
BA_ "VNSigAllNodes" SG_ 2151931904 AutoShtdwnIO 1;
BA_ "GenSigSendType" SG_ 2151931904 TCSTempDsblReqIO 10;
BA_ "SignalType" SG_ 2151931904 TCSTempDsblReqIO "BLN";
BA_ "SignalLongName" SG_ 2151931904 TCSTempDsblReqIO "Traction Control System Temporary Disable Request Indication On";
BA_ "VNSigAllNodes" SG_ 2151931904 TCSTempDsblReqIO 1;
BA_ "GenSigSendType" SG_ 2151931904 VehStbCmptvMdCstAvl 10;
BA_ "SignalType" SG_ 2151931904 VehStbCmptvMdCstAvl "BLN";
BA_ "SignalLongName" SG_ 2151931904 VehStbCmptvMdCstAvl "Vehicle Stability Competitive Mode Customization Available";
BA_ "VNSigAllNodes" SG_ 2151931904 VehStbCmptvMdCstAvl 1;
BA_ "GenSigSendType" SG_ 2151931904 VehStbEnmntCstAvl 10;
BA_ "SignalType" SG_ 2151931904 VehStbEnmntCstAvl "BLN";
BA_ "SignalLongName" SG_ 2151931904 VehStbEnmntCstAvl "Vehicle Stability Enhancement Customization Available";
BA_ "VNSigAllNodes" SG_ 2151931904 VehStbEnmntCstAvl 1;
BA_ "GenSigSendType" SG_ 2151931904 TCSysCstAvl 10;
BA_ "SignalType" SG_ 2151931904 TCSysCstAvl "BLN";
BA_ "SignalLongName" SG_ 2151931904 TCSysCstAvl "Traction Control System Customization Available";
BA_ "VNSigAllNodes" SG_ 2151931904 TCSysCstAvl 1;
BA_ "GenSigSendType" SG_ 2151931904 VehStbCmptvMdCurSt 10;
BA_ "SignalType" SG_ 2151931904 VehStbCmptvMdCurSt "ENM";
BA_ "SignalLongName" SG_ 2151931904 VehStbCmptvMdCurSt "Vehicle Stability Competitive Mode Current State";
BA_ "VNSigAllNodes" SG_ 2151931904 VehStbCmptvMdCurSt 1;
BA_ "GenSigSendType" SG_ 2151931904 VehStbEnhmntCurSt 10;
BA_ "SignalType" SG_ 2151931904 VehStbEnhmntCurSt "ENM";
BA_ "SignalLongName" SG_ 2151931904 VehStbEnhmntCurSt "Vehicle Stability Enhancement Current State";
BA_ "VNSigAllNodes" SG_ 2151931904 VehStbEnhmntCurSt 1;
BA_ "GenSigSendType" SG_ 2151931904 TCSysCurSt 10;
BA_ "SignalType" SG_ 2151931904 TCSysCurSt "ENM";
BA_ "SignalLongName" SG_ 2151931904 TCSysCurSt "Traction Control System Current State";
BA_ "VNSigAllNodes" SG_ 2151931904 TCSysCurSt 1;
BA_ "GenSigSendType" SG_ 2151931904 TracAndStbScrnCnfg 10;
BA_ "SignalType" SG_ 2151931904 TracAndStbScrnCnfg "ENM";
BA_ "SignalLongName" SG_ 2151931904 TracAndStbScrnCnfg "Traction And Stability Screen Configuration";
BA_ "VNSigAllNodes" SG_ 2151931904 TracAndStbScrnCnfg 1;
BA_ "GenSigSendType" SG_ 2151931904 ElctShfPriLtdPerfMdIO 10;
BA_ "SignalType" SG_ 2151931904 ElctShfPriLtdPerfMdIO "BLN";
BA_ "SignalLongName" SG_ 2151931904 ElctShfPriLtdPerfMdIO "Electronic Shift Primary Limited Performance Mode Indication On";
BA_ "VNSigAllNodes" SG_ 2151931904 ElctShfPriLtdPerfMdIO 1;
BA_ "GenSigSendType" SG_ 2151931904 LnchCtrlEngRPMStat 10;
BA_ "SignalType" SG_ 2151931904 LnchCtrlEngRPMStat "ENM";
BA_ "SignalLongName" SG_ 2151931904 LnchCtrlEngRPMStat "Launch Control Engine RPM Status";
BA_ "VNSigAllNodes" SG_ 2151931904 LnchCtrlEngRPMStat 1;
BA_ "GenSigSendType" SG_ 2151931904 RegVltCtlEngyRcvryAct 10;
BA_ "SignalType" SG_ 2151931904 RegVltCtlEngyRcvryAct "BLN";
BA_ "SignalLongName" SG_ 2151931904 RegVltCtlEngyRcvryAct "Regulated Voltage Control Energy Recovery Active";
BA_ "VNSigAllNodes" SG_ 2151931904 RegVltCtlEngyRcvryAct 1;
BA_ "GenSigSendType" SG_ 2151931904 VehSpdCntlSystmType 10;
BA_ "SignalType" SG_ 2151931904 VehSpdCntlSystmType "ENM";
BA_ "SignalLongName" SG_ 2151931904 VehSpdCntlSystmType "Vehicle Speed Control System Type";
BA_ "VNSigAllNodes" SG_ 2151931904 VehSpdCntlSystmType 1;
BA_ "GenSigSendType" SG_ 2151931904 ACCSysSltdMdDispIO 10;
BA_ "SignalType" SG_ 2151931904 ACCSysSltdMdDispIO "BLN";
BA_ "SignalLongName" SG_ 2151931904 ACCSysSltdMdDispIO "Adaptive Cruise Control System Selected Mode Display Indication On";
BA_ "VNSigAllNodes" SG_ 2151931904 ACCSysSltdMdDispIO 1;
BA_ "GenSigSendType" SG_ 2151931904 ACCSysSltdMd 10;
BA_ "SignalType" SG_ 2151931904 ACCSysSltdMd "ENM";
BA_ "SignalLongName" SG_ 2151931904 ACCSysSltdMd "Adaptive Cruise Control System Selected Mode";
BA_ "VNSigAllNodes" SG_ 2151931904 ACCSysSltdMd 1;
BA_ "GenSigSendType" SG_ 2151931904 PTExPrtclFltWrng3IO 10;
BA_ "SignalType" SG_ 2151931904 PTExPrtclFltWrng3IO "BLN";
BA_ "SignalLongName" SG_ 2151931904 PTExPrtclFltWrng3IO "Powertrain Exhaust Particle Filter Warning 3 Indication On";
BA_ "VNSigAllNodes" SG_ 2151931904 PTExPrtclFltWrng3IO 1;
BA_ "GenSigSendType" SG_ 2151931904 PTExPartFltManRegStat 10;
BA_ "SignalType" SG_ 2151931904 PTExPartFltManRegStat "ENM";
BA_ "SignalLongName" SG_ 2151931904 PTExPartFltManRegStat "Powertrain Exhaust Particle Filter Manual Regeneration Status";
BA_ "VNSigAllNodes" SG_ 2151931904 PTExPartFltManRegStat 1;
BA_ "GenSigSendType" SG_ 2151931904 LnchCtrlWhlSlpStat 10;
BA_ "SignalType" SG_ 2151931904 LnchCtrlWhlSlpStat "ENM";
BA_ "SignalLongName" SG_ 2151931904 LnchCtrlWhlSlpStat "Launch Control Wheel Slip Status";
BA_ "VNSigAllNodes" SG_ 2151931904 LnchCtrlWhlSlpStat 1;
BA_ "GenSigSendType" SG_ 2151931904 LnchCtrlMdStat 10;
BA_ "SignalType" SG_ 2151931904 LnchCtrlMdStat "ENM";
BA_ "SignalLongName" SG_ 2151931904 LnchCtrlMdStat "Launch Control Mode Status";
BA_ "VNSigAllNodes" SG_ 2151931904 LnchCtrlMdStat 1;
BA_ "GenSigSendType" SG_ 2151931904 AWDRecmndIO 10;
BA_ "SignalType" SG_ 2151931904 AWDRecmndIO "BLN";
BA_ "SignalLongName" SG_ 2151931904 AWDRecmndIO "All Wheel Drive Recommended Indication On";
BA_ "VNSigAllNodes" SG_ 2151931904 AWDRecmndIO 1;
BA_ "GenSigDeltaValue" SG_ 2150244352 ECHGDDV_Col10 1;
BA_ "GenSigSendType" SG_ 2150244352 ECHGDDV_Col10 12;
BA_ "GenSigSendOnInit" SG_ 2150244352 ECHGDDV_Col10 1;
BA_ "PacketOrder" SG_ 2150244352 ECHGDDV_Col10 11;
BA_ "VNSigInfotainment" SG_ 2150244352 ECHGDDV_Col10 1;
BA_ "SignalType" SG_ 2150244352 ECHGDDV_Col10 "UNM";
BA_ "SignalLongName" SG_ 2150244352 ECHGDDV_Col10 "Energy Consumption History Graph Display Data Values : Column 10";
BA_ "VNSigAllNodes" SG_ 2150244352 ECHGDDV_Col10 1;
BA_ "GenSigDeltaValue" SG_ 2150244352 ECHGDDV_Col9 1;
BA_ "GenSigSendType" SG_ 2150244352 ECHGDDV_Col9 12;
BA_ "GenSigSendOnInit" SG_ 2150244352 ECHGDDV_Col9 1;
BA_ "PacketOrder" SG_ 2150244352 ECHGDDV_Col9 10;
BA_ "VNSigInfotainment" SG_ 2150244352 ECHGDDV_Col9 1;
BA_ "SignalType" SG_ 2150244352 ECHGDDV_Col9 "UNM";
BA_ "SignalLongName" SG_ 2150244352 ECHGDDV_Col9 "Energy Consumption History Graph Display Data Values : Column 09";
BA_ "VNSigAllNodes" SG_ 2150244352 ECHGDDV_Col9 1;
BA_ "GenSigDeltaValue" SG_ 2150244352 ECHGDDV_Col8 1;
BA_ "GenSigSendType" SG_ 2150244352 ECHGDDV_Col8 12;
BA_ "GenSigSendOnInit" SG_ 2150244352 ECHGDDV_Col8 1;
BA_ "PacketOrder" SG_ 2150244352 ECHGDDV_Col8 9;
BA_ "VNSigInfotainment" SG_ 2150244352 ECHGDDV_Col8 1;
BA_ "SignalType" SG_ 2150244352 ECHGDDV_Col8 "UNM";
BA_ "SignalLongName" SG_ 2150244352 ECHGDDV_Col8 "Energy Consumption History Graph Display Data Values : Column 08";
BA_ "VNSigAllNodes" SG_ 2150244352 ECHGDDV_Col8 1;
BA_ "GenSigDeltaValue" SG_ 2150244352 ECHGDDV_Col7 1;
BA_ "GenSigSendType" SG_ 2150244352 ECHGDDV_Col7 12;
BA_ "GenSigSendOnInit" SG_ 2150244352 ECHGDDV_Col7 1;
BA_ "PacketOrder" SG_ 2150244352 ECHGDDV_Col7 8;
BA_ "VNSigInfotainment" SG_ 2150244352 ECHGDDV_Col7 1;
BA_ "SignalType" SG_ 2150244352 ECHGDDV_Col7 "UNM";
BA_ "SignalLongName" SG_ 2150244352 ECHGDDV_Col7 "Energy Consumption History Graph Display Data Values : Column 07";
BA_ "VNSigAllNodes" SG_ 2150244352 ECHGDDV_Col7 1;
BA_ "GenSigDeltaValue" SG_ 2150244352 ECHGDDV_Col6 1;
BA_ "GenSigSendType" SG_ 2150244352 ECHGDDV_Col6 12;
BA_ "GenSigSendOnInit" SG_ 2150244352 ECHGDDV_Col6 1;
BA_ "PacketOrder" SG_ 2150244352 ECHGDDV_Col6 7;
BA_ "VNSigInfotainment" SG_ 2150244352 ECHGDDV_Col6 1;
BA_ "SignalType" SG_ 2150244352 ECHGDDV_Col6 "UNM";
BA_ "SignalLongName" SG_ 2150244352 ECHGDDV_Col6 "Energy Consumption History Graph Display Data Values : Column 06";
BA_ "VNSigAllNodes" SG_ 2150244352 ECHGDDV_Col6 1;
BA_ "GenSigDeltaValue" SG_ 2150244352 ECHGDDV_Col5 1;
BA_ "GenSigSendType" SG_ 2150244352 ECHGDDV_Col5 12;
BA_ "GenSigSendOnInit" SG_ 2150244352 ECHGDDV_Col5 1;
BA_ "PacketOrder" SG_ 2150244352 ECHGDDV_Col5 6;
BA_ "VNSigInfotainment" SG_ 2150244352 ECHGDDV_Col5 1;
BA_ "SignalType" SG_ 2150244352 ECHGDDV_Col5 "UNM";
BA_ "SignalLongName" SG_ 2150244352 ECHGDDV_Col5 "Energy Consumption History Graph Display Data Values : Column 05";
BA_ "VNSigAllNodes" SG_ 2150244352 ECHGDDV_Col5 1;
BA_ "GenSigDeltaValue" SG_ 2150244352 ECHGDDV_Col4 1;
BA_ "GenSigSendType" SG_ 2150244352 ECHGDDV_Col4 12;
BA_ "GenSigSendOnInit" SG_ 2150244352 ECHGDDV_Col4 1;
BA_ "PacketOrder" SG_ 2150244352 ECHGDDV_Col4 5;
BA_ "VNSigInfotainment" SG_ 2150244352 ECHGDDV_Col4 1;
BA_ "SignalType" SG_ 2150244352 ECHGDDV_Col4 "UNM";
BA_ "SignalLongName" SG_ 2150244352 ECHGDDV_Col4 "Energy Consumption History Graph Display Data Values : Column 04";
BA_ "VNSigAllNodes" SG_ 2150244352 ECHGDDV_Col4 1;
BA_ "GenSigDeltaValue" SG_ 2150244352 ECHGDDV_Col3 1;
BA_ "GenSigSendType" SG_ 2150244352 ECHGDDV_Col3 12;
BA_ "GenSigSendOnInit" SG_ 2150244352 ECHGDDV_Col3 1;
BA_ "PacketOrder" SG_ 2150244352 ECHGDDV_Col3 4;
BA_ "VNSigInfotainment" SG_ 2150244352 ECHGDDV_Col3 1;
BA_ "SignalType" SG_ 2150244352 ECHGDDV_Col3 "UNM";
BA_ "SignalLongName" SG_ 2150244352 ECHGDDV_Col3 "Energy Consumption History Graph Display Data Values : Column 03";
BA_ "VNSigAllNodes" SG_ 2150244352 ECHGDDV_Col3 1;
BA_ "GenSigDeltaValue" SG_ 2150244352 ECHGDDV_Col2 1;
BA_ "GenSigSendType" SG_ 2150244352 ECHGDDV_Col2 12;
BA_ "GenSigSendOnInit" SG_ 2150244352 ECHGDDV_Col2 1;
BA_ "PacketOrder" SG_ 2150244352 ECHGDDV_Col2 3;
BA_ "VNSigInfotainment" SG_ 2150244352 ECHGDDV_Col2 1;
BA_ "SignalType" SG_ 2150244352 ECHGDDV_Col2 "UNM";
BA_ "SignalLongName" SG_ 2150244352 ECHGDDV_Col2 "Energy Consumption History Graph Display Data Values : Column 02";
BA_ "VNSigAllNodes" SG_ 2150244352 ECHGDDV_Col2 1;
BA_ "GenSigDeltaValue" SG_ 2150244352 ECHGDDV_Col1 1;
BA_ "GenSigSendType" SG_ 2150244352 ECHGDDV_Col1 12;
BA_ "GenSigSendOnInit" SG_ 2150244352 ECHGDDV_Col1 1;
BA_ "PacketOrder" SG_ 2150244352 ECHGDDV_Col1 2;
BA_ "VNSigInfotainment" SG_ 2150244352 ECHGDDV_Col1 1;
BA_ "SignalType" SG_ 2150244352 ECHGDDV_Col1 "UNM";
BA_ "SignalLongName" SG_ 2150244352 ECHGDDV_Col1 "Energy Consumption History Graph Display Data Values : Column 01";
BA_ "VNSigAllNodes" SG_ 2150244352 ECHGDDV_Col1 1;
BA_ "GenSigDeltaValue" SG_ 2150244352 ECHGDDV_EngyConsAvg 1;
BA_ "GenSigSendType" SG_ 2150244352 ECHGDDV_EngyConsAvg 12;
BA_ "GenSigSendOnInit" SG_ 2150244352 ECHGDDV_EngyConsAvg 1;
BA_ "PacketOrder" SG_ 2150244352 ECHGDDV_EngyConsAvg 1;
BA_ "VNSigInfotainment" SG_ 2150244352 ECHGDDV_EngyConsAvg 1;
BA_ "SignalType" SG_ 2150244352 ECHGDDV_EngyConsAvg "UNM";
BA_ "SignalLongName" SG_ 2150244352 ECHGDDV_EngyConsAvg "Energy Consumption History Graph Display Data Values : Energy Consumed Average";
BA_ "VNSigAllNodes" SG_ 2150244352 ECHGDDV_EngyConsAvg 1;
BA_ "GenSigSendType" SG_ 2156953600 WiFiSSIDDgts9to16_Mp 10;
BA_ "GenSigSendOnInit" SG_ 2156953600 WiFiSSIDDgts9to16_Mp 2;
BA_ "SignalType" SG_ 2156953600 WiFiSSIDDgts9to16_Mp "ASC";
BA_ "SignalLongName" SG_ 2156953600 WiFiSSIDDgts9to16_Mp "WiFi Service Set Identifier Digits 9 to 16 Map";
BA_ "VNSigAllNodes" SG_ 2156953600 WiFiSSIDDgts9to16_Mp 1;
BA_ "SignalType" SG_ 1363 DgnInf_LS553 "UNM";
BA_ "SignalLongName" SG_ 1363 DgnInf_LS553 "Diagnostic Information LS553";
BA_ "VNSigDiagnostic" SG_ 1363 DgnInf_LS553 1;
BA_ "VNSigAllNodes" SG_ 1363 DgnInf_LS553 1;
BA_ "SignalType" SG_ 1619 DgnInf "UNM";
BA_ "SignalLongName" SG_ 1619 DgnInf "Diagnostic Information";
BA_ "VNSigDiagnostic" SG_ 1619 DgnInf 1;
BA_ "VNSigAllNodes" SG_ 1619 DgnInf 1;
BA_ "SignalType" SG_ 597 DgnInf "UNM";
BA_ "SignalLongName" SG_ 597 DgnInf "Diagnostic Information";
BA_ "VNSigDiagnostic" SG_ 597 DgnInf 1;
BA_ "VNSigAllNodes" SG_ 597 DgnInf 1;
BA_ "SignalType" SG_ 2020 DgnInf "UNM";
BA_ "SignalLongName" SG_ 2020 DgnInf "Diagnostic Information";
BA_ "VNSigDiagnostic" SG_ 2020 DgnInf 1;
BA_ "VNSigAllNodes" SG_ 2020 DgnInf 1;
BA_ "SignalType" SG_ 601 DgnInf "UNM";
BA_ "SignalLongName" SG_ 601 DgnInf "Diagnostic Information";
BA_ "VNSigDiagnostic" SG_ 601 DgnInf 1;
BA_ "VNSigAllNodes" SG_ 601 DgnInf 1;
BA_ "SignalType" SG_ 583 DgnInf "UNM";
BA_ "SignalLongName" SG_ 583 DgnInf "Diagnostic Information";
BA_ "VNSigDiagnostic" SG_ 583 DgnInf 1;
BA_ "VNSigAllNodes" SG_ 583 DgnInf 1;
BA_ "SignalType" SG_ 604 DgnInf "UNM";
BA_ "SignalLongName" SG_ 604 DgnInf "Diagnostic Information";
BA_ "VNSigDiagnostic" SG_ 604 DgnInf 1;
BA_ "VNSigAllNodes" SG_ 604 DgnInf 1;
BA_ "SignalType" SG_ 599 DgnInf "UNM";
BA_ "SignalLongName" SG_ 599 DgnInf "Diagnostic Information";
BA_ "VNSigDiagnostic" SG_ 599 DgnInf 1;
BA_ "VNSigAllNodes" SG_ 599 DgnInf 1;
BA_ "SignalType" SG_ 602 DgnInf "UNM";
BA_ "SignalLongName" SG_ 602 DgnInf "Diagnostic Information";
BA_ "VNSigDiagnostic" SG_ 602 DgnInf 1;
BA_ "VNSigAllNodes" SG_ 602 DgnInf 1;
BA_ "SignalType" SG_ 591 DgnInf "UNM";
BA_ "SignalLongName" SG_ 591 DgnInf "Diagnostic Information";
BA_ "VNSigDiagnostic" SG_ 591 DgnInf 1;
BA_ "VNSigAllNodes" SG_ 591 DgnInf 1;
BA_ "SignalType" SG_ 578 DgnInf "UNM";
BA_ "SignalLongName" SG_ 578 DgnInf "Diagnostic Information";
BA_ "VNSigDiagnostic" SG_ 578 DgnInf 1;
BA_ "VNSigAllNodes" SG_ 578 DgnInf 1;
BA_ "SignalType" SG_ 600 DgnInf "UNM";
BA_ "SignalLongName" SG_ 600 DgnInf "Diagnostic Information";
BA_ "VNSigDiagnostic" SG_ 600 DgnInf 1;
BA_ "VNSigAllNodes" SG_ 600 DgnInf 1;
BA_ "SignalType" SG_ 607 DgnInf "UNM";
BA_ "SignalLongName" SG_ 607 DgnInf "Diagnostic Information";
BA_ "VNSigDiagnostic" SG_ 607 DgnInf 1;
BA_ "VNSigAllNodes" SG_ 607 DgnInf 1;
BA_ "SignalType" SG_ 587 DgnInf "UNM";
BA_ "SignalLongName" SG_ 587 DgnInf "Diagnostic Information";
BA_ "VNSigDiagnostic" SG_ 587 DgnInf 1;
BA_ "VNSigAllNodes" SG_ 587 DgnInf 1;
BA_ "SignalType" SG_ 593 DgnInf "UNM";
BA_ "SignalLongName" SG_ 593 DgnInf "Diagnostic Information";
BA_ "VNSigDiagnostic" SG_ 593 DgnInf 1;
BA_ "VNSigAllNodes" SG_ 593 DgnInf 1;
BA_ "SignalType" SG_ 605 DgnInf "UNM";
BA_ "SignalLongName" SG_ 605 DgnInf "Diagnostic Information";
BA_ "VNSigDiagnostic" SG_ 605 DgnInf 1;
BA_ "VNSigAllNodes" SG_ 605 DgnInf 1;
BA_ "SignalType" SG_ 577 DgnInf "UNM";
BA_ "SignalLongName" SG_ 577 DgnInf "Diagnostic Information";
BA_ "VNSigDiagnostic" SG_ 577 DgnInf 1;
BA_ "VNSigAllNodes" SG_ 577 DgnInf 1;
BA_ "SignalType" SG_ 603 DgnInf "UNM";
BA_ "SignalLongName" SG_ 603 DgnInf "Diagnostic Information";
BA_ "VNSigDiagnostic" SG_ 603 DgnInf 1;
BA_ "VNSigAllNodes" SG_ 603 DgnInf 1;
BA_ "SignalType" SG_ 581 DgnInf "UNM";
BA_ "SignalLongName" SG_ 581 DgnInf "Diagnostic Information";
BA_ "VNSigDiagnostic" SG_ 581 DgnInf 1;
BA_ "VNSigAllNodes" SG_ 581 DgnInf 1;
BA_ "SignalType" SG_ 606 DgnInf "UNM";
BA_ "SignalLongName" SG_ 606 DgnInf "Diagnostic Information";
BA_ "VNSigDiagnostic" SG_ 606 DgnInf 1;
BA_ "VNSigAllNodes" SG_ 606 DgnInf 1;
BA_ "SignalType" SG_ 579 DgnInf "UNM";
BA_ "SignalLongName" SG_ 579 DgnInf "Diagnostic Information";
BA_ "VNSigDiagnostic" SG_ 579 DgnInf 1;
BA_ "VNSigAllNodes" SG_ 579 DgnInf 1;
BA_ "SignalType" SG_ 1621 DgnInf "UNM";
BA_ "SignalLongName" SG_ 1621 DgnInf "Diagnostic Information";
BA_ "VNSigDiagnostic" SG_ 1621 DgnInf 1;
BA_ "VNSigAllNodes" SG_ 1621 DgnInf 1;
BA_ "SignalType" SG_ 2028 DgnInf "UNM";
BA_ "SignalLongName" SG_ 2028 DgnInf "Diagnostic Information";
BA_ "VNSigDiagnostic" SG_ 2028 DgnInf 1;
BA_ "VNSigAllNodes" SG_ 2028 DgnInf 1;
BA_ "SignalType" SG_ 1625 DgnInf "UNM";
BA_ "SignalLongName" SG_ 1625 DgnInf "Diagnostic Information";
BA_ "VNSigDiagnostic" SG_ 1625 DgnInf 1;
BA_ "VNSigAllNodes" SG_ 1625 DgnInf 1;
BA_ "SignalType" SG_ 1607 DgnInf "UNM";
BA_ "SignalLongName" SG_ 1607 DgnInf "Diagnostic Information";
BA_ "VNSigDiagnostic" SG_ 1607 DgnInf 1;
BA_ "VNSigAllNodes" SG_ 1607 DgnInf 1;
BA_ "SignalType" SG_ 1628 DgnInf "UNM";
BA_ "SignalLongName" SG_ 1628 DgnInf "Diagnostic Information";
BA_ "VNSigDiagnostic" SG_ 1628 DgnInf 1;
BA_ "VNSigAllNodes" SG_ 1628 DgnInf 1;
BA_ "SignalType" SG_ 1623 DgnInf "UNM";
BA_ "SignalLongName" SG_ 1623 DgnInf "Diagnostic Information";
BA_ "VNSigDiagnostic" SG_ 1623 DgnInf 1;
BA_ "VNSigAllNodes" SG_ 1623 DgnInf 1;
BA_ "SignalType" SG_ 1626 DgnInf "UNM";
BA_ "SignalLongName" SG_ 1626 DgnInf "Diagnostic Information";
BA_ "VNSigDiagnostic" SG_ 1626 DgnInf 1;
BA_ "VNSigAllNodes" SG_ 1626 DgnInf 1;
BA_ "SignalType" SG_ 1615 DgnInf "UNM";
BA_ "SignalLongName" SG_ 1615 DgnInf "Diagnostic Information";
BA_ "VNSigDiagnostic" SG_ 1615 DgnInf 1;
BA_ "VNSigAllNodes" SG_ 1615 DgnInf 1;
BA_ "SignalType" SG_ 1602 DgnInf "UNM";
BA_ "SignalLongName" SG_ 1602 DgnInf "Diagnostic Information";
BA_ "VNSigDiagnostic" SG_ 1602 DgnInf 1;
BA_ "VNSigAllNodes" SG_ 1602 DgnInf 1;
BA_ "SignalType" SG_ 1624 DgnInf "UNM";
BA_ "SignalLongName" SG_ 1624 DgnInf "Diagnostic Information";
BA_ "VNSigDiagnostic" SG_ 1624 DgnInf 1;
BA_ "VNSigAllNodes" SG_ 1624 DgnInf 1;
BA_ "SignalType" SG_ 1631 DgnInf "UNM";
BA_ "SignalLongName" SG_ 1631 DgnInf "Diagnostic Information";
BA_ "VNSigDiagnostic" SG_ 1631 DgnInf 1;
BA_ "VNSigAllNodes" SG_ 1631 DgnInf 1;
BA_ "SignalType" SG_ 1611 DgnInf "UNM";
BA_ "SignalLongName" SG_ 1611 DgnInf "Diagnostic Information";
BA_ "VNSigDiagnostic" SG_ 1611 DgnInf 1;
BA_ "VNSigAllNodes" SG_ 1611 DgnInf 1;
BA_ "SignalType" SG_ 1617 DgnInf "UNM";
BA_ "SignalLongName" SG_ 1617 DgnInf "Diagnostic Information";
BA_ "VNSigDiagnostic" SG_ 1617 DgnInf 1;
BA_ "VNSigAllNodes" SG_ 1617 DgnInf 1;
BA_ "SignalType" SG_ 1629 DgnInf "UNM";
BA_ "SignalLongName" SG_ 1629 DgnInf "Diagnostic Information";
BA_ "VNSigDiagnostic" SG_ 1629 DgnInf 1;
BA_ "VNSigAllNodes" SG_ 1629 DgnInf 1;
BA_ "SignalType" SG_ 1601 DgnInf "UNM";
BA_ "SignalLongName" SG_ 1601 DgnInf "Diagnostic Information";
BA_ "VNSigDiagnostic" SG_ 1601 DgnInf 1;
BA_ "VNSigAllNodes" SG_ 1601 DgnInf 1;
BA_ "SignalType" SG_ 1627 DgnInf "UNM";
BA_ "SignalLongName" SG_ 1627 DgnInf "Diagnostic Information";
BA_ "VNSigDiagnostic" SG_ 1627 DgnInf 1;
BA_ "VNSigAllNodes" SG_ 1627 DgnInf 1;
BA_ "SignalType" SG_ 1605 DgnInf "UNM";
BA_ "SignalLongName" SG_ 1605 DgnInf "Diagnostic Information";
BA_ "VNSigDiagnostic" SG_ 1605 DgnInf 1;
BA_ "VNSigAllNodes" SG_ 1605 DgnInf 1;
BA_ "SignalType" SG_ 1630 DgnInf "UNM";
BA_ "SignalLongName" SG_ 1630 DgnInf "Diagnostic Information";
BA_ "VNSigDiagnostic" SG_ 1630 DgnInf 1;
BA_ "VNSigAllNodes" SG_ 1630 DgnInf 1;
BA_ "SignalType" SG_ 1603 DgnInf "UNM";
BA_ "SignalLongName" SG_ 1603 DgnInf "Diagnostic Information";
BA_ "VNSigDiagnostic" SG_ 1603 DgnInf 1;
BA_ "VNSigAllNodes" SG_ 1603 DgnInf 1;
BA_ "SignalType" SG_ 1365 DgnInf_LS555 "UNM";
BA_ "SignalLongName" SG_ 1365 DgnInf_LS555 "Diagnostic Information LS555";
BA_ "VNSigDiagnostic" SG_ 1365 DgnInf_LS555 1;
BA_ "VNSigAllNodes" SG_ 1365 DgnInf_LS555 1;
BA_ "SignalType" SG_ 1516 DgnInf_LS5EC "UNM";
BA_ "SignalLongName" SG_ 1516 DgnInf_LS5EC "Diagnostic Information LS5EC";
BA_ "VNSigDiagnostic" SG_ 1516 DgnInf_LS5EC 1;
BA_ "VNSigAllNodes" SG_ 1516 DgnInf_LS5EC 1;
BA_ "SignalType" SG_ 1369 DgnInf_LS559 "UNM";
BA_ "SignalLongName" SG_ 1369 DgnInf_LS559 "Diagnostic Information LS559";
BA_ "VNSigDiagnostic" SG_ 1369 DgnInf_LS559 1;
BA_ "VNSigAllNodes" SG_ 1369 DgnInf_LS559 1;
BA_ "SignalType" SG_ 1351 DgnInf_LS547 "UNM";
BA_ "SignalLongName" SG_ 1351 DgnInf_LS547 "Diagnostic Information LS547";
BA_ "VNSigDiagnostic" SG_ 1351 DgnInf_LS547 1;
BA_ "VNSigAllNodes" SG_ 1351 DgnInf_LS547 1;
BA_ "SignalType" SG_ 1372 DgnInf_LS55C "UNM";
BA_ "SignalLongName" SG_ 1372 DgnInf_LS55C "Diagnostic Information LS55C";
BA_ "VNSigDiagnostic" SG_ 1372 DgnInf_LS55C 1;
BA_ "VNSigAllNodes" SG_ 1372 DgnInf_LS55C 1;
BA_ "SignalType" SG_ 1367 DgnInf_LS557 "UNM";
BA_ "SignalLongName" SG_ 1367 DgnInf_LS557 "Diagnostic Information LS557";
BA_ "VNSigDiagnostic" SG_ 1367 DgnInf_LS557 1;
BA_ "VNSigAllNodes" SG_ 1367 DgnInf_LS557 1;
BA_ "SignalType" SG_ 1370 DgnInf_LS55A "UNM";
BA_ "SignalLongName" SG_ 1370 DgnInf_LS55A "Diagnostic Information LS55A";
BA_ "VNSigDiagnostic" SG_ 1370 DgnInf_LS55A 1;
BA_ "VNSigAllNodes" SG_ 1370 DgnInf_LS55A 1;
BA_ "SignalType" SG_ 1359 DgnInf_LS54F "UNM";
BA_ "SignalLongName" SG_ 1359 DgnInf_LS54F "Diagnostic Information LS54F";
BA_ "VNSigDiagnostic" SG_ 1359 DgnInf_LS54F 1;
BA_ "VNSigAllNodes" SG_ 1359 DgnInf_LS54F 1;
BA_ "SignalType" SG_ 1346 DgnInf_LS542 "UNM";
BA_ "SignalLongName" SG_ 1346 DgnInf_LS542 "Diagnostic Information LS542";
BA_ "VNSigDiagnostic" SG_ 1346 DgnInf_LS542 1;
BA_ "VNSigAllNodes" SG_ 1346 DgnInf_LS542 1;
BA_ "SignalType" SG_ 1368 DgnInf_LS558 "UNM";
BA_ "SignalLongName" SG_ 1368 DgnInf_LS558 "Diagnostic Information LS558";
BA_ "VNSigDiagnostic" SG_ 1368 DgnInf_LS558 1;
BA_ "VNSigAllNodes" SG_ 1368 DgnInf_LS558 1;
BA_ "SignalType" SG_ 1375 DgnInf_LS55F "UNM";
BA_ "SignalLongName" SG_ 1375 DgnInf_LS55F "Diagnostic Information LS55F";
BA_ "VNSigDiagnostic" SG_ 1375 DgnInf_LS55F 1;
BA_ "VNSigAllNodes" SG_ 1375 DgnInf_LS55F 1;
BA_ "SignalType" SG_ 1355 DgnInf_LS54B "UNM";
BA_ "SignalLongName" SG_ 1355 DgnInf_LS54B "Diagnostic Information LS54B";
BA_ "VNSigDiagnostic" SG_ 1355 DgnInf_LS54B 1;
BA_ "VNSigAllNodes" SG_ 1355 DgnInf_LS54B 1;
BA_ "SignalType" SG_ 1361 DgnInf_LS551 "UNM";
BA_ "SignalLongName" SG_ 1361 DgnInf_LS551 "Diagnostic Information LS551";
BA_ "VNSigDiagnostic" SG_ 1361 DgnInf_LS551 1;
BA_ "VNSigAllNodes" SG_ 1361 DgnInf_LS551 1;
BA_ "SignalType" SG_ 1373 DgnInf_LS55D "UNM";
BA_ "SignalLongName" SG_ 1373 DgnInf_LS55D "Diagnostic Information LS55D";
BA_ "VNSigDiagnostic" SG_ 1373 DgnInf_LS55D 1;
BA_ "VNSigAllNodes" SG_ 1373 DgnInf_LS55D 1;
BA_ "SignalType" SG_ 1345 DgnInf_LS541 "UNM";
BA_ "SignalLongName" SG_ 1345 DgnInf_LS541 "Diagnostic Information LS541";
BA_ "VNSigDiagnostic" SG_ 1345 DgnInf_LS541 1;
BA_ "VNSigAllNodes" SG_ 1345 DgnInf_LS541 1;
BA_ "SignalType" SG_ 1371 DgnInf_LS55B "UNM";
BA_ "SignalLongName" SG_ 1371 DgnInf_LS55B "Diagnostic Information LS55B";
BA_ "VNSigDiagnostic" SG_ 1371 DgnInf_LS55B 1;
BA_ "VNSigAllNodes" SG_ 1371 DgnInf_LS55B 1;
BA_ "SignalType" SG_ 1349 DgnInf_LS545 "UNM";
BA_ "SignalLongName" SG_ 1349 DgnInf_LS545 "Diagnostic Information LS545";
BA_ "VNSigDiagnostic" SG_ 1349 DgnInf_LS545 1;
BA_ "VNSigAllNodes" SG_ 1349 DgnInf_LS545 1;
BA_ "SignalType" SG_ 1374 DgnInf_LS55E "UNM";
BA_ "SignalLongName" SG_ 1374 DgnInf_LS55E "Diagnostic Information LS55E";
BA_ "VNSigDiagnostic" SG_ 1374 DgnInf_LS55E 1;
BA_ "VNSigAllNodes" SG_ 1374 DgnInf_LS55E 1;
BA_ "SignalType" SG_ 1347 DgnInf_LS543 "UNM";
BA_ "SignalLongName" SG_ 1347 DgnInf_LS543 "Diagnostic Information LS543";
BA_ "VNSigDiagnostic" SG_ 1347 DgnInf_LS543 1;
BA_ "VNSigAllNodes" SG_ 1347 DgnInf_LS543 1;
BA_ "VNSigPrimaryTriggering" SG_ 1599 VectraSpcNWMgtD 1;
BA_ "VNSigRemoteDiagnostics" SG_ 1599 VectraSpcNWMgtD 1;
BA_ "VNSigInfotainment" SG_ 1599 VectraSpcNWMgtD 1;
BA_ "VNSigParkedVehicle" SG_ 1599 VectraSpcNWMgtD 1;
BA_ "VNSigIntermediate" SG_ 1599 VectraSpcNWMgtD 1;
BA_ "VNSigUnused_4" SG_ 1599 VectraSpcNWMgtD 1;
BA_ "SignalType" SG_ 1599 VectraSpcNWMgtD "UNM";
BA_ "SignalLongName" SG_ 1599 VectraSpcNWMgtD "Vectra Specific Network Management Data";
BA_ "VNSigDiagnostic" SG_ 1599 VectraSpcNWMgtD 1;
BA_ "VNSigAllNodes" SG_ 1599 VectraSpcNWMgtD 1;
BA_ "VNSigPrimaryTriggering" SG_ 1598 VectraSpcNWMgtD 1;
BA_ "VNSigRemoteDiagnostics" SG_ 1598 VectraSpcNWMgtD 1;
BA_ "VNSigInfotainment" SG_ 1598 VectraSpcNWMgtD 1;
BA_ "VNSigParkedVehicle" SG_ 1598 VectraSpcNWMgtD 1;
BA_ "VNSigIntermediate" SG_ 1598 VectraSpcNWMgtD 1;
BA_ "VNSigUnused_4" SG_ 1598 VectraSpcNWMgtD 1;
BA_ "SignalType" SG_ 1598 VectraSpcNWMgtD "UNM";
BA_ "SignalLongName" SG_ 1598 VectraSpcNWMgtD "Vectra Specific Network Management Data";
BA_ "VNSigDiagnostic" SG_ 1598 VectraSpcNWMgtD 1;
BA_ "VNSigAllNodes" SG_ 1598 VectraSpcNWMgtD 1;
BA_ "VNSigPrimaryTriggering" SG_ 1597 VectraSpcNWMgtD 1;
BA_ "VNSigRemoteDiagnostics" SG_ 1597 VectraSpcNWMgtD 1;
BA_ "VNSigInfotainment" SG_ 1597 VectraSpcNWMgtD 1;
BA_ "VNSigParkedVehicle" SG_ 1597 VectraSpcNWMgtD 1;
BA_ "VNSigIntermediate" SG_ 1597 VectraSpcNWMgtD 1;
BA_ "VNSigUnused_4" SG_ 1597 VectraSpcNWMgtD 1;
BA_ "SignalType" SG_ 1597 VectraSpcNWMgtD "UNM";
BA_ "SignalLongName" SG_ 1597 VectraSpcNWMgtD "Vectra Specific Network Management Data";
BA_ "VNSigDiagnostic" SG_ 1597 VectraSpcNWMgtD 1;
BA_ "VNSigAllNodes" SG_ 1597 VectraSpcNWMgtD 1;
BA_ "VNSigPrimaryTriggering" SG_ 1596 VectraSpcNWMgtD 1;
BA_ "VNSigRemoteDiagnostics" SG_ 1596 VectraSpcNWMgtD 1;
BA_ "VNSigInfotainment" SG_ 1596 VectraSpcNWMgtD 1;
BA_ "VNSigParkedVehicle" SG_ 1596 VectraSpcNWMgtD 1;
BA_ "VNSigIntermediate" SG_ 1596 VectraSpcNWMgtD 1;
BA_ "VNSigUnused_4" SG_ 1596 VectraSpcNWMgtD 1;
BA_ "SignalType" SG_ 1596 VectraSpcNWMgtD "UNM";
BA_ "SignalLongName" SG_ 1596 VectraSpcNWMgtD "Vectra Specific Network Management Data";
BA_ "VNSigDiagnostic" SG_ 1596 VectraSpcNWMgtD 1;
BA_ "VNSigAllNodes" SG_ 1596 VectraSpcNWMgtD 1;
BA_ "VNSigPrimaryTriggering" SG_ 1595 VectraSpcNWMgtD 1;
BA_ "VNSigRemoteDiagnostics" SG_ 1595 VectraSpcNWMgtD 1;
BA_ "VNSigInfotainment" SG_ 1595 VectraSpcNWMgtD 1;
BA_ "VNSigParkedVehicle" SG_ 1595 VectraSpcNWMgtD 1;
BA_ "VNSigIntermediate" SG_ 1595 VectraSpcNWMgtD 1;
BA_ "VNSigUnused_4" SG_ 1595 VectraSpcNWMgtD 1;
BA_ "SignalType" SG_ 1595 VectraSpcNWMgtD "UNM";
BA_ "SignalLongName" SG_ 1595 VectraSpcNWMgtD "Vectra Specific Network Management Data";
BA_ "VNSigDiagnostic" SG_ 1595 VectraSpcNWMgtD 1;
BA_ "VNSigAllNodes" SG_ 1595 VectraSpcNWMgtD 1;
BA_ "VNSigPrimaryTriggering" SG_ 1594 VectraSpcNWMgtD 1;
BA_ "VNSigRemoteDiagnostics" SG_ 1594 VectraSpcNWMgtD 1;
BA_ "VNSigInfotainment" SG_ 1594 VectraSpcNWMgtD 1;
BA_ "VNSigParkedVehicle" SG_ 1594 VectraSpcNWMgtD 1;
BA_ "VNSigIntermediate" SG_ 1594 VectraSpcNWMgtD 1;
BA_ "VNSigUnused_4" SG_ 1594 VectraSpcNWMgtD 1;
BA_ "SignalType" SG_ 1594 VectraSpcNWMgtD "UNM";
BA_ "SignalLongName" SG_ 1594 VectraSpcNWMgtD "Vectra Specific Network Management Data";
BA_ "VNSigDiagnostic" SG_ 1594 VectraSpcNWMgtD 1;
BA_ "VNSigAllNodes" SG_ 1594 VectraSpcNWMgtD 1;
BA_ "VNSigPrimaryTriggering" SG_ 1593 VectraSpcNWMgtD 1;
BA_ "VNSigRemoteDiagnostics" SG_ 1593 VectraSpcNWMgtD 1;
BA_ "VNSigInfotainment" SG_ 1593 VectraSpcNWMgtD 1;
BA_ "VNSigParkedVehicle" SG_ 1593 VectraSpcNWMgtD 1;
BA_ "VNSigIntermediate" SG_ 1593 VectraSpcNWMgtD 1;
BA_ "VNSigUnused_4" SG_ 1593 VectraSpcNWMgtD 1;
BA_ "SignalType" SG_ 1593 VectraSpcNWMgtD "UNM";
BA_ "SignalLongName" SG_ 1593 VectraSpcNWMgtD "Vectra Specific Network Management Data";
BA_ "VNSigDiagnostic" SG_ 1593 VectraSpcNWMgtD 1;
BA_ "VNSigAllNodes" SG_ 1593 VectraSpcNWMgtD 1;
BA_ "VNSigPrimaryTriggering" SG_ 1592 VectraSpcNWMgtD 1;
BA_ "VNSigRemoteDiagnostics" SG_ 1592 VectraSpcNWMgtD 1;
BA_ "VNSigInfotainment" SG_ 1592 VectraSpcNWMgtD 1;
BA_ "VNSigParkedVehicle" SG_ 1592 VectraSpcNWMgtD 1;
BA_ "VNSigIntermediate" SG_ 1592 VectraSpcNWMgtD 1;
BA_ "VNSigUnused_4" SG_ 1592 VectraSpcNWMgtD 1;
BA_ "SignalType" SG_ 1592 VectraSpcNWMgtD "UNM";
BA_ "SignalLongName" SG_ 1592 VectraSpcNWMgtD "Vectra Specific Network Management Data";
BA_ "VNSigDiagnostic" SG_ 1592 VectraSpcNWMgtD 1;
BA_ "VNSigAllNodes" SG_ 1592 VectraSpcNWMgtD 1;
BA_ "VNSigPrimaryTriggering" SG_ 1591 VectraSpcNWMgtD 1;
BA_ "VNSigRemoteDiagnostics" SG_ 1591 VectraSpcNWMgtD 1;
BA_ "VNSigInfotainment" SG_ 1591 VectraSpcNWMgtD 1;
BA_ "VNSigParkedVehicle" SG_ 1591 VectraSpcNWMgtD 1;
BA_ "VNSigIntermediate" SG_ 1591 VectraSpcNWMgtD 1;
BA_ "VNSigUnused_4" SG_ 1591 VectraSpcNWMgtD 1;
BA_ "SignalType" SG_ 1591 VectraSpcNWMgtD "UNM";
BA_ "SignalLongName" SG_ 1591 VectraSpcNWMgtD "Vectra Specific Network Management Data";
BA_ "VNSigDiagnostic" SG_ 1591 VectraSpcNWMgtD 1;
BA_ "VNSigAllNodes" SG_ 1591 VectraSpcNWMgtD 1;
BA_ "VNSigPrimaryTriggering" SG_ 1589 VectraSpcNWMgtD 1;
BA_ "VNSigRemoteDiagnostics" SG_ 1589 VectraSpcNWMgtD 1;
BA_ "VNSigInfotainment" SG_ 1589 VectraSpcNWMgtD 1;
BA_ "VNSigParkedVehicle" SG_ 1589 VectraSpcNWMgtD 1;
BA_ "VNSigIntermediate" SG_ 1589 VectraSpcNWMgtD 1;
BA_ "VNSigUnused_4" SG_ 1589 VectraSpcNWMgtD 1;
BA_ "SignalType" SG_ 1589 VectraSpcNWMgtD "UNM";
BA_ "SignalLongName" SG_ 1589 VectraSpcNWMgtD "Vectra Specific Network Management Data";
BA_ "VNSigDiagnostic" SG_ 1589 VectraSpcNWMgtD 1;
BA_ "VNSigAllNodes" SG_ 1589 VectraSpcNWMgtD 1;
BA_ "VNSigPrimaryTriggering" SG_ 1587 VectraSpcNWMgtD 1;
BA_ "VNSigRemoteDiagnostics" SG_ 1587 VectraSpcNWMgtD 1;
BA_ "VNSigInfotainment" SG_ 1587 VectraSpcNWMgtD 1;
BA_ "VNSigParkedVehicle" SG_ 1587 VectraSpcNWMgtD 1;
BA_ "VNSigIntermediate" SG_ 1587 VectraSpcNWMgtD 1;
BA_ "VNSigUnused_4" SG_ 1587 VectraSpcNWMgtD 1;
BA_ "SignalType" SG_ 1587 VectraSpcNWMgtD "UNM";
BA_ "SignalLongName" SG_ 1587 VectraSpcNWMgtD "Vectra Specific Network Management Data";
BA_ "VNSigDiagnostic" SG_ 1587 VectraSpcNWMgtD 1;
BA_ "VNSigAllNodes" SG_ 1587 VectraSpcNWMgtD 1;
BA_ "VNSigPrimaryTriggering" SG_ 1585 VectraSpcNWMgtD 1;
BA_ "VNSigRemoteDiagnostics" SG_ 1585 VectraSpcNWMgtD 1;
BA_ "VNSigInfotainment" SG_ 1585 VectraSpcNWMgtD 1;
BA_ "VNSigParkedVehicle" SG_ 1585 VectraSpcNWMgtD 1;
BA_ "VNSigIntermediate" SG_ 1585 VectraSpcNWMgtD 1;
BA_ "VNSigUnused_4" SG_ 1585 VectraSpcNWMgtD 1;
BA_ "SignalType" SG_ 1585 VectraSpcNWMgtD "UNM";
BA_ "SignalLongName" SG_ 1585 VectraSpcNWMgtD "Vectra Specific Network Management Data";
BA_ "VNSigDiagnostic" SG_ 1585 VectraSpcNWMgtD 1;
BA_ "VNSigAllNodes" SG_ 1585 VectraSpcNWMgtD 1;
BA_ "VNSigPrimaryTriggering" SG_ 1583 VectraSpcNWMgtD 1;
BA_ "VNSigRemoteDiagnostics" SG_ 1583 VectraSpcNWMgtD 1;
BA_ "VNSigInfotainment" SG_ 1583 VectraSpcNWMgtD 1;
BA_ "VNSigParkedVehicle" SG_ 1583 VectraSpcNWMgtD 1;
BA_ "VNSigIntermediate" SG_ 1583 VectraSpcNWMgtD 1;
BA_ "VNSigUnused_4" SG_ 1583 VectraSpcNWMgtD 1;
BA_ "SignalType" SG_ 1583 VectraSpcNWMgtD "UNM";
BA_ "SignalLongName" SG_ 1583 VectraSpcNWMgtD "Vectra Specific Network Management Data";
BA_ "VNSigDiagnostic" SG_ 1583 VectraSpcNWMgtD 1;
BA_ "VNSigAllNodes" SG_ 1583 VectraSpcNWMgtD 1;
BA_ "VNSigPrimaryTriggering" SG_ 1579 VectraSpcNWMgtD 1;
BA_ "VNSigRemoteDiagnostics" SG_ 1579 VectraSpcNWMgtD 1;
BA_ "VNSigInfotainment" SG_ 1579 VectraSpcNWMgtD 1;
BA_ "VNSigParkedVehicle" SG_ 1579 VectraSpcNWMgtD 1;
BA_ "VNSigIntermediate" SG_ 1579 VectraSpcNWMgtD 1;
BA_ "VNSigUnused_4" SG_ 1579 VectraSpcNWMgtD 1;
BA_ "SignalType" SG_ 1579 VectraSpcNWMgtD "UNM";
BA_ "SignalLongName" SG_ 1579 VectraSpcNWMgtD "Vectra Specific Network Management Data";
BA_ "VNSigDiagnostic" SG_ 1579 VectraSpcNWMgtD 1;
BA_ "VNSigAllNodes" SG_ 1579 VectraSpcNWMgtD 1;
BA_ "VNSigPrimaryTriggering" SG_ 1575 VectraSpcNWMgtD 1;
BA_ "VNSigRemoteDiagnostics" SG_ 1575 VectraSpcNWMgtD 1;
BA_ "VNSigInfotainment" SG_ 1575 VectraSpcNWMgtD 1;
BA_ "VNSigParkedVehicle" SG_ 1575 VectraSpcNWMgtD 1;
BA_ "VNSigIntermediate" SG_ 1575 VectraSpcNWMgtD 1;
BA_ "VNSigUnused_4" SG_ 1575 VectraSpcNWMgtD 1;
BA_ "SignalType" SG_ 1575 VectraSpcNWMgtD "UNM";
BA_ "SignalLongName" SG_ 1575 VectraSpcNWMgtD "Vectra Specific Network Management Data";
BA_ "VNSigDiagnostic" SG_ 1575 VectraSpcNWMgtD 1;
BA_ "VNSigAllNodes" SG_ 1575 VectraSpcNWMgtD 1;
BA_ "VNSigPrimaryTriggering" SG_ 1573 VectraSpcNWMgtD 1;
BA_ "VNSigRemoteDiagnostics" SG_ 1573 VectraSpcNWMgtD 1;
BA_ "VNSigInfotainment" SG_ 1573 VectraSpcNWMgtD 1;
BA_ "VNSigParkedVehicle" SG_ 1573 VectraSpcNWMgtD 1;
BA_ "VNSigIntermediate" SG_ 1573 VectraSpcNWMgtD 1;
BA_ "VNSigUnused_4" SG_ 1573 VectraSpcNWMgtD 1;
BA_ "SignalType" SG_ 1573 VectraSpcNWMgtD "UNM";
BA_ "SignalLongName" SG_ 1573 VectraSpcNWMgtD "Vectra Specific Network Management Data";
BA_ "VNSigDiagnostic" SG_ 1573 VectraSpcNWMgtD 1;
BA_ "VNSigAllNodes" SG_ 1573 VectraSpcNWMgtD 1;
BA_ "VNSigPrimaryTriggering" SG_ 1571 VectraSpcNWMgtD 1;
BA_ "VNSigRemoteDiagnostics" SG_ 1571 VectraSpcNWMgtD 1;
BA_ "VNSigInfotainment" SG_ 1571 VectraSpcNWMgtD 1;
BA_ "VNSigParkedVehicle" SG_ 1571 VectraSpcNWMgtD 1;
BA_ "VNSigIntermediate" SG_ 1571 VectraSpcNWMgtD 1;
BA_ "VNSigUnused_4" SG_ 1571 VectraSpcNWMgtD 1;
BA_ "SignalType" SG_ 1571 VectraSpcNWMgtD "UNM";
BA_ "SignalLongName" SG_ 1571 VectraSpcNWMgtD "Vectra Specific Network Management Data";
BA_ "VNSigDiagnostic" SG_ 1571 VectraSpcNWMgtD 1;
BA_ "VNSigAllNodes" SG_ 1571 VectraSpcNWMgtD 1;
BA_ "VNSigPrimaryTriggering" SG_ 1570 VectraSpcNWMgtD 1;
BA_ "VNSigRemoteDiagnostics" SG_ 1570 VectraSpcNWMgtD 1;
BA_ "VNSigInfotainment" SG_ 1570 VectraSpcNWMgtD 1;
BA_ "VNSigParkedVehicle" SG_ 1570 VectraSpcNWMgtD 1;
BA_ "VNSigIntermediate" SG_ 1570 VectraSpcNWMgtD 1;
BA_ "VNSigUnused_4" SG_ 1570 VectraSpcNWMgtD 1;
BA_ "SignalType" SG_ 1570 VectraSpcNWMgtD "UNM";
BA_ "SignalLongName" SG_ 1570 VectraSpcNWMgtD "Vectra Specific Network Management Data";
BA_ "VNSigDiagnostic" SG_ 1570 VectraSpcNWMgtD 1;
BA_ "VNSigAllNodes" SG_ 1570 VectraSpcNWMgtD 1;
BA_ "VNSigPrimaryTriggering" SG_ 1569 VectraSpcNWMgtD 1;
BA_ "VNSigRemoteDiagnostics" SG_ 1569 VectraSpcNWMgtD 1;
BA_ "VNSigInfotainment" SG_ 1569 VectraSpcNWMgtD 1;
BA_ "VNSigParkedVehicle" SG_ 1569 VectraSpcNWMgtD 1;
BA_ "VNSigIntermediate" SG_ 1569 VectraSpcNWMgtD 1;
BA_ "VNSigUnused_4" SG_ 1569 VectraSpcNWMgtD 1;
BA_ "SignalType" SG_ 1569 VectraSpcNWMgtD "UNM";
BA_ "SignalLongName" SG_ 1569 VectraSpcNWMgtD "Vectra Specific Network Management Data";
BA_ "VNSigDiagnostic" SG_ 1569 VectraSpcNWMgtD 1;
BA_ "VNSigAllNodes" SG_ 1569 VectraSpcNWMgtD 1;
BA_ "VNSigPrimaryTriggering" SG_ 1568 VectraSpcNWMgtD 1;
BA_ "VNSigRemoteDiagnostics" SG_ 1568 VectraSpcNWMgtD 1;
BA_ "VNSigInfotainment" SG_ 1568 VectraSpcNWMgtD 1;
BA_ "VNSigParkedVehicle" SG_ 1568 VectraSpcNWMgtD 1;
BA_ "VNSigIntermediate" SG_ 1568 VectraSpcNWMgtD 1;
BA_ "VNSigUnused_4" SG_ 1568 VectraSpcNWMgtD 1;
BA_ "SignalType" SG_ 1568 VectraSpcNWMgtD "UNM";
BA_ "SignalLongName" SG_ 1568 VectraSpcNWMgtD "Vectra Specific Network Management Data";
BA_ "VNSigDiagnostic" SG_ 1568 VectraSpcNWMgtD 1;
BA_ "VNSigAllNodes" SG_ 1568 VectraSpcNWMgtD 1;
BA_ "GenSigSendType" SG_ 2151251968 TICS_Ind1V 10;
BA_ "VNSigInfotainment" SG_ 2151251968 TICS_Ind1V 1;
BA_ "SignalType" SG_ 2151251968 TICS_Ind1V "ENM";
BA_ "PacketOrder" SG_ 2151251968 TICS_Ind1V 3;
BA_ "SignalLongName" SG_ 2151251968 TICS_Ind1V "Telematics Indication Control Status : Indicator 1 Validity";
BA_ "VNSigAllNodes" SG_ 2151251968 TICS_Ind1V 1;
BA_ "GenSigDeltaValue" SG_ 2151251968 TICS_Ind1FlshRtOnSt 1;
BA_ "GenSigSendType" SG_ 2151251968 TICS_Ind1FlshRtOnSt 12;
BA_ "VNSigInfotainment" SG_ 2151251968 TICS_Ind1FlshRtOnSt 1;
BA_ "SignalType" SG_ 2151251968 TICS_Ind1FlshRtOnSt "UNM";
BA_ "PacketOrder" SG_ 2151251968 TICS_Ind1FlshRtOnSt 5;
BA_ "SignalLongName" SG_ 2151251968 TICS_Ind1FlshRtOnSt "Telematics Indication Control Status : Indicator 1 Flash Rate On Status";
BA_ "VNSigAllNodes" SG_ 2151251968 TICS_Ind1FlshRtOnSt 1;
BA_ "GenSigDeltaValue" SG_ 2151251968 TICS_Ind1FlshRtOffSt 1;
BA_ "GenSigSendType" SG_ 2151251968 TICS_Ind1FlshRtOffSt 12;
BA_ "VNSigInfotainment" SG_ 2151251968 TICS_Ind1FlshRtOffSt 1;
BA_ "SignalType" SG_ 2151251968 TICS_Ind1FlshRtOffSt "UNM";
BA_ "PacketOrder" SG_ 2151251968 TICS_Ind1FlshRtOffSt 4;
BA_ "SignalLongName" SG_ 2151251968 TICS_Ind1FlshRtOffSt "Telematics Indication Control Status : Indicator 1 Flash Rate Off Status";
BA_ "VNSigAllNodes" SG_ 2151251968 TICS_Ind1FlshRtOffSt 1;
BA_ "GenSigSendType" SG_ 2151251968 TICS_Ind1 10;
BA_ "VNSigInfotainment" SG_ 2151251968 TICS_Ind1 1;
BA_ "SignalType" SG_ 2151251968 TICS_Ind1 "ENM";
BA_ "PacketOrder" SG_ 2151251968 TICS_Ind1 2;
BA_ "SignalLongName" SG_ 2151251968 TICS_Ind1 "Telematics Indication Control Status : Indicator 1";
BA_ "VNSigAllNodes" SG_ 2151251968 TICS_Ind1 1;
BA_ "GenSigSendType" SG_ 2151251968 TICS_Ind1Stat 10;
BA_ "VNSigInfotainment" SG_ 2151251968 TICS_Ind1Stat 1;
BA_ "SignalType" SG_ 2151251968 TICS_Ind1Stat "ENM";
BA_ "PacketOrder" SG_ 2151251968 TICS_Ind1Stat 1;
BA_ "SignalLongName" SG_ 2151251968 TICS_Ind1Stat "Telematics Indication Control Status : Indication 1 Status";
BA_ "VNSigAllNodes" SG_ 2151251968 TICS_Ind1Stat 1;
BA_ "GenSigDeltaValue" SG_ 2153857024 TnDrvTrCtrlEvntsRpt 1;
BA_ "GenSigSendType" SG_ 2153857024 TnDrvTrCtrlEvntsRpt 12;
BA_ "GenSigSendOnInit" SG_ 2153857024 TnDrvTrCtrlEvntsRpt 2;
BA_ "SignalType" SG_ 2153857024 TnDrvTrCtrlEvntsRpt "UNM";
BA_ "SignalLongName" SG_ 2153857024 TnDrvTrCtrlEvntsRpt "Teen Driver Traction Control Events Report";
BA_ "VNSigAllNodes" SG_ 2153857024 TnDrvTrCtrlEvntsRpt 1;
BA_ "GenSigDeltaValue" SG_ 2153857024 TnDrvDrowDrvAlrtsRpt 1;
BA_ "GenSigSendType" SG_ 2153857024 TnDrvDrowDrvAlrtsRpt 12;
BA_ "GenSigSendOnInit" SG_ 2153857024 TnDrvDrowDrvAlrtsRpt 2;
BA_ "SignalType" SG_ 2153857024 TnDrvDrowDrvAlrtsRpt "UNM";
BA_ "SignalLongName" SG_ 2153857024 TnDrvDrowDrvAlrtsRpt "Teen Driver Drowsy Driver Alerts Report";
BA_ "VNSigAllNodes" SG_ 2153857024 TnDrvDrowDrvAlrtsRpt 1;
BA_ "GenSigSendType" SG_ 2153857024 TDRCADD_WOTEvnts 10;
BA_ "GenSigSendOnInit" SG_ 2153857024 TDRCADD_WOTEvnts 2;
BA_ "SignalType" SG_ 2153857024 TDRCADD_WOTEvnts "BLN";
BA_ "PacketOrder" SG_ 2153857024 TDRCADD_WOTEvnts 12;
BA_ "SignalLongName" SG_ 2153857024 TDRCADD_WOTEvnts "Teen Driver Report Card Available Display Data : Wide Open Throttle Events";
BA_ "VNSigAllNodes" SG_ 2153857024 TDRCADD_WOTEvnts 1;
BA_ "GenSigSendType" SG_ 2153857024 TDRCADD_LDWEvnts 10;
BA_ "GenSigSendOnInit" SG_ 2153857024 TDRCADD_LDWEvnts 2;
BA_ "SignalType" SG_ 2153857024 TDRCADD_LDWEvnts "BLN";
BA_ "PacketOrder" SG_ 2153857024 TDRCADD_LDWEvnts 13;
BA_ "SignalLongName" SG_ 2153857024 TDRCADD_LDWEvnts "Teen Driver Report Card Available Display Data : Lane Departure Warning Events";
BA_ "VNSigAllNodes" SG_ 2153857024 TDRCADD_LDWEvnts 1;
BA_ "GenSigSendType" SG_ 2153857024 TDRCADD_FCMBrEvts 10;
BA_ "GenSigSendOnInit" SG_ 2153857024 TDRCADD_FCMBrEvts 2;
BA_ "SignalType" SG_ 2153857024 TDRCADD_FCMBrEvts "BLN";
BA_ "PacketOrder" SG_ 2153857024 TDRCADD_FCMBrEvts 10;
BA_ "SignalLongName" SG_ 2153857024 TDRCADD_FCMBrEvts "Teen Driver Report Card Available Display Data : Forward Collision Mitigation Braking Events";
BA_ "VNSigAllNodes" SG_ 2153857024 TDRCADD_FCMBrEvts 1;
BA_ "GenSigSendType" SG_ 2153857024 TDRCADD_DrwDrvAlrt 10;
BA_ "GenSigSendOnInit" SG_ 2153857024 TDRCADD_DrwDrvAlrt 2;
BA_ "SignalType" SG_ 2153857024 TDRCADD_DrwDrvAlrt "BLN";
BA_ "PacketOrder" SG_ 2153857024 TDRCADD_DrwDrvAlrt 11;
BA_ "SignalLongName" SG_ 2153857024 TDRCADD_DrwDrvAlrt "Teen Driver Report Card Available Display Data : Drowsy Driver Alerts";
BA_ "VNSigAllNodes" SG_ 2153857024 TDRCADD_DrwDrvAlrt 1;
BA_ "GenSigSendType" SG_ 2153857024 TDRCADD_RCMBrEvts 10;
BA_ "GenSigSendOnInit" SG_ 2153857024 TDRCADD_RCMBrEvts 2;
BA_ "SignalType" SG_ 2153857024 TDRCADD_RCMBrEvts "BLN";
BA_ "PacketOrder" SG_ 2153857024 TDRCADD_RCMBrEvts 9;
BA_ "SignalLongName" SG_ 2153857024 TDRCADD_RCMBrEvts "Teen Driver Report Card Available Display Data : Reverse Collision Mitigation Braking Events";
BA_ "VNSigAllNodes" SG_ 2153857024 TDRCADD_RCMBrEvts 1;
BA_ "GenSigSendType" SG_ 2153857024 TDRCADD_FCImntAlrts 10;
BA_ "GenSigSendOnInit" SG_ 2153857024 TDRCADD_FCImntAlrts 2;
BA_ "SignalType" SG_ 2153857024 TDRCADD_FCImntAlrts "BLN";
BA_ "PacketOrder" SG_ 2153857024 TDRCADD_FCImntAlrts 8;
BA_ "SignalLongName" SG_ 2153857024 TDRCADD_FCImntAlrts "Teen Driver Report Card Available Display Data : Forward Collision Imminent Alerts";
BA_ "VNSigAllNodes" SG_ 2153857024 TDRCADD_FCImntAlrts 1;
BA_ "GenSigSendType" SG_ 2153857024 TDRCADD_FCHdwyAlrt 10;
BA_ "GenSigSendOnInit" SG_ 2153857024 TDRCADD_FCHdwyAlrt 2;
BA_ "SignalType" SG_ 2153857024 TDRCADD_FCHdwyAlrt "BLN";
BA_ "PacketOrder" SG_ 2153857024 TDRCADD_FCHdwyAlrt 7;
BA_ "SignalLongName" SG_ 2153857024 TDRCADD_FCHdwyAlrt "Teen Driver Report Card Available Display Data : Forward Collision Headway Alerts";
BA_ "VNSigAllNodes" SG_ 2153857024 TDRCADD_FCHdwyAlrt 1;
BA_ "GenSigSendType" SG_ 2153857024 TDRCADD_StCtrlEvnts 10;
BA_ "GenSigSendOnInit" SG_ 2153857024 TDRCADD_StCtrlEvnts 2;
BA_ "SignalType" SG_ 2153857024 TDRCADD_StCtrlEvnts "BLN";
BA_ "PacketOrder" SG_ 2153857024 TDRCADD_StCtrlEvnts 5;
BA_ "SignalLongName" SG_ 2153857024 TDRCADD_StCtrlEvnts "Teen Driver Report Card Available Display Data : Stability Control Events";
BA_ "VNSigAllNodes" SG_ 2153857024 TDRCADD_StCtrlEvnts 1;
BA_ "GenSigSendType" SG_ 2153857024 TDRCADD_ABSAtvEvt 10;
BA_ "GenSigSendOnInit" SG_ 2153857024 TDRCADD_ABSAtvEvt 2;
BA_ "SignalType" SG_ 2153857024 TDRCADD_ABSAtvEvt "BLN";
BA_ "PacketOrder" SG_ 2153857024 TDRCADD_ABSAtvEvt 6;
BA_ "SignalLongName" SG_ 2153857024 TDRCADD_ABSAtvEvt "Teen Driver Report Card Available Display Data : Antilock Braking System Active Events";
BA_ "VNSigAllNodes" SG_ 2153857024 TDRCADD_ABSAtvEvt 1;
BA_ "GenSigSendType" SG_ 2153857024 TDRCADD_TrCtrlEvnts 10;
BA_ "GenSigSendOnInit" SG_ 2153857024 TDRCADD_TrCtrlEvnts 2;
BA_ "SignalType" SG_ 2153857024 TDRCADD_TrCtrlEvnts "BLN";
BA_ "PacketOrder" SG_ 2153857024 TDRCADD_TrCtrlEvnts 4;
BA_ "SignalLongName" SG_ 2153857024 TDRCADD_TrCtrlEvnts "Teen Driver Report Card Available Display Data : Traction Control Events";
BA_ "VNSigAllNodes" SG_ 2153857024 TDRCADD_TrCtrlEvnts 1;
BA_ "GenSigSendType" SG_ 2153857024 TDRCADD_OvSpdEvnt 10;
BA_ "GenSigSendOnInit" SG_ 2153857024 TDRCADD_OvSpdEvnt 2;
BA_ "SignalType" SG_ 2153857024 TDRCADD_OvSpdEvnt "BLN";
BA_ "PacketOrder" SG_ 2153857024 TDRCADD_OvSpdEvnt 3;
BA_ "SignalLongName" SG_ 2153857024 TDRCADD_OvSpdEvnt "Teen Driver Report Card Available Display Data : Overspeed Events";
BA_ "VNSigAllNodes" SG_ 2153857024 TDRCADD_OvSpdEvnt 1;
BA_ "GenSigSendType" SG_ 2153857024 TDRCADD_DistDrvn 10;
BA_ "GenSigSendOnInit" SG_ 2153857024 TDRCADD_DistDrvn 2;
BA_ "SignalType" SG_ 2153857024 TDRCADD_DistDrvn "BLN";
BA_ "PacketOrder" SG_ 2153857024 TDRCADD_DistDrvn 2;
BA_ "SignalLongName" SG_ 2153857024 TDRCADD_DistDrvn "Teen Driver Report Card Available Display Data : Distance Driven";
BA_ "VNSigAllNodes" SG_ 2153857024 TDRCADD_DistDrvn 1;
BA_ "GenSigSendType" SG_ 2153857024 TDRCADD_MaxSpd 10;
BA_ "GenSigSendOnInit" SG_ 2153857024 TDRCADD_MaxSpd 2;
BA_ "SignalType" SG_ 2153857024 TDRCADD_MaxSpd "BLN";
BA_ "PacketOrder" SG_ 2153857024 TDRCADD_MaxSpd 1;
BA_ "SignalLongName" SG_ 2153857024 TDRCADD_MaxSpd "Teen Driver Report Card Available Display Data : Maximum Speed";
BA_ "VNSigAllNodes" SG_ 2153857024 TDRCADD_MaxSpd 1;
BA_ "GenSigDeltaValue" SG_ 2153857024 TnDrvStblCtrlEvntsRpt 1;
BA_ "GenSigSendType" SG_ 2153857024 TnDrvStblCtrlEvntsRpt 12;
BA_ "GenSigSendOnInit" SG_ 2153857024 TnDrvStblCtrlEvntsRpt 2;
BA_ "SignalType" SG_ 2153857024 TnDrvStblCtrlEvntsRpt "UNM";
BA_ "SignalLongName" SG_ 2153857024 TnDrvStblCtrlEvntsRpt "Teen Driver Stability Control Events Report";
BA_ "VNSigAllNodes" SG_ 2153857024 TnDrvStblCtrlEvntsRpt 1;
BA_ "GenSigDeltaValue" SG_ 2153857024 TnDrvABSAtvEvntsRpt 1;
BA_ "GenSigSendType" SG_ 2153857024 TnDrvABSAtvEvntsRpt 12;
BA_ "GenSigSendOnInit" SG_ 2153857024 TnDrvABSAtvEvntsRpt 2;
BA_ "SignalType" SG_ 2153857024 TnDrvABSAtvEvntsRpt "UNM";
BA_ "SignalLongName" SG_ 2153857024 TnDrvABSAtvEvntsRpt "Teen Driver Antilock Brake System Active Events Report";
BA_ "VNSigAllNodes" SG_ 2153857024 TnDrvABSAtvEvntsRpt 1;
BA_ "GenSigDeltaValue" SG_ 2153857024 TeenDrvWOTEvntsRpt 1;
BA_ "GenSigSendType" SG_ 2153857024 TeenDrvWOTEvntsRpt 12;
BA_ "GenSigSendOnInit" SG_ 2153857024 TeenDrvWOTEvntsRpt 2;
BA_ "SignalType" SG_ 2153857024 TeenDrvWOTEvntsRpt "UNM";
BA_ "SignalLongName" SG_ 2153857024 TeenDrvWOTEvntsRpt "Teen Driver Wide Open Throttle Events Report";
BA_ "VNSigAllNodes" SG_ 2153857024 TeenDrvWOTEvntsRpt 1;
BA_ "GenSigSendType" SG_ 2153865216 TnDrvStBltShftIntrlkCsStRq 10;
BA_ "SignalType" SG_ 2153865216 TnDrvStBltShftIntrlkCsStRq "ENM";
BA_ "SignalLongName" SG_ 2153865216 TnDrvStBltShftIntrlkCsStRq "Teen Driver Seat Belt Shift Interlock Customization Setting Request";
BA_ "VNSigAllNodes" SG_ 2153865216 TnDrvStBltShftIntrlkCsStRq 1;
BA_ "GenSigSendType" SG_ 2153865216 StBltShftIntrlkCsStRq 10;
BA_ "SignalType" SG_ 2153865216 StBltShftIntrlkCsStRq "ENM";
BA_ "SignalLongName" SG_ 2153865216 StBltShftIntrlkCsStRq "Seat Belt Shift Interlock Customization Setting Request";
BA_ "VNSigAllNodes" SG_ 2153865216 StBltShftIntrlkCsStRq 1;
BA_ "GenSigSendType" SG_ 2153865216 TeenDrvReq 10;
BA_ "SignalType" SG_ 2153865216 TeenDrvReq "ENM";
BA_ "SignalLongName" SG_ 2153865216 TeenDrvReq "Teen Driver Request";
BA_ "VNSigAllNodes" SG_ 2153865216 TeenDrvReq 1;
BA_ "GenSigSendType" SG_ 2153865216 TeenDrvPinCd 10;
BA_ "SignalType" SG_ 2153865216 TeenDrvPinCd "BCD";
BA_ "SignalLongName" SG_ 2153865216 TeenDrvPinCd "Teen Driver PIN Code";
BA_ "VNSigAllNodes" SG_ 2153865216 TeenDrvPinCd 1;
BA_ "GenSigSendType" SG_ 2153865216 TnDrvSpdLmtCstStReq 10;
BA_ "SignalType" SG_ 2153865216 TnDrvSpdLmtCstStReq "ENM";
BA_ "SignalLongName" SG_ 2153865216 TnDrvSpdLmtCstStReq "Teen Driver Speed Limit Customization Setting Request";
BA_ "VNSigAllNodes" SG_ 2153865216 TnDrvSpdLmtCstStReq 1;
BA_ "GenSigSendType" SG_ 2153865216 TDOWCSR_StatReq 10;
BA_ "SignalType" SG_ 2153865216 TDOWCSR_StatReq "ENM";
BA_ "PacketOrder" SG_ 2153865216 TDOWCSR_StatReq 1;
BA_ "SignalLongName" SG_ 2153865216 TDOWCSR_StatReq "Teen Driver Overspeed Warning Customization Setting Request : Status Request";
BA_ "VNSigAllNodes" SG_ 2153865216 TDOWCSR_StatReq 1;
BA_ "GenSigSendType" SG_ 2153865216 TDOWCSR_IncSwAct 10;
BA_ "SignalType" SG_ 2153865216 TDOWCSR_IncSwAct "BLN";
BA_ "PacketOrder" SG_ 2153865216 TDOWCSR_IncSwAct 2;
BA_ "SignalLongName" SG_ 2153865216 TDOWCSR_IncSwAct "Teen Driver Overspeed Warning Customization Setting Request : Increment  Switch Active";
BA_ "VNSigAllNodes" SG_ 2153865216 TDOWCSR_IncSwAct 1;
BA_ "GenSigSendType" SG_ 2153865216 TDOWCSR_DecSwAct 10;
BA_ "SignalType" SG_ 2153865216 TDOWCSR_DecSwAct "BLN";
BA_ "PacketOrder" SG_ 2153865216 TDOWCSR_DecSwAct 3;
BA_ "SignalLongName" SG_ 2153865216 TDOWCSR_DecSwAct "Teen Driver Overspeed Warning Customization Setting Request : Decrement  Switch Active";
BA_ "VNSigAllNodes" SG_ 2153865216 TDOWCSR_DecSwAct 1;
BA_REL_ "GenSigSuprvResp" BU_SG_REL_ IPC_LE SG_ 2150531072 OBHVDCCMinRmng 1;
BA_REL_ "GenSigSuprvResp" BU_SG_REL_ VCU_LE SG_ 2150531072 OBHVDCCMinRmng 1;
BA_REL_ "GenSigSuprvResp" BU_SG_REL_ VCU_LE SG_ 2150531072 OBHVDCCMinRmng 1;
BA_REL_ "GenSigSuprvResp" BU_SG_REL_ RadioHead_LE SG_ 2150531072 OBHVDCCMinRmng 1;
BA_REL_ "GenSigSuprvResp" BU_SG_REL_ IPC_LE SG_ 2150531072 OBHVDCCCpltnTmDspFrmt 1;
BA_REL_ "GenSigSuprvResp" BU_SG_REL_ VCU_LE SG_ 2150531072 OBHVDCCCpltnTmDspFrmt 1;
BA_REL_ "GenSigSuprvResp" BU_SG_REL_ VCU_LE SG_ 2150531072 OBHVDCCCpltnTmDspFrmt 1;
BA_REL_ "GenSigSuprvResp" BU_SG_REL_ RadioHead_LE SG_ 2150531072 OBHVDCCCpltnTmDspFrmt 1;
BA_REL_ "GenSigSuprvResp" BU_SG_REL_ VCU_LE SG_ 2150531072 HVBChrgLmtBtnDspStat 1;
BA_REL_ "GenSigSuprvResp" BU_SG_REL_ CSM_LE SG_ 2150531072 HVBChrgLmtBtnDspStat 1;
BA_REL_ "GenSigSuprvResp" BU_SG_REL_ RadioHead_LE SG_ 2150531072 HVBChrgLmtBtnDspStat 1;
BA_REL_ "GenSigSuprvResp" BU_SG_REL_ VCU_LE SG_ 2150531072 HVBHmChrgTmDspStat 1;
BA_REL_ "GenSigSuprvResp" BU_SG_REL_ CSM_LE SG_ 2150531072 HVBHmChrgTmDspStat 1;
BA_REL_ "GenSigSuprvResp" BU_SG_REL_ RadioHead_LE SG_ 2150531072 HVBHmChrgTmDspStat 1;
BA_REL_ "GenSigSuprvResp" BU_SG_REL_ VCU_LE SG_ 2150531072 HVBChrgTmDspStat 1;
BA_REL_ "GenSigSuprvResp" BU_SG_REL_ CSM_LE SG_ 2150531072 HVBChrgTmDspStat 1;
BA_REL_ "GenSigSuprvResp" BU_SG_REL_ RadioHead_LE SG_ 2150531072 HVBChrgTmDspStat 1;
BA_REL_ "GenSigSuprvResp" BU_SG_REL_ VCU_LE SG_ 2150531072 HVBChrgOvrdBtnDspStat 1;
BA_REL_ "GenSigSuprvResp" BU_SG_REL_ CSM_LE SG_ 2150531072 HVBChrgOvrdBtnDspStat 1;
BA_REL_ "GenSigSuprvResp" BU_SG_REL_ RadioHead_LE SG_ 2150531072 HVBChrgOvrdBtnDspStat 1;
BA_REL_ "GenSigSuprvResp" BU_SG_REL_ VCU_LE SG_ 2151702528 LnMrkngIndRgt 1;
BA_REL_ "GenSigSuprvResp" BU_SG_REL_ IPC_LE SG_ 2151702528 LnMrkngIndRgt 1;
BA_REL_ "GenSigSuprvResp" BU_SG_REL_ VCU_LE SG_ 2151702528 LnMrkngIndLft 1;
BA_REL_ "GenSigSuprvResp" BU_SG_REL_ IPC_LE SG_ 2151702528 LnMrkngIndLft 1;
BA_REL_ "GenSigSuprvResp" BU_SG_REL_ VCU_LE SG_ 2151702528 LnKepAsstStIndRgt 1;
BA_REL_ "GenSigSuprvResp" BU_SG_REL_ IPC_LE SG_ 2151702528 LnKepAsstStIndRgt 1;
BA_REL_ "GenSigSuprvResp" BU_SG_REL_ VCU_LE SG_ 2151702528 LnKepAsstStIndLft 1;
BA_REL_ "GenSigSuprvResp" BU_SG_REL_ IPC_LE SG_ 2151702528 LnKepAsstStIndLft 1;
BA_REL_ "GenSigSuprvResp" BU_SG_REL_ VCU_LE SG_ 2151702528 LnKpngAstRecfblIndRq 1;
BA_REL_ "GenSigSuprvResp" BU_SG_REL_ IPC_LE SG_ 2151702528 LnKpngAstRecfblIndRq 1;
BA_REL_ "GenSigSuprvResp" BU_SG_REL_ CSM_LE SG_ 2152628224 OBTCMstrStat 1;
BA_REL_ "GenSigSuprvResp" BU_SG_REL_ CSM_LE SG_ 2152628224 OBTCR_ReqstrID 1;
BA_REL_ "GenSigSuprvResp" BU_SG_REL_ CSM_LE SG_ 2152628224 OBTCR_Stat 1;
BA_REL_ "GenSigSuprvResp" BU_SG_REL_ RSC_LE SG_ 2154725376 AuxHtrAtv378 1;
BA_REL_ "GenSigSuprvResp" BU_SG_REL_ RSC_LE SG_ 2154725376 AuxHtrRq 1;
BA_REL_ "GenSigSuprvResp" BU_SG_REL_ CSM_LE SG_ 2158133248 ChrgCmpltFstChgingAct 1;
BA_REL_ "GenSigSuprvResp" BU_SG_REL_ RadioHead_LE SG_ 2158133248 ChrgCmpltFstChgingAct 1;
BA_REL_ "GenSigSuprvResp" BU_SG_REL_ VCU_LE SG_ 2158133248 ChrgCmpltFstChgingAct 1;
BA_REL_ "GenSigSuprvResp" BU_SG_REL_ VCU_LE SG_ 2158133248 ChrgCmpltFstChgingAct 1;
BA_REL_ "GenSigSuprvResp" BU_SG_REL_ IPC_LE SG_ 2158133248 ChrgCmpltFstChgingAct 1;
BA_REL_ "GenSigSuprvResp" BU_SG_REL_ VCU_LE SG_ 2158133248 TgtChrgLvlPctgCurStValPKIn 1;
BA_REL_ "GenSigSuprvResp" BU_SG_REL_ IPC_LE SG_ 2158133248 TgtChrgLvlPctgCurStValPKIn 1;
BA_REL_ "GenSigSuprvResp" BU_SG_REL_ VCU_LE SG_ 2158133248 TrgtChrgLvlAct 1;
BA_REL_ "GenSigSuprvResp" BU_SG_REL_ IPC_LE SG_ 2158133248 TrgtChrgLvlAct 1;
BA_REL_ "GenSigSuprvResp" BU_SG_REL_ VCU_LE SG_ 2158133248 HTRCsStAvail 1;
BA_REL_ "GenSigSuprvResp" BU_SG_REL_ CSM_LE SG_ 2158133248 HTRCsStAvail 1;
BA_REL_ "GenSigSuprvResp" BU_SG_REL_ RadioHead_LE SG_ 2158133248 HTRCsStAvail 1;
BA_REL_ "GenSigSuprvResp" BU_SG_REL_ VCU_LE SG_ 2158133248 HTRCsCrStVal 1;
BA_REL_ "GenSigSuprvResp" BU_SG_REL_ CSM_LE SG_ 2158133248 HTRCsCrStVal 1;
BA_REL_ "GenSigSuprvResp" BU_SG_REL_ RadioHead_LE SG_ 2158133248 HTRCsCrStVal 1;
BA_REL_ "GenSigSuprvResp" BU_SG_REL_ VCU_LE SG_ 2158133248 HTRCA_Res3Avail 1;
BA_REL_ "GenSigSuprvResp" BU_SG_REL_ CSM_LE SG_ 2158133248 HTRCA_Res3Avail 1;
BA_REL_ "GenSigSuprvResp" BU_SG_REL_ RadioHead_LE SG_ 2158133248 HTRCA_Res3Avail 1;
BA_REL_ "GenSigSuprvResp" BU_SG_REL_ VCU_LE SG_ 2158133248 HTRCA_Res2Avail 1;
BA_REL_ "GenSigSuprvResp" BU_SG_REL_ CSM_LE SG_ 2158133248 HTRCA_Res2Avail 1;
BA_REL_ "GenSigSuprvResp" BU_SG_REL_ RadioHead_LE SG_ 2158133248 HTRCA_Res2Avail 1;
BA_REL_ "GenSigSuprvResp" BU_SG_REL_ VCU_LE SG_ 2158133248 HTRCA_Res1Avail 1;
BA_REL_ "GenSigSuprvResp" BU_SG_REL_ CSM_LE SG_ 2158133248 HTRCA_Res1Avail 1;
BA_REL_ "GenSigSuprvResp" BU_SG_REL_ RadioHead_LE SG_ 2158133248 HTRCA_Res1Avail 1;
BA_REL_ "GenSigSuprvResp" BU_SG_REL_ VCU_LE SG_ 2158133248 HTRCA_OnAwAvail 1;
BA_REL_ "GenSigSuprvResp" BU_SG_REL_ CSM_LE SG_ 2158133248 HTRCA_OnAwAvail 1;
BA_REL_ "GenSigSuprvResp" BU_SG_REL_ RadioHead_LE SG_ 2158133248 HTRCA_OnAwAvail 1;
BA_REL_ "GenSigSuprvResp" BU_SG_REL_ VCU_LE SG_ 2158133248 HTRCA_OnHmAvail 1;
BA_REL_ "GenSigSuprvResp" BU_SG_REL_ CSM_LE SG_ 2158133248 HTRCA_OnHmAvail 1;
BA_REL_ "GenSigSuprvResp" BU_SG_REL_ RadioHead_LE SG_ 2158133248 HTRCA_OnHmAvail 1;
BA_REL_ "GenSigSuprvResp" BU_SG_REL_ VCU_LE SG_ 2158133248 HTRCA_OnAvail 1;
BA_REL_ "GenSigSuprvResp" BU_SG_REL_ CSM_LE SG_ 2158133248 HTRCA_OnAvail 1;
BA_REL_ "GenSigSuprvResp" BU_SG_REL_ RadioHead_LE SG_ 2158133248 HTRCA_OnAvail 1;
BA_REL_ "GenSigSuprvResp" BU_SG_REL_ VCU_LE SG_ 2158133248 HTRCA_OffAvail 1;
BA_REL_ "GenSigSuprvResp" BU_SG_REL_ CSM_LE SG_ 2158133248 HTRCA_OffAvail 1;
BA_REL_ "GenSigSuprvResp" BU_SG_REL_ RadioHead_LE SG_ 2158133248 HTRCA_OffAvail 1;
BA_REL_ "GenSigSuprvResp" BU_SG_REL_ VPM_LE SG_ 2154651648 TAC_AudConctOutcm 1;
BA_REL_ "GenSigSuprvResp" BU_SG_REL_ VPM_LE SG_ 2154651648 TAC_AudChConctStat 1;
BA_REL_ "GenSigSuprvResp" BU_SG_REL_ VPM_LE SG_ 2154635264 TAR_AudSrcStat 1;
BA_REL_ "GenSigSuprvResp" BU_SG_REL_ VPM_LE SG_ 2154635264 TAR_AudConctReq 1;
BA_REL_ "GenSigSuprvResp" BU_SG_REL_ CSM_LE SG_ 2154872832 InfoActvnReq 1;
BA_REL_ "GenSigRxStartValue" BU_SG_REL_ CHUD_LE SG_ 2154569728 InfotnmntSysSt "0";
BA_REL_ "GenSigSuprvResp" BU_SG_REL_ CHUD_LE SG_ 2154569728 InfotnmntSysSt 1;
BA_REL_ "GenSigSuprvResp" BU_SG_REL_ VCU_LE SG_ 2154569728 InfotnmntSysSt 1;
BA_REL_ "GenSigSuprvResp" BU_SG_REL_ TouchPad_LE SG_ 2154569728 InfotnmntSysSt 1;
BA_REL_ "GenSigSuprvResp" BU_SG_REL_ RSE_LE SG_ 2154569728 InfotnmntSysSt 1;
BA_REL_ "GenSigSuprvResp" BU_SG_REL_ RSC_LE SG_ 2154569728 InfotnmntSysSt 1;
BA_REL_ "GenSigSuprvResp" BU_SG_REL_ ICS_LE SG_ 2154569728 InfotnmntSysSt 1;
BA_REL_ "GenSigSuprvResp" BU_SG_REL_ LVMPC_LE SG_ 2154569728 InfotnmntSysSt 1;
BA_REL_ "GenSigSuprvResp" BU_SG_REL_ LVMNav_LE SG_ 2154569728 InfotnmntSysSt 1;
BA_REL_ "GenSigSuprvResp" BU_SG_REL_ IPC_LE SG_ 2154569728 InfotnmntSysSt 1;
BA_REL_ "GenSigSuprvResp" BU_SG_REL_ AMP_LE SG_ 2154569728 InfotnmntSysSt 1;
BA_REL_ "GenSigSuprvResp" BU_SG_REL_ TCP_LE SG_ 2154569728 InfotnmntSysSt 1;
BA_REL_ "GenSigSuprvResp" BU_SG_REL_ VCU_LE SG_ 2151931904 FourWhlDrvIdReqExtRng 1;
BA_REL_ "GenSigSuprvResp" BU_SG_REL_ IPC_LE SG_ 2151931904 FourWhlDrvIdReqExtRng 1;
BA_REL_ "GenSigSuprvResp" BU_SG_REL_ VCU_LE SG_ 2151931904 FuelMdTrnstnIndReq 1;
BA_REL_ "GenSigSuprvResp" BU_SG_REL_ IPC_LE SG_ 2151931904 FuelMdTrnstnIndReq 1;
BA_REL_ "GenSigSuprvResp" BU_SG_REL_ VCU_LE SG_ 2151931904 BiFuelRflGaslinIndReq 1;
BA_REL_ "GenSigSuprvResp" BU_SG_REL_ IPC_LE SG_ 2151931904 BiFuelRflGaslinIndReq 1;
BA_REL_ "GenSigSuprvResp" BU_SG_REL_ VCU_LE SG_ 2151931904 TCSysCurSt 1;
BA_REL_ "GenSigSuprvResp" BU_SG_REL_ IPC_LE SG_ 2151931904 TCSysCurSt 1;
BA_REL_ "GenSigSuprvResp" BU_SG_REL_ VCU_LE SG_ 2151931904 ElctShfPriLtdPerfMdIO 1;
BA_REL_ "GenSigSuprvResp" BU_SG_REL_ IPC_LE SG_ 2151931904 ElctShfPriLtdPerfMdIO 1;
BA_REL_ "GenSigSuprvResp" BU_SG_REL_ VCU_LE SG_ 2151931904 LnchCtrlEngRPMStat 1;
BA_REL_ "GenSigSuprvResp" BU_SG_REL_ IPC_LE SG_ 2151931904 LnchCtrlEngRPMStat 1;
BA_REL_ "GenSigSuprvResp" BU_SG_REL_ VCU_LE SG_ 2151931904 RegVltCtlEngyRcvryAct 1;
BA_REL_ "GenSigSuprvResp" BU_SG_REL_ IPC_LE SG_ 2151931904 RegVltCtlEngyRcvryAct 1;
BA_REL_ "GenSigSuprvResp" BU_SG_REL_ V2V_LE SG_ 2151931904 VehSpdCntlSystmType 1;
BA_REL_ "GenSigSuprvResp" BU_SG_REL_ VCU_LE SG_ 2151931904 VehSpdCntlSystmType 1;
BA_REL_ "GenSigSuprvResp" BU_SG_REL_ IPC_LE SG_ 2151931904 VehSpdCntlSystmType 1;
BA_REL_ "GenSigSuprvResp" BU_SG_REL_ V2V_LE SG_ 2151931904 ACCSysSltdMdDispIO 1;
BA_REL_ "GenSigSuprvResp" BU_SG_REL_ VCU_LE SG_ 2151931904 ACCSysSltdMdDispIO 1;
BA_REL_ "GenSigSuprvResp" BU_SG_REL_ IPC_LE SG_ 2151931904 ACCSysSltdMdDispIO 1;
BA_REL_ "GenSigSuprvResp" BU_SG_REL_ V2V_LE SG_ 2151931904 ACCSysSltdMd 1;
BA_REL_ "GenSigSuprvResp" BU_SG_REL_ VCU_LE SG_ 2151931904 ACCSysSltdMd 1;
BA_REL_ "GenSigSuprvResp" BU_SG_REL_ IPC_LE SG_ 2151931904 ACCSysSltdMd 1;
BA_REL_ "GenSigSuprvResp" BU_SG_REL_ VCU_LE SG_ 2151931904 PTExPrtclFltWrng3IO 1;
BA_REL_ "GenSigSuprvResp" BU_SG_REL_ IPC_LE SG_ 2151931904 PTExPrtclFltWrng3IO 1;
BA_REL_ "GenSigSuprvResp" BU_SG_REL_ VCU_LE SG_ 2151931904 PTExPartFltManRegStat 1;
BA_REL_ "GenSigSuprvResp" BU_SG_REL_ IPC_LE SG_ 2151931904 PTExPartFltManRegStat 1;
BA_REL_ "GenSigSuprvResp" BU_SG_REL_ VCU_LE SG_ 2151931904 LnchCtrlWhlSlpStat 1;
BA_REL_ "GenSigSuprvResp" BU_SG_REL_ IPC_LE SG_ 2151931904 LnchCtrlWhlSlpStat 1;
BA_REL_ "GenSigSuprvResp" BU_SG_REL_ VCU_LE SG_ 2151931904 LnchCtrlMdStat 1;
BA_REL_ "GenSigSuprvResp" BU_SG_REL_ IPC_LE SG_ 2151931904 LnchCtrlMdStat 1;
BA_REL_ "GenSigSuprvResp" BU_SG_REL_ VCU_LE SG_ 2151931904 AWDRecmndIO 1;
BA_REL_ "GenSigSuprvResp" BU_SG_REL_ IPC_LE SG_ 2151931904 AWDRecmndIO 1;
BA_REL_ "GenSigSuprvResp" BU_SG_REL_ VCU_LE SG_ 2150244352 ECHGDDV_Col10 1;
BA_REL_ "GenSigSuprvResp" BU_SG_REL_ CSM_LE SG_ 2150244352 ECHGDDV_Col10 1;
BA_REL_ "GenSigSuprvResp" BU_SG_REL_ RadioHead_LE SG_ 2150244352 ECHGDDV_Col10 1;
BA_REL_ "GenSigSuprvResp" BU_SG_REL_ VCU_LE SG_ 2150244352 ECHGDDV_Col9 1;
BA_REL_ "GenSigSuprvResp" BU_SG_REL_ CSM_LE SG_ 2150244352 ECHGDDV_Col9 1;
BA_REL_ "GenSigSuprvResp" BU_SG_REL_ RadioHead_LE SG_ 2150244352 ECHGDDV_Col9 1;
BA_REL_ "GenSigSuprvResp" BU_SG_REL_ VCU_LE SG_ 2150244352 ECHGDDV_Col8 1;
BA_REL_ "GenSigSuprvResp" BU_SG_REL_ CSM_LE SG_ 2150244352 ECHGDDV_Col8 1;
BA_REL_ "GenSigSuprvResp" BU_SG_REL_ RadioHead_LE SG_ 2150244352 ECHGDDV_Col8 1;
BA_REL_ "GenSigSuprvResp" BU_SG_REL_ VCU_LE SG_ 2150244352 ECHGDDV_Col7 1;
BA_REL_ "GenSigSuprvResp" BU_SG_REL_ CSM_LE SG_ 2150244352 ECHGDDV_Col7 1;
BA_REL_ "GenSigSuprvResp" BU_SG_REL_ RadioHead_LE SG_ 2150244352 ECHGDDV_Col7 1;
BA_REL_ "GenSigSuprvResp" BU_SG_REL_ VCU_LE SG_ 2150244352 ECHGDDV_Col6 1;
BA_REL_ "GenSigSuprvResp" BU_SG_REL_ CSM_LE SG_ 2150244352 ECHGDDV_Col6 1;
BA_REL_ "GenSigSuprvResp" BU_SG_REL_ RadioHead_LE SG_ 2150244352 ECHGDDV_Col6 1;
BA_REL_ "GenSigSuprvResp" BU_SG_REL_ VCU_LE SG_ 2150244352 ECHGDDV_Col5 1;
BA_REL_ "GenSigSuprvResp" BU_SG_REL_ CSM_LE SG_ 2150244352 ECHGDDV_Col5 1;
BA_REL_ "GenSigSuprvResp" BU_SG_REL_ RadioHead_LE SG_ 2150244352 ECHGDDV_Col5 1;
BA_REL_ "GenSigSuprvResp" BU_SG_REL_ VCU_LE SG_ 2150244352 ECHGDDV_Col4 1;
BA_REL_ "GenSigSuprvResp" BU_SG_REL_ CSM_LE SG_ 2150244352 ECHGDDV_Col4 1;
BA_REL_ "GenSigSuprvResp" BU_SG_REL_ RadioHead_LE SG_ 2150244352 ECHGDDV_Col4 1;
BA_REL_ "GenSigSuprvResp" BU_SG_REL_ VCU_LE SG_ 2150244352 ECHGDDV_Col3 1;
BA_REL_ "GenSigSuprvResp" BU_SG_REL_ CSM_LE SG_ 2150244352 ECHGDDV_Col3 1;
BA_REL_ "GenSigSuprvResp" BU_SG_REL_ RadioHead_LE SG_ 2150244352 ECHGDDV_Col3 1;
BA_REL_ "GenSigSuprvResp" BU_SG_REL_ VCU_LE SG_ 2150244352 ECHGDDV_Col2 1;
BA_REL_ "GenSigSuprvResp" BU_SG_REL_ CSM_LE SG_ 2150244352 ECHGDDV_Col2 1;
BA_REL_ "GenSigSuprvResp" BU_SG_REL_ RadioHead_LE SG_ 2150244352 ECHGDDV_Col2 1;
BA_REL_ "GenSigSuprvResp" BU_SG_REL_ VCU_LE SG_ 2150244352 ECHGDDV_Col1 1;
BA_REL_ "GenSigSuprvResp" BU_SG_REL_ CSM_LE SG_ 2150244352 ECHGDDV_Col1 1;
BA_REL_ "GenSigSuprvResp" BU_SG_REL_ RadioHead_LE SG_ 2150244352 ECHGDDV_Col1 1;
BA_REL_ "GenSigSuprvResp" BU_SG_REL_ VCU_LE SG_ 2150244352 ECHGDDV_EngyConsAvg 1;
BA_REL_ "GenSigSuprvResp" BU_SG_REL_ CSM_LE SG_ 2150244352 ECHGDDV_EngyConsAvg 1;
BA_REL_ "GenSigSuprvResp" BU_SG_REL_ RadioHead_LE SG_ 2150244352 ECHGDDV_EngyConsAvg 1;
VAL_ 2152046592 RmClmCtrlLtSTempStReq 38 "14 CELCIUS" 37 "14.5 CELCIUS" 36 "15 CELCIUS" 35 "15.5 CELCIUS" 34 "16 CELCIUS" 33 "HI" 32 "LO" 31 "31.5 CELCIUS" 30 "31 CELCIUS" 29 "30.5 CELCIUS" 28 "30 CELCIUS" 27 "29.5 CELCIUS" 26 "29 CELCIUS" 25 "28.5 CELCIUS" 24 "28 CELCIUS" 23 "27.5 CELCIUS" 22 "27 CELCIUS" 21 "26.5 CELCIUS" 20 "26 CELCIUS" 19 "25.5 CELCIUS" 18 "25 CELCIUS" 17 "24.5 CELCIUS" 16 "24 CELCIUS" 15 "23.5 CELCIUS" 14 "23 CELCIUS" 13 "22.5 CELCIUS" 12 "22 CELCIUS" 11 "21.5 CELCIUS" 10 "21 CELCIUS" 9 "20.5 CELCIUS" 8 "20 CELCIUS" 7 "19.5 CELCIUS" 6 "19 CELCIUS" 5 "18.5 CELCIUS" 4 "18 CELCIUS" 3 "17.5 CELCIUS" 2 "17 CELCIUS" 1 "16.5 CELCIUS" 0 "No Action" ;
VAL_ 2152046592 RmClmCtrlRtSTempStReq 38 "14 CELCIUS" 37 "14.5 CELCIUS" 36 "15 CELCIUS" 35 "15.5 CELCIUS" 34 "16 CELCIUS" 33 "HI" 32 "LO" 31 "31.5 CELCIUS" 30 "31 CELCIUS" 29 "30.5 CELCIUS" 28 "30 CELCIUS" 27 "29.5 CELCIUS" 26 "29 CELCIUS" 25 "28.5 CELCIUS" 24 "28 CELCIUS" 23 "27.5 CELCIUS" 22 "27 CELCIUS" 21 "26.5 CELCIUS" 20 "26 CELCIUS" 19 "25.5 CELCIUS" 18 "25 CELCIUS" 17 "24.5 CELCIUS" 16 "24 CELCIUS" 15 "23.5 CELCIUS" 14 "23 CELCIUS" 13 "22.5 CELCIUS" 12 "22 CELCIUS" 11 "21.5 CELCIUS" 10 "21 CELCIUS" 9 "20.5 CELCIUS" 8 "20 CELCIUS" 7 "19.5 CELCIUS" 6 "19 CELCIUS" 5 "18.5 CELCIUS" 4 "18 CELCIUS" 3 "17.5 CELCIUS" 2 "17 CELCIUS" 1 "16.5 CELCIUS" 0 "No Action" ;
VAL_ 2152046592 RmClmCtrlFrntFanStReq 20 "AUTO" 19 "MAN 18" 18 "MAN 17" 17 "MAN 16" 16 "MAN 15" 15 "MAN 14" 14 "MAN 13" 13 "MAN 12" 12 "MAN 11" 11 "MAN 10" 10 "MAN 9" 9 "MAN 8" 8 "MAN 7" 7 "MAN 6" 6 "MAN 5" 5 "MAN 4" 4 "MAN 3" 3 "MAN 2" 2 "MAN 1" 1 "OFF" 0 "No Action" ;
VAL_ 2152046592 RmClmCtrlFLAirDtStReq 15 "E TRI LEVEL" 14 "E PANEL" 13 "E DEFOG" 12 "E DEDFROST" 11 "TRI LEVEL" 10 "DEFOG" 9 "ECO" 8 "PURGE" 7 "AC" 6 "BI LEVEL" 5 "HEATER DEFROST" 4 "HEATER" 3 "DEFROST" 2 "AUTO" 1 "OFF" 0 "No Action" ;
VAL_ 2152046592 RmClmCtrlACSetReq 6 "Battery AC On" 5 "ECO AC on" 4 "Comfort AC On" 3 "Auto AC On" 2 "Active" 1 "Inactive" 0 "No Action" ;
VAL_ 2152046592 RmClmCtrlClmModSetReq 8 "Comfort Heat" 7 "Comfort AC" 6 "Battery AC On" 5 "Auto" 4 "Active" 3 "Fan Only" 2 "Economy" 1 "Comfort" 0 "No Action" ;
VAL_ 2152046592 RmClmCtrlRcrcSetReq 4 "Inactive" 3 "Auto Recirculation" 2 "Recirculation" 1 "Fresh" 0 "No Action" ;
VAL_ 2152046592 RmClmCtrlRrDfgSetReq 2 "Inactive" 1 "Active" 0 "No Action" ;
VAL_ 2152046592 RmClmCtrlSyncSetReq 2 "Dual Zone Climate Control" 1 "Single Zone Climate Control" 0 "No Action" ;
VAL_ 2152046592 RmClmCtrlHMIActIndReq 1 "Active" 0 "Inactive" ;
VAL_ 2152030208 TnrFrqBndReq 15 "Unused and Reserved10" 14 "Unused and Reserved9" 13 "Unused and Reserved8" 12 "Unused and Reserved7" 11 "Unused and Reserved6" 10 "Unused and Reserved5" 9 "Unused and Reserved4" 8 "Unused and Reserved3" 7 "Unused and Reserved2" 6 "Unused and Reserved1" 5 "XM" 4 "DAB" 3 "FM" 2 "AM" 1 "Off" 0 "No Action" ;
VAL_ 2150531072 OBHVDCCCpltnTmDspFrmt 3 "Ununsed and Reserved 1" 2 "Display Remaining Minutes To Complete" 1 "Display Completion Time" 0 "No Action" ;
VAL_ 2150531072 ClsHdToStrtVehIO 1 "true" 0 "false" ;
VAL_ 2150531072 HVBChrgLmtBtnDspStat 2 "Do Not Disp Charge Limit Button" 1 "Display Charge Limit Button" 0 "No Action" ;
VAL_ 2150531072 HVBHmChrgTmDspStat 4 "Display Master Setting" 3 "Display Both Cord and Station" 2 "Display Charge Station Charge Value" 1 "Display Portable Cord Charge Value" 0 "No Action" ;
VAL_ 2150531072 HVBChrgTmDspStat 3 "Display Both Cord and Station" 2 "Display Charge Station Charge Value" 1 "Display Portable Cord Charge Value" 0 "No Action" ;
VAL_ 2150531072 HVBChrgOvrdBtnDspStat 2 "Do Not Display Charge Override Button" 1 "Display Charge Override Button" 0 "No Action" ;
VAL_ 2150531072 RegPwrLmtdIO 1 "true" 0 "false" ;
VAL_ 2150531072 RegPwrLmtdDspPrcntVs 1 "true" 0 "false" ;
VAL_ 2153897984 RunBrdExtdFtrAvail 1 "true" 0 "false" ;
VAL_ 2153897984 RunBrdOpMdCstCurrStVal 7 "Unused and Reserved 4" 6 "Unused and Reserved 3" 5 "Unused and Reserved 2" 4 "Unused and Reserved 1" 3 "Extended" 2 "On" 1 "Off" 0 "No Action" ;
VAL_ 2153897984 RunBrdOpMdCstStAvail 1 "true" 0 "false" ;
VAL_ 2151202816 AuxHtrAlwd 1 "true" 0 "false" ;
VAL_ 2151202816 IPSnsrTpCvrTempFltd 1 "true" 0 "false" ;
VAL_ 2151202816 IPSnsrSolrAnglFltd 1 "true" 0 "false" ;
VAL_ 2151202816 IPSnsrRwSolrIntFltd 1 "true" 0 "false" ;
VAL_ 2151202816 ILSSCommErr 1 "Comm Error Detected" 0 "No Comm Error" ;
VAL_ 2151202816 RrWndDfgSwAtv 1 "true" 0 "false" ;
VAL_ 2151202816 RrWndDfgInhRq 1 "Inhibit rear window defog" 0 "Allow rear window defog" ;
VAL_ 2151702528 LnMrkngIndRgt 3 "Unused and Reserved 1" 2 "Green Indicator" 1 "White Indicator" 0 "Indicator Off" ;
VAL_ 2151702528 LnMrkngIndLft 3 "Unused and Reserved 1" 2 "Green Indicator" 1 "White Indicator" 0 "Indicator Off" ;
VAL_ 2151702528 LnKepAsstStIndRgt 7 "Unused and Reserved 2" 6 "Unused and Reserved 1" 5 "Yellow Indicator" 4 "Red Indicator" 3 "Blue Indicator" 2 "Green Indicator" 1 "White Indicator" 0 "Indicator Off" ;
VAL_ 2151702528 LnKepAsstStIndLft 7 "Unused and Reserved 2" 6 "Unused and Reserved 1" 5 "Yellow Indicator" 4 "Red Indicator" 3 "Blue Indicator" 2 "Green Indicator" 1 "White Indicator" 0 "Indicator Off" ;
VAL_ 2151702528 LnKpngAstRecfblIndRq 7 "Unused and Reserved 2" 6 "Unused and Reserved 1" 5 "Yellow Solid Indicator" 4 "Yellow Flashing Indicator" 3 "Blue Solid Indicator" 2 "Green Solid Indicator" 1 "White Solid Indicator" 0 "Indicator Off" ;
VAL_ 2151923712 HLOCCA_Res4Avail 1 "true" 0 "false" ;
VAL_ 2151923712 HLOCCA_Res3Avail 1 "true" 0 "false" ;
VAL_ 2151923712 HLOCCA_Res2Avail 1 "true" 0 "false" ;
VAL_ 2151923712 HLOCCA_Res1Avail 1 "true" 0 "false" ;
VAL_ 2151923712 HLOCCA_OnOpnOnlyAvail 1 "true" 0 "false" ;
VAL_ 2151923712 HLOCCA_OnAvail 1 "true" 0 "false" ;
VAL_ 2151923712 HLOCCA_OffAvail 1 "true" 0 "false" ;
VAL_ 2151923712 HLOCCstSetAvail 1 "true" 0 "false" ;
VAL_ 2151923712 HLOCCstCurrSetVal 3 "On Open Only" 2 "On" 1 "Off" 0 "No Action" ;
VAL_ 2151923712 A1ERRAlrmReq 2 "Cancel Alarm" 1 "Set Alarm" 0 "No Action" ;
VAL_ 2150236160 UlckKyStrCrptoDt2M 1 "Use Data" 0 "Dont Use Data" ;
VAL_ 2150170624 UlckKyStrCrptoDt1M 1 "Use Data" 0 "Dont Use Data" ;
VAL_ 2152628224 OBTCMstrStat 3 "Off Board Tester Present" 2 "Active" 1 "Inactive" 0 "Unknown" ;
VAL_ 2152628224 OBTCR_Stat 3 "Revoked" 2 "Denied" 1 "Accepted" 0 "No Action" ;
VAL_ 2154725376 AuxHtrAtv378 1 "true" 0 "false" ;
VAL_ 2154725376 AuxHtrRq 1 "On" 0 "Off" ;
VAL_ 2157051904 WSMR_WiFiAssnReq 3 "Unexpected Undefined Connection Behavior" 2 "Wi Fi association failed with available credentials" 1 "Failed to receive Wi Fi credentials after 255 attempts" 0 "SSID and Passphrase Request" ;
VAL_ 2156994560 WAPDM_SecurityType 3 "WPA2 (WiFi Protected Access 2)" 4 "IEEE802.1X (Institute of Electrical and Electronics Engineers)" 0 "Open" 1 "WEP (Wired Equivalent Privacy)" 2 "WPA (WiFi Protected Access)" ;
VAL_ 2156994560 WAPDM_WiFiEnStat 0 "Disabled" 1 "Enabled" ;
VAL_ 2156994560 WAPDM_EncrptnType 0 "Open" 1 "AES (Advanced Encryption Standard)" 2 "TKIP (Temporal Key Integrity Protocol)" 3 "AES or TKIP" ;
VAL_ 2158133248 ChrgCmpltFstChgingAct 1 "true" 0 "false" ;
VAL_ 2158133248 TrgtChrgLvlAct 1 "true" 0 "false" ;
VAL_ 2158133248 HTRCsStAvail 1 "true" 0 "false" ;
VAL_ 2158133248 HTRCsCrStVal 4 "On Away" 3 "On Home" 2 "On" 1 "Off" 0 "No Action" ;
VAL_ 2158133248 HTRCA_Res3Avail 1 "true" 0 "false" ;
VAL_ 2158133248 HTRCA_Res2Avail 1 "true" 0 "false" ;
VAL_ 2158133248 HTRCA_Res1Avail 1 "true" 0 "false" ;
VAL_ 2158133248 HTRCA_OnAwAvail 1 "true" 0 "false" ;
VAL_ 2158133248 HTRCA_OnHmAvail 1 "true" 0 "false" ;
VAL_ 2158133248 HTRCA_OnAvail 1 "true" 0 "false" ;
VAL_ 2158133248 HTRCA_OffAvail 1 "true" 0 "false" ;
VAL_ 2154651648 TAC_AudConctOutcm 15 "Unused And Reserved 13" 14 "Unused And Reserved 12" 13 "Unused And Reserved 11" 12 "Unused And Reserved 10" 11 "Unused And Reserved 9" 10 "Unused And Reserved 8" 9 "Unused And Reserved 7" 8 "Unused And Reserved 6" 7 "Unused And Reserved 5" 6 "Unused And Reserved 4" 5 "Unused And Reserved 3" 4 "Unused And Reserved 2" 3 "Unused And Reserved 1" 2 "Request Denied" 1 "Request Granted" 0 "No Action" ;
VAL_ 2154651648 TAC_AudChConctStat 15 "Unused And Reserved 10" 14 "Unused And Reserved 9" 13 "Unused And Reserved 8" 12 "Unused And Reserved 7" 11 "Unused And Reserved 6" 10 "Unused And Reserved 5" 9 "Unused And Reserved 4" 8 "Unused And Reserved 3" 7 "Unused And Reserved 2" 6 "Unused And Reserved 1" 5 "Emergency Phone" 4 "Phone" 3 "Ring Tone" 2 "Mutex Prompt" 1 "Mix Prompt" 0 "No Action" ;
VAL_ 2154635264 TAR_AudSrcStat 15 "Unused And Reserved 11" 14 "Unused And Reserved 10" 13 "Unused And Reserved 9" 12 "Unused And Reserved 8" 11 "Unused And Reserved 7" 10 "Unused And Reserved 6" 9 "Unused And Reserved 5" 8 "Unused And Reserved 4" 7 "Unused And Reserved 3" 6 "Unused And Reserved 2" 5 "Unused And Reserved 1" 4 "Audio Disconnect" 3 "Audio Request" 2 "Audio Playing" 1 "Audio Ready" 0 "No Action" ;
VAL_ 2154635264 TAR_AudConctReq 13 "Unused And Reserved 8" 12 "Unused And Reserved 7" 11 "Unused And Reserved 6" 10 "Unused And Reserved 5" 9 "Unused And Reserved 4" 8 "Unused And Reserved 3" 7 "Unused And Reserved 2" 6 "Unused And Reserved 1" 5 "Emergency Phone" 4 "Phone" 3 "Ring Tone" 2 "Mutex Prompt" 1 "Mix Prompt" 0 "No Action" 15 "Unused And Reserved 10" 14 "Unused And Reserved 9" ;
VAL_ 2152529920 LVMAVC_SpchRcgnAval 3 "Unused and Reserved 2" 2 "Unused and Reserved 1" 1 "Available" 0 "No Action" ;
VAL_ 2152529920 LVMAVC_RemSpchRcgnActn 3 "End Button Press" 2 "PTT Button Press" 1 "Activate LVM_SR" 0 "No Action" ;
VAL_ 2152529920 LVMAVC_RemSpchRcgnID 7 "Unused and Reserved 4" 6 "Unused and Reserved 3" 5 "Unused and Reserved 2" 4 "Unused and Reserved 1" 3 "LVM PDR" 2 "LVM DMB" 1 "LVM NAV" 0 "No Action" ;
VAL_ 2152529920 LVMAVC_StreoAudRsp 3 "Unused and Reserved 2" 2 "Unused and Reserved 1" 1 "Active" 0 "No Action" ;
VAL_ 2152529920 LVMAVC_PrmtAudRsp 3 "Unused and Reserved 2" 2 "Unused and Reserved 1" 1 "Active" 0 "No Action" ;
VAL_ 2152529920 LVMAVC_RemtEnbl 7 "Unused and Reserved 5" 6 "Unused and Reserved 4" 5 "Unused and Reserved 3" 4 "Unused and Reserved 2" 3 "Unused and Reserved 1" 2 "Remote Enable Active" 1 "Remote Enable On" 0 "No Action" ;
VAL_ 2152513536 LVMAVR_SpchRcgnAct 3 "Unused and Reserved 1" 2 "LVM Speech Rec Active" 1 "LVM Speech Rec Ready" 0 "No Action" ;
VAL_ 2152513536 LVMAVR_PrmtAudReq 3 "Unused and Reserved 2" 2 "Unused and Reserved 1" 1 "Prompt Request" 0 "No Action" ;
VAL_ 2152513536 LVMAVR_StreoAudReq 3 "Unused and Reserved 2" 2 "Unused and Reserved 1" 1 "Stereo Request" 0 "No Action" ;
VAL_ 2152513536 LVMAVR_DispReq 7 "Unused and Reserved 4" 6 "Unused and Reserved 3" 5 "Unused and Reserved 2" 4 "Unused and Reserved 1" 3 "LVM PDR" 2 "LVM DMB" 1 "LVM NAV" 0 "No Action" ;
VAL_ 2154889216 RSIHMIAnmReq 7 "Unused and Reserved 3" 6 "Unused and Reserved 2" 5 "Unused and Reserved 1" 4 "Shutdown Play" 3 "Start Play" 2 "Welcome Play" 1 "Ready" 0 "Uninitialized" ;
VAL_ 2154889216 ClstrHMIAnmReq 7 "Unused and Reserved 3" 6 "Unused and Reserved 2" 5 "Unused and Reserved 1" 4 "Shutdown Play" 3 "Start Play" 2 "Welcome Play" 1 "Ready" 0 "No Action" ;
VAL_ 2154872832 RmRflshUpdtAvail 1 "true" 0 "false" ;
VAL_ 2154872832 InfoActvnReq 1 "true" 0 "false" ;
VAL_ 2154569728 InfotnmntSysSt 31 " Unused and Reserved 15" 30 " Unused and Reserved 14" 29 " Unused and Reserved 13" 28 " Unused and Reserved 12" 27 " Unused and Reserved 11" 26 " Unused and Reserved 10" 25 " Unused and Reserved 9" 24 " Unused and Reserved 8" 23 " Unused and Reserved 7" 22 " Unused and Reserved 6" 21 " Unused and Reserved 5" 20 " Unused and Reserved 4" 19 " Unused and Reserved 3" 18 " Unused and Reserved 2" 17 " Unused and Reserved 1" 16 " Remote Reflash Programming" 15 " No VIN" 14 " No Calibration" 13 " Theftlocked" 12 " Valet Mode" 11 " Local Eject" 10 " Local Valet" 9 " Local Phone" 8 " Local Infotainment" 7 " Accessory" 6 " Propulsion" 5 " Run" 4 " Start" 3 " HMI Inactive" 2 " HMI Init" 1 " Animation Init" 0 " Sleep" ;
VAL_ 2154594304 InfotnBkltngConfigSt 2 "LOCAL" 1 "ON" 0 "OFF" ;
VAL_ 2154594304 ASTC_GblAudSnkMut 1 "true" 0 "false" ;
VAL_ 2154594304 ASTC_AmpLwPwrSt 1 "true" 0 "false" ;
VAL_ 2154594304 ASTC_MtxSnkMut 1 "true" 0 "false" ;
VAL_ 2154594304 ASTC_DSPMd 15 "Unused and Reserved 7" 14 "Unused and Reserved 6" 13 "Unused and Reserved 5" 12 "Unused and Reserved 4" 11 "Unused and Reserved 3" 10 "Unused and Reserved 2" 9 "Unused and Reserved 1" 8 "DSP Mode 7" 7 "DSP Mode 6" 6 "DSP Mode 5" 5 "DSP Mode 4" 4 "DSP Mode 3" 3 "DSP Mode 2" 2 "DSP Mode 1" 1 "DSP Mode 0" 0 "No Action" ;
VAL_ 2154594304 ASTC_VehNoisCmpnAct 1 "true" 0 "false" ;
VAL_ 2154594304 ASTC_ChimSnkSpkrPos 15 "Unused and Reserved 7" 14 "Unused and Reserved 6" 13 "Unused and Reserved 5" 12 "Unused and Reserved 4" 11 "Unused and Reserved 3" 10 "Unused and Reserved 2" 9 "Unused and Reserved 1" 8 "Left Rear" 7 "Left Front" 6 "Right Rear" 5 "Right Front" 4 "Full Right" 3 "Full Left" 2 "Full Rear" 1 "Full Front" 0 "No Action" ;
VAL_ 2154586112 ASSLC_AutoLdnsCmpnAct 1 "true" 0 "false" ;
VAL_ 2154586112 ASSLC_VcSrcActOnMtx 1 "true" 0 "false" ;
VAL_ 2154577920 ASS_DSPMd7Prsnt 1 "true" 0 "false" ;
VAL_ 2154577920 ASS_DSPMd6Prsnt 1 "true" 0 "false" ;
VAL_ 2154577920 ASS_DSPMd5Prsnt 1 "true" 0 "false" ;
VAL_ 2154577920 ASS_DSPMd4Prsnt 1 "true" 0 "false" ;
VAL_ 2154577920 ASS_DSPMd3Prsnt 1 "true" 0 "false" ;
VAL_ 2154577920 ASS_DSPMd2Prsnt 1 "true" 0 "false" ;
VAL_ 2154577920 ASS_DSPMd1Prsnt 1 "true" 0 "false" ;
VAL_ 2154577920 ASS_DSPMd0Prsnt 1 "true" 0 "false" ;
VAL_ 2154577920 ASS_SurndAvail 1 "true" 0 "false" ;
VAL_ 2154577920 ASS_DSPAvail 1 "true" 0 "false" ;
VAL_ 2154577920 ASS_VehNoisCmpnAvail 1 "true" 0 "false" ;
VAL_ 2154577920 ASS_PhLckdLpLckd 1 "true" 0 "false" ;
VAL_ 2154577920 ASS_MtxSnkMutStat 1 "true" 0 "false" ;
VAL_ 2151931904 FourWhlDrvIdReqExtRng 15 "Front Wheel Drive Mode Active" 14 "Front Wheel Drive Mode Pending" 13 "AWD Connected Mode Active" 12 "AWD Connected Mode Pending" 11 "Position Undetermined Active" 10 "Transfer Case Neutral Active" 9 "Transfer Case Neutral Pending" 8 "Four Wheel Drive Low Lock Active" 7 "Four Wheel Drive Low Lock Pending" 6 "Four Wheel Drive High Lock Active" 5 "Four Wheel Drive High Lock Pending" 4 "Four Wheel Drive High Auto Active" 3 "Four Wheel Drive High Auto Pending" 2 "Two Wheel Drive High Active" 1 "Two Wheel Drive High Pending" 0 "No Indication" ;
VAL_ 2151931904 FuelMdTrnstnIndReq 15 "Unused and Reserved 9" 14 "Unused and Reserved 8" 13 "Unused and Reserved 7" 12 "Unused and Reserved 6" 11 "Unused and Reserved 5" 10 "Unused and Reserved 4" 9 "Unused and Reserved 3" 8 "Unused and Reserved 2" 7 "Unused and Reserved 1" 6 "Indication 6" 5 "Indication 5" 4 "Indication 4" 3 "Indication 3" 2 "Indication 2" 1 "Indication 1" 0 "No Indication" ;
VAL_ 2151931904 BiFuelRflGaslinIndReq 7 "Unused and Reserved 5" 6 "Unused and Reserved 4" 5 "Unused and Reserved 3" 4 "Unused and Reserved 2" 3 "Unused and Reserved 1" 2 "Indication 2" 1 "Indication 1" 0 "No Indication" ;
VAL_ 2151931904 AutoShtdwnIO 1 "true" 0 "false" ;
VAL_ 2151931904 TCSTempDsblReqIO 1 "true" 0 "false" ;
VAL_ 2151931904 VehStbCmptvMdCstAvl 1 "true" 0 "false" ;
VAL_ 2151931904 VehStbEnmntCstAvl 1 "true" 0 "false" ;
VAL_ 2151931904 TCSysCstAvl 1 "true" 0 "false" ;
VAL_ 2151931904 VehStbCmptvMdCurSt 1 "On" 0 "Off" ;
VAL_ 2151931904 VehStbEnhmntCurSt 1 "On" 0 "Off" ;
VAL_ 2151931904 TCSysCurSt 1 "On" 0 "Off" ;
VAL_ 2151931904 TracAndStbScrnCnfg 3 "TCS ESC and Comp" 2 "TCS and ESC" 1 "TCS Only" 0 "None" ;
VAL_ 2151931904 ElctShfPriLtdPerfMdIO 1 "true" 0 "false" ;
VAL_ 2151931904 LnchCtrlEngRPMStat 0 "No Action" 63 "Unused and Reserved 30" 62 "Unused and Reserved 29" 61 "Unused and Reserved 28" 60 "Unused and Reserved 27" 59 "Unused and Reserved 26" 58 "Unused and Reserved 25" 57 "Unused and Reserved 24" 56 "Unused and Reserved 23" 55 "Unused and Reserved 22" 54 "Unused and Reserved 21" 53 "Unused and Reserved 20" 52 "Unused and Reserved 19" 51 "Unused and Reserved 18" 50 "Unused and Reserved 17" 49 "Unused and Reserved 16" 48 "Unused and Reserved 15" 47 "Unused and Reserved 14" 46 "Unused and Reserved 13" 45 "Unused and Reserved 12" 44 "Unused and Reserved 11" 43 "Unused and Reserved 10" 42 "Unused and Reserved 9" 41 "Unused and Reserved 8" 40 "Unused and Reserved 7" 39 "Unused and Reserved 6" 38 "Unused and Reserved 5" 37 "Unused and Reserved 4" 36 "Unused and Reserved 3" 35 "Unused and Reserved 2" 34 "Unused and Reserved 1" 33 "4000" 32 "3900" 31 "3800" 30 "3700" 29 "3600" 28 "3500" 27 "3400" 26 "3300" 25 "3200" 24 "3100" 23 "3000" 22 "2900" 21 "2800" 20 "2700" 19 "2600" 18 "2500" 17 "2400" 16 "2300" 15 "2200" 14 "2100" 13 "2000" 12 "1900" 11 "1800" 10 "1700" 9 "1600" 8 "1500" 7 "1400" 6 "1300" 5 "1200" 4 "1100" 3 "1000" 2 "900" 1 "800" ;
VAL_ 2151931904 RegVltCtlEngyRcvryAct 1 "true" 0 "false" ;
VAL_ 2151931904 VehSpdCntlSystmType 2 "Adaptive Cruise Control" 1 "Conventional Cruise Control" 0 "No Vehicle Speed Control" ;
VAL_ 2151931904 ACCSysSltdMdDispIO 1 "true" 0 "false" ;
VAL_ 2151931904 ACCSysSltdMd 3 "Unused And Reserved" 2 "Enhanced Cruise Control" 1 "Adaptive Cruise Control" 0 "Cruise Control Mode Switching Not Supported" ;
VAL_ 2151931904 PTExPrtclFltWrng3IO 1 "true" 0 "false" ;
VAL_ 2151931904 PTExPartFltManRegStat 7 "Do not press pedals" 6 "Not available" 5 "Pending Driver Input" 4 "Complete" 3 "In Progress" 2 "Not Allowed" 1 "Allowed" 0 "Cleaning Not Required" ;
VAL_ 2151931904 LnchCtrlWhlSlpStat 31 "Unused and Reserved 10" 30 "Unused and Reserved 9" 29 "Unused and Reserved 8" 28 "Unused and Reserved 7" 27 "Unused and Reserved 6" 26 "Unused and Reserved 5" 25 "Unused and Reserved 4" 24 "Unused and Reserved 3" 23 "Unused and Reserved 2" 22 "Unused and Reserved 1" 21 "Fifteen Percent" 20 "Fourteen And A Half Percent" 19 "Fourteen Percent" 18 "Thirteen And A Half Percent" 17 "Thirteen Percent" 16 "Twelve And A Half Percent" 15 "Twelve Percent" 14 "Eleven And a Half Percent" 13 "Eleven Percent" 12 "Ten And A Half Percent" 11 "Ten Percent" 10 "Nine And A Half Percent" 9 "Nine Percent" 8 "Eight And A Half Percent" 7 "Eight Percent" 6 "Seven And A Half Percent" 5 "Seven Percent" 4 "Six And A Half Percent" 3 "Six Percent" 2 "Five And A Half Percent" 1 "Five Percent" 0 "No Action" ;
VAL_ 2151931904 LnchCtrlMdStat 7 "Line Lock Release Brake" 6 "Line Lock Press Brake" 5 "Burn Out Or Line Lock" 4 "High Traction Custom" 3 "High Traction" 2 "General Custom" 1 "General" 0 "Disable" ;
VAL_ 2151931904 AWDRecmndIO 1 "true" 0 "false" ;
VAL_ 2151251968 TICS_Ind1V 1 "Invalid" 0 "Valid" ;
VAL_ 2151251968 TICS_Ind1 0 "Red" 1 "Green" 2 "Yellow" ;
VAL_ 2151251968 TICS_Ind1Stat 0 "Off" 1 "Continuous Indication" 2 "Flashing" 3 "Count" ;
VAL_ 2153857024 TDRCADD_WOTEvnts 1 "true" 0 "false" ;
VAL_ 2153857024 TDRCADD_LDWEvnts 1 "true" 0 "false" ;
VAL_ 2153857024 TDRCADD_FCMBrEvts 1 "true" 0 "false" ;
VAL_ 2153857024 TDRCADD_DrwDrvAlrt 1 "true" 0 "false" ;
VAL_ 2153857024 TDRCADD_RCMBrEvts 1 "true" 0 "false" ;
VAL_ 2153857024 TDRCADD_FCImntAlrts 1 "true" 0 "false" ;
VAL_ 2153857024 TDRCADD_FCHdwyAlrt 1 "true" 0 "false" ;
VAL_ 2153857024 TDRCADD_StCtrlEvnts 1 "true" 0 "false" ;
VAL_ 2153857024 TDRCADD_ABSAtvEvt 1 "true" 0 "false" ;
VAL_ 2153857024 TDRCADD_TrCtrlEvnts 1 "true" 0 "false" ;
VAL_ 2153857024 TDRCADD_OvSpdEvnt 1 "true" 0 "false" ;
VAL_ 2153857024 TDRCADD_DistDrvn 1 "true" 0 "false" ;
VAL_ 2153857024 TDRCADD_MaxSpd 1 "true" 0 "false" ;
VAL_ 2153865216 TnDrvStBltShftIntrlkCsStRq 2 "On" 1 "Off" 0 "No Action" ;
VAL_ 2153865216 StBltShftIntrlkCsStRq 2 "On" 1 "Off" 0 "No Action" ;
VAL_ 2153865216 TeenDrvReq 0 "No Action" 1 "Verify Teen PIN" 2 "Update Teen PIN" 3 "Set Teen Key" 4 "Clear Teen Key" 5 "Check for Teen Key" 6 "Clear Teen Keys and PIN" 7 "Reset Report Card" 8 "Request Report Card Data" ;
VAL_ 2153865216 TnDrvSpdLmtCstStReq 0 "No Action" 1 "Off" 2 "On" ;
VAL_ 2153865216 TDOWCSR_StatReq 0 "No Action" 1 "Off" 2 "On" ;
VAL_ 2153865216 TDOWCSR_IncSwAct 1 "true" 0 "false" ;
VAL_ 2153865216 TDOWCSR_DecSwAct 1 "true" 0 "false" ;
SIG_GROUP_ 2151923712 HLOCCstAvail 1 : HLOCCA_Res4Avail HLOCCA_Res3Avail HLOCCA_Res2Avail HLOCCA_Res1Avail HLOCCA_OnOpnOnlyAvail HLOCCA_OnAvail HLOCCA_OffAvail;
SIG_GROUP_ 2151923712 Alrm1ExtRngReq 1 : A1ERRAlrmTime A1ERRAlrmReq;
SIG_GROUP_ 2152628224 OBTCResp 1 : OBTCR_ReqstrID OBTCR_Stat;
SIG_GROUP_ 2157051904 WiFiStatnMpReq 1 : WSMR_WiFiStnMpMACAddr WSMR_WiFiAssnReq;
SIG_GROUP_ 2156994560 WiFiAccsPntData_Mp 1 : WAPDM_SecurityType WAPDM_WiFiEnStat WAPDM_EncrptnType;
SIG_GROUP_ 2158133248 HTRCsAvail 1 : HTRCA_Res3Avail HTRCA_Res2Avail HTRCA_Res1Avail HTRCA_OnAwAvail HTRCA_OnHmAvail HTRCA_OnAvail HTRCA_OffAvail;
SIG_GROUP_ 2154651648 TeleAudCtl 1 : TAC_AudConctOutcm TAC_AudChConctStat;
SIG_GROUP_ 2154635264 TeleAudReq 1 : TAR_AudSrcStat TAR_AudConctReq;
SIG_GROUP_ 2152529920 LowVolModAudVidCmd 1 : LVMAVC_SpchRcgnAval LVMAVC_RemSpchRcgnActn LVMAVC_RemSpchRcgnID LVMAVC_StreoAudRsp LVMAVC_PrmtAudRsp LVMAVC_RemtEnbl;
SIG_GROUP_ 2152513536 LowVolModAudVidReq 1 : LVMAVR_SpchRcgnAct LVMAVR_PrmtAudReq LVMAVR_StreoAudReq LVMAVR_DispReq;
SIG_GROUP_ 2154594304 AmpSetTonCtrl 1 : ASTC_GblAudSnkMut ASTC_AmpLwPwrSt ASTC_MtxSnkMutRmpTm ASTC_MtxSnkMut ASTC_DSPMd ASTC_VehNoisCmpnAct ASTC_SurndLvl ASTC_ChimSnkSpkrPos ASTC_ChimSnkLvl;
SIG_GROUP_ 2154586112 AmpSetSnkLvlCtrl 1 : ASSLC_AutoLdnsCmpnAct ASSLC_VcSrcActOnMtx ASSLC_MtxSnkTrbl ASSLC_MtxSnkMdrng ASSLC_MtxSnkBass ASSLC_MtxSnkFd ASSLC_MtxSnkBal ASSLC_FvSnkLvl ASSLC_AudFdbkSnkLvl ASSLC_MxPrmtSnkLvl ASSLC_MtxSnkLvl;
SIG_GROUP_ 2154577920 AmpSnkStat 1 : ASS_DSPMd7Prsnt ASS_DSPMd6Prsnt ASS_DSPMd5Prsnt ASS_DSPMd4Prsnt ASS_DSPMd3Prsnt ASS_DSPMd2Prsnt ASS_DSPMd1Prsnt ASS_DSPMd0Prsnt ASS_SurndAvail ASS_DSPAvail ASS_VehNoisCmpnAvail ASS_PhLckdLpLckd ASS_MtxSnkMutStat;
SIG_GROUP_ 2150244352 EngyCnsHsGrphDspDtVal 1 : ECHGDDV_Col10 ECHGDDV_Col9 ECHGDDV_Col8 ECHGDDV_Col7 ECHGDDV_Col6 ECHGDDV_Col5 ECHGDDV_Col4 ECHGDDV_Col3 ECHGDDV_Col2 ECHGDDV_Col1 ECHGDDV_EngyConsAvg;
SIG_GROUP_ 2151251968 TlmtcsIndCntrlStat 1 : TICS_Ind1V TICS_Ind1FlshRtOnSt TICS_Ind1FlshRtOffSt TICS_Ind1 TICS_Ind1Stat;
SIG_GROUP_ 2153857024 TnDrvRptCrdAvlDspDat 1 : TDRCADD_WOTEvnts TDRCADD_LDWEvnts TDRCADD_FCMBrEvts TDRCADD_DrwDrvAlrt TDRCADD_RCMBrEvts TDRCADD_FCImntAlrts TDRCADD_FCHdwyAlrt TDRCADD_StCtrlEvnts TDRCADD_ABSAtvEvt TDRCADD_TrCtrlEvnts TDRCADD_OvSpdEvnt TDRCADD_DistDrvn TDRCADD_MaxSpd;
SIG_GROUP_ 2153865216 TDOvSpdWrnCstStReq 1 : TDOWCSR_StatReq TDOWCSR_IncSwAct TDOWCSR_DecSwAct;
